VERSION "created by canmatrix"

NS_ :

BS_:

BU_: ARC ADC

BO_ 860 ARC_OD_22_23_RL: 64 ARC
 SG_ DistHeight_Obj_23_RL : 487|8@0+ (0.2,-10) [-10|41] "m"  ADC
 SG_ DistHeight_Obj_22_RL : 479|8@0+ (0.2,-10) [-10|41] "m"  ADC
 SG_ ARC_OD_DistX_Obj_22_RL : 7|12@0+ (0.1,-152) [-152|257.5] "m"  ADC
 SG_ ARC_OD_Classification_Obj_22_RL : 98|3@0+ (1,0) [0|7] ""  ADC
 SG_ ARC_OD_AabsYStd_Obj_22_RL : 111|8@0+ (0.25,0) [0|63.75] "m/s^2"  ADC
 SG_ ARC_OD_ClassConf_Obj_22_RL : 119|7@0+ (1,0) [0|127] "%"  ADC
 SG_ ARC_OD_ProbOfExist_Obj_22_RL : 112|7@0+ (1,0) [0|127] "%"  ADC
 SG_ ARC_OD_VabsX_Obj_22_RL : 11|11@0+ (0.125,-128) [-128|127.875] "m/s"  ADC
 SG_ ARC_OD_DynProp_Obj_22_RL : 130|3@0+ (1,0) [0|7] ""  ADC
 SG_ ARC_OD_Length_Obj_22_RL : 136|7@0+ (0.2,0) [0|25.4] "m"  ADC
 SG_ ARC_OD_MaintenanceState_Obj_0083 : 145|2@0+ (1,0) [0|3] ""  ADC
 SG_ ARC_OD_Width_Obj_22_RL : 159|7@0+ (0.2,0) [0|25.4] "m"  ADC
 SG_ ARC_OD_RCS_Obj_22_RL : 152|9@0+ (0.2,-51.1) [-51.1|51.1] "dBsm"  ADC
 SG_ ARC_OD_Orientation_Obj_22_RL : 175|10@0+ (0.01,-5.11) [-5.11|5.12] "rad"  ADC
 SG_ ARC_OD_LifeCycle_Obj_22_RL : 207|16@0+ (1,0) [0|65535] ""  ADC
 SG_ ARC_OD_DistX_Obj_23_RL : 223|12@0+ (0.1,-152) [-152|257.5] "m"  ADC
 SG_ ARC_OD_VabsX_Obj_23_RL : 227|11@0+ (0.125,-128) [-128|127.875] "m/s"  ADC
 SG_ ARC_OD_AabsX_Obj_23_RL : 232|9@0+ (0.125,-31.875) [-31.875|32] "m/s^2"  ADC
 SG_ ARC_OD_AabsX_Obj_22_RL : 16|9@0+ (0.125,-31.875) [-31.875|32] "m/s^2"  ADC
 SG_ ARC_OD_DistY_Obj_23_RL : 255|12@0+ (0.0875,-179.113) [-179.113|179.2] "m"  ADC
 SG_ ARC_OD_VabsY_Obj_23_RL : 259|11@0+ (0.125,-128) [-128|127.875] "m/s"  ADC
 SG_ ARC_OD_AabsY_Obj_23_RL : 264|9@0+ (0.125,-31.875) [-31.875|32] "m/s^2"  ADC
 SG_ ARC_OD_DistXStd_Obj_23_RL : 287|8@0+ (0.05,0) [0|12.75] "m"  ADC
 SG_ ARC_OD_DistYStd_Obj_23_RL : 295|8@0+ (0.1,0) [0|25.5] "m"  ADC
 SG_ ARC_OD_VabsXStd_Obj_23_RL : 303|7@0+ (0.1,0) [0|12.7] "m/s"  ADC
 SG_ ARC_OD_VabsYStd_Obj_23_RL : 296|7@0+ (0.2,0) [0|25.4] "m/s"  ADC
 SG_ ARC_OD_AabsXStd_Obj_23_RL : 305|7@0+ (0.25,0) [0|31.75] "m/s^2"  ADC
 SG_ ARC_OD_Classification_Obj_23_RL : 314|3@0+ (1,0) [0|7] ""  ADC
 SG_ ARC_OD_AabsYStd_Obj_23_RL : 327|8@0+ (0.25,0) [0|63.75] "m/s^2"  ADC
 SG_ ARC_OD_ClassConf_Obj_23_RL : 335|7@0+ (1,0) [0|127] "%"  ADC
 SG_ ARC_OD_DistY_Obj_22_RL : 39|12@0+ (0.0875,-179.113) [-179.113|179.2] "m"  ADC
 SG_ ARC_OD_ProbOfExist_Obj_23_RL : 328|7@0+ (1,0) [0|127] "%"  ADC
 SG_ ARC_OD_DynProp_Obj_23_RL : 346|3@0+ (1,0) [0|7] ""  ADC
 SG_ ARC_OD_Length_Obj_23_RL : 352|7@0+ (0.2,0) [0|25.4] "m"  ADC
 SG_ ARC_OD_MaintenanceState_Obj_0084 : 361|2@0+ (1,0) [0|3] ""  ADC
 SG_ ARC_OD_Width_Obj_23_RL : 375|7@0+ (0.2,0) [0|25.4] "m"  ADC
 SG_ ARC_OD_RCS_Obj_23_RL : 368|9@0+ (0.2,-51.1) [-51.1|51.1] "dBsm"  ADC
 SG_ ARC_OD_Orientation_Obj_23_RL : 391|10@0+ (0.01,-5.11) [-5.11|5.12] "rad"  ADC
 SG_ ARC_OD_LifeCycle_Obj_23_RL : 423|16@0+ (1,0) [0|65535] ""  ADC
 SG_ ARC_OD_ObstacleProb_Obj_22_RL : 447|7@0+ (1,0) [0|127] "%"  ADC
 SG_ ARC_OD_ObstacleProb_Obj_23_RL : 455|7@0+ (1,0) [0|127] "%"  ADC
 SG_ ARC_OD_VabsY_Obj_22_RL : 43|11@0+ (0.125,-128) [-128|127.875] "m/s"  ADC
 SG_ ARC_OD_ID_22_RL : 463|8@0+ (1,0) [0|255] ""  ADC
 SG_ ARC_OD_ID_23_RL : 471|8@0+ (1,0) [0|255] ""  ADC
 SG_ ARC_OD_MsgCounter_Obj_22_23_RL : 491|4@0+ (1,0) [0|15] ""  ADC
 SG_ ARC_OD_CRC8_Obj_22_23_RL : 511|8@0+ (1,0) [0|256] ""  ADC
 SG_ ARC_OD_AabsY_Obj_22_RL : 48|9@0+ (0.125,-31.875) [-31.875|32] "m/s^2"  ADC
 SG_ ARC_OD_DistXStd_Obj_22_RL : 71|8@0+ (0.05,0) [0|12.75] "m"  ADC
 SG_ ARC_OD_DistYStd_Obj_22_RL : 79|8@0+ (0.1,0) [0|25.5] "m"  ADC
 SG_ ARC_OD_VabsXStd_Obj_22_RL : 87|7@0+ (0.1,0) [0|12.7] "m/s"  ADC
 SG_ ARC_OD_VabsYStd_Obj_22_RL : 80|7@0+ (0.2,0) [0|25.4] "m/s"  ADC
 SG_ ARC_OD_AabsXStd_Obj_22_RL : 89|7@0+ (0.25,0) [0|31.75] "m/s^2"  ADC

BO_ 861 ARC_OD_24_25_RL: 64 ARC
 SG_ DistHeight_Obj_25_RL : 487|8@0+ (0.2,-10) [-10|41] "m"  ADC
 SG_ DistHeight_Obj_24_RL : 479|8@0+ (0.2,-10) [-10|41] "m"  ADC
 SG_ ARC_OD_DistX_Obj_24_RL : 7|12@0+ (0.1,-152) [-152|257.5] "m"  ADC
 SG_ ARC_OD_Classification_Obj_24_RL : 98|3@0+ (1,0) [0|7] ""  ADC
 SG_ ARC_OD_AabsYStd_Obj_24_RL : 111|8@0+ (0.25,0) [0|63.75] "m/s^2"  ADC
 SG_ ARC_OD_ClassConf_Obj_24_RL : 119|7@0+ (1,0) [0|127] "%"  ADC
 SG_ ARC_OD_ProbOfExist_Obj_24_RL : 112|7@0+ (1,0) [0|127] "%"  ADC
 SG_ ARC_OD_VabsX_Obj_24_RL : 11|11@0+ (0.125,-128) [-128|127.875] "m/s"  ADC
 SG_ ARC_OD_DynProp_Obj_24_RL : 130|3@0+ (1,0) [0|7] ""  ADC
 SG_ ARC_OD_Length_Obj_24_RL : 136|7@0+ (0.2,0) [0|25.4] "m"  ADC
 SG_ ARC_OD_MaintenanceState_Obj_0085 : 145|2@0+ (1,0) [0|3] ""  ADC
 SG_ ARC_OD_Width_Obj_24_RL : 159|7@0+ (0.2,0) [0|25.4] "m"  ADC
 SG_ ARC_OD_RCS_Obj_24_RL : 152|9@0+ (0.2,-51.1) [-51.1|51.1] "dBsm"  ADC
 SG_ ARC_OD_Orientation_Obj_24_RL : 175|10@0+ (0.01,-5.11) [-5.11|5.12] "rad"  ADC
 SG_ ARC_OD_LifeCycle_Obj_24_RL : 207|16@0+ (1,0) [0|65535] ""  ADC
 SG_ ARC_OD_DistX_Obj_25_RL : 223|12@0+ (0.1,-152) [-152|257.5] "m"  ADC
 SG_ ARC_OD_VabsX_Obj_25_RL : 227|11@0+ (0.125,-128) [-128|127.875] "m/s"  ADC
 SG_ ARC_OD_AabsX_Obj_25_RL : 232|9@0+ (0.125,-31.875) [-31.875|32] "m/s^2"  ADC
 SG_ ARC_OD_AabsX_Obj_24_RL : 16|9@0+ (0.125,-31.875) [-31.875|32] "m/s^2"  ADC
 SG_ ARC_OD_DistY_Obj_25_RL : 255|12@0+ (0.0875,-179.113) [-179.113|179.2] "m"  ADC
 SG_ ARC_OD_VabsY_Obj_25_RL : 259|11@0+ (0.125,-128) [-128|127.875] "m/s"  ADC
 SG_ ARC_OD_AabsY_Obj_25_RL : 264|9@0+ (0.125,-31.875) [-31.875|32] "m/s^2"  ADC
 SG_ ARC_OD_DistXStd_Obj_25_RL : 287|8@0+ (0.05,0) [0|12.75] "m"  ADC
 SG_ ARC_OD_DistYStd_Obj_25_RL : 295|8@0+ (0.1,0) [0|25.5] "m"  ADC
 SG_ ARC_OD_VabsXStd_Obj_25_RL : 303|7@0+ (0.1,0) [0|12.7] "m/s"  ADC
 SG_ ARC_OD_VabsYStd_Obj_25_RL : 296|7@0+ (0.2,0) [0|25.4] "m/s"  ADC
 SG_ ARC_OD_AabsXStd_Obj_25_RL : 305|7@0+ (0.25,0) [0|31.75] "m/s^2"  ADC
 SG_ ARC_OD_Classification_Obj_25_RL : 314|3@0+ (1,0) [0|7] ""  ADC
 SG_ ARC_OD_AabsYStd_Obj_25_RL : 327|8@0+ (0.25,0) [0|63.75] "m/s^2"  ADC
 SG_ ARC_OD_ClassConf_Obj_25_RL : 335|7@0+ (1,0) [0|127] "%"  ADC
 SG_ ARC_OD_DistY_Obj_24_RL : 39|12@0+ (0.0875,-179.113) [-179.113|179.2] "m"  ADC
 SG_ ARC_OD_ProbOfExist_Obj_25_RL : 328|7@0+ (1,0) [0|127] "%"  ADC
 SG_ ARC_OD_DynProp_Obj_25_RL : 346|3@0+ (1,0) [0|7] ""  ADC
 SG_ ARC_OD_Length_Obj_25_RL : 352|7@0+ (0.2,0) [0|25.4] "m"  ADC
 SG_ ARC_OD_MaintenanceState_Obj_0086 : 361|2@0+ (1,0) [0|3] ""  ADC
 SG_ ARC_OD_Width_Obj_25_RL : 375|7@0+ (0.2,0) [0|25.4] "m"  ADC
 SG_ ARC_OD_RCS_Obj_25_RL : 368|9@0+ (0.2,-51.1) [-51.1|51.1] "dBsm"  ADC
 SG_ ARC_OD_Orientation_Obj_25_RL : 391|10@0+ (0.01,-5.11) [-5.11|5.12] "rad"  ADC
 SG_ ARC_OD_LifeCycle_Obj_25_RL : 423|16@0+ (1,0) [0|65535] ""  ADC
 SG_ ARC_OD_ObstacleProb_Obj_24_RL : 447|7@0+ (1,0) [0|127] "%"  ADC
 SG_ ARC_OD_ObstacleProb_Obj_25_RL : 455|7@0+ (1,0) [0|127] "%"  ADC
 SG_ ARC_OD_VabsY_Obj_24_RL : 43|11@0+ (0.125,-128) [-128|127.875] "m/s"  ADC
 SG_ ARC_OD_ID_24_RL : 463|8@0+ (1,0) [0|255] ""  ADC
 SG_ ARC_OD_ID_25_RL : 471|8@0+ (1,0) [0|255] ""  ADC
 SG_ ARC_OD_MsgCounter_Obj_24_25_RL : 491|4@0+ (1,0) [0|15] ""  ADC
 SG_ ARC_OD_CRC8_Obj_24_25_RL : 511|8@0+ (1,0) [0|256] ""  ADC
 SG_ ARC_OD_AabsY_Obj_24_RL : 48|9@0+ (0.125,-31.875) [-31.875|32] "m/s^2"  ADC
 SG_ ARC_OD_DistXStd_Obj_24_RL : 71|8@0+ (0.05,0) [0|12.75] "m"  ADC
 SG_ ARC_OD_DistYStd_Obj_24_RL : 79|8@0+ (0.1,0) [0|25.5] "m"  ADC
 SG_ ARC_OD_VabsXStd_Obj_24_RL : 87|7@0+ (0.1,0) [0|12.7] "m/s"  ADC
 SG_ ARC_OD_VabsYStd_Obj_24_RL : 80|7@0+ (0.2,0) [0|25.4] "m/s"  ADC
 SG_ ARC_OD_AabsXStd_Obj_24_RL : 89|7@0+ (0.25,0) [0|31.75] "m/s^2"  ADC

BO_ 862 ARC_OD_26_27_RL: 64 ARC
 SG_ DistHeight_Obj_27_RL : 487|8@0+ (0.2,-10) [-10|41] "m"  ADC
 SG_ DistHeight_Obj_26_RL : 479|8@0+ (0.2,-10) [-10|41] "m"  ADC
 SG_ ARC_OD_DistX_Obj_26_RL : 7|12@0+ (0.1,-152) [-152|257.5] "m"  ADC
 SG_ ARC_OD_Classification_Obj_26_RL : 98|3@0+ (1,0) [0|7] ""  ADC
 SG_ ARC_OD_AabsYStd_Obj_26_RL : 111|8@0+ (0.25,0) [0|63.75] "m/s^2"  ADC
 SG_ ARC_OD_ClassConf_Obj_26_RL : 119|7@0+ (1,0) [0|127] "%"  ADC
 SG_ ARC_OD_ProbOfExist_Obj_26_RL : 112|7@0+ (1,0) [0|127] "%"  ADC
 SG_ ARC_OD_VabsX_Obj_26_RL : 11|11@0+ (0.125,-128) [-128|127.875] "m/s"  ADC
 SG_ ARC_OD_DynProp_Obj_26_RL : 130|3@0+ (1,0) [0|7] ""  ADC
 SG_ ARC_OD_Length_Obj_26_RL : 136|7@0+ (0.2,0) [0|25.4] "m"  ADC
 SG_ ARC_OD_MaintenanceState_Obj_0087 : 145|2@0+ (1,0) [0|3] ""  ADC
 SG_ ARC_OD_Width_Obj_26_RL : 159|7@0+ (0.2,0) [0|25.4] "m"  ADC
 SG_ ARC_OD_RCS_Obj_26_RL : 152|9@0+ (0.2,-51.1) [-51.1|51.1] "dBsm"  ADC
 SG_ ARC_OD_Orientation_Obj_26_RL : 175|10@0+ (0.01,-5.11) [-5.11|5.12] "rad"  ADC
 SG_ ARC_OD_LifeCycle_Obj_26_RL : 207|16@0+ (1,0) [0|65535] ""  ADC
 SG_ ARC_OD_DistX_Obj_27_RL : 223|12@0+ (0.1,-152) [-152|257.5] "m"  ADC
 SG_ ARC_OD_VabsX_Obj_27_RL : 227|11@0+ (0.125,-128) [-128|127.875] "m/s"  ADC
 SG_ ARC_OD_AabsX_Obj_27_RL : 232|9@0+ (0.125,-31.875) [-31.875|32] "m/s^2"  ADC
 SG_ ARC_OD_AabsX_Obj_26_RL : 16|9@0+ (0.125,-31.875) [-31.875|32] "m/s^2"  ADC
 SG_ ARC_OD_DistY_Obj_27_RL : 255|12@0+ (0.0875,-179.113) [-179.113|179.2] "m"  ADC
 SG_ ARC_OD_VabsY_Obj_27_RL : 259|11@0+ (0.125,-128) [-128|127.875] "m/s"  ADC
 SG_ ARC_OD_AabsY_Obj_27_RL : 264|9@0+ (0.125,-31.875) [-31.875|32] "m/s^2"  ADC
 SG_ ARC_OD_DistXStd_Obj_27_RL : 287|8@0+ (0.05,0) [0|12.75] "m"  ADC
 SG_ ARC_OD_DistYStd_Obj_27_RL : 295|8@0+ (0.1,0) [0|25.5] "m"  ADC
 SG_ ARC_OD_VabsXStd_Obj_27_RL : 303|7@0+ (0.1,0) [0|12.7] "m/s"  ADC
 SG_ ARC_OD_VabsYStd_Obj_27_RL : 296|7@0+ (0.2,0) [0|25.4] "m/s"  ADC
 SG_ ARC_OD_AabsXStd_Obj_27_RL : 305|7@0+ (0.25,0) [0|31.75] "m/s^2"  ADC
 SG_ ARC_OD_Classification_Obj_27_RL : 314|3@0+ (1,0) [0|7] ""  ADC
 SG_ ARC_OD_AabsYStd_Obj_27_RL : 327|8@0+ (0.25,0) [0|63.75] "m/s^2"  ADC
 SG_ ARC_OD_ClassConf_Obj_27_RL : 335|7@0+ (1,0) [0|127] "%"  ADC
 SG_ ARC_OD_DistY_Obj_26_RL : 39|12@0+ (0.0875,-179.113) [-179.113|179.2] "m"  ADC
 SG_ ARC_OD_ProbOfExist_Obj_27_RL : 328|7@0+ (1,0) [0|127] "%"  ADC
 SG_ ARC_OD_DynProp_Obj_27_RL : 346|3@0+ (1,0) [0|7] ""  ADC
 SG_ ARC_OD_Length_Obj_27_RL : 352|7@0+ (0.2,0) [0|25.4] "m"  ADC
 SG_ ARC_OD_MaintenanceState_Obj_0088 : 361|2@0+ (1,0) [0|3] ""  ADC
 SG_ ARC_OD_Width_Obj_27_RL : 375|7@0+ (0.2,0) [0|25.4] "m"  ADC
 SG_ ARC_OD_RCS_Obj_27_RL : 368|9@0+ (0.2,-51.1) [-51.1|51.1] "dBsm"  ADC
 SG_ ARC_OD_Orientation_Obj_27_RL : 391|10@0+ (0.01,-5.11) [-5.11|5.12] "rad"  ADC
 SG_ ARC_OD_LifeCycle_Obj_27_RL : 423|16@0+ (1,0) [0|65535] ""  ADC
 SG_ ARC_OD_ObstacleProb_Obj_26_RL : 447|7@0+ (1,0) [0|127] "%"  ADC
 SG_ ARC_OD_ObstacleProb_Obj_27_RL : 455|7@0+ (1,0) [0|127] "%"  ADC
 SG_ ARC_OD_VabsY_Obj_26_RL : 43|11@0+ (0.125,-128) [-128|127.875] "m/s"  ADC
 SG_ ARC_OD_ID_26_RL : 463|8@0+ (1,0) [0|255] ""  ADC
 SG_ ARC_OD_ID_27_RL : 471|8@0+ (1,0) [0|255] ""  ADC
 SG_ ARC_OD_MsgCounter_Obj_26_27_RL : 491|4@0+ (1,0) [0|15] ""  ADC
 SG_ ARC_OD_CRC8_Obj_26_27_RL : 511|8@0+ (1,0) [0|256] ""  ADC
 SG_ ARC_OD_AabsY_Obj_26_RL : 48|9@0+ (0.125,-31.875) [-31.875|32] "m/s^2"  ADC
 SG_ ARC_OD_DistXStd_Obj_26_RL : 71|8@0+ (0.05,0) [0|12.75] "m"  ADC
 SG_ ARC_OD_DistYStd_Obj_26_RL : 79|8@0+ (0.1,0) [0|25.5] "m"  ADC
 SG_ ARC_OD_VabsXStd_Obj_26_RL : 87|7@0+ (0.1,0) [0|12.7] "m/s"  ADC
 SG_ ARC_OD_VabsYStd_Obj_26_RL : 80|7@0+ (0.2,0) [0|25.4] "m/s"  ADC
 SG_ ARC_OD_AabsXStd_Obj_26_RL : 89|7@0+ (0.25,0) [0|31.75] "m/s^2"  ADC

BO_ 863 ARC_OD_28_29_RL: 64 ARC
 SG_ DistHeight_Obj_29_RL : 487|8@0+ (0.2,-10) [-10|41] "m"  ADC
 SG_ DistHeight_Obj_28_RL : 479|8@0+ (0.2,-10) [-10|41] "m"  ADC
 SG_ ARC_OD_DistX_Obj_28_RL : 7|12@0+ (0.1,-152) [-152|257.5] "m"  ADC
 SG_ ARC_OD_Classification_Obj_28_RL : 98|3@0+ (1,0) [0|7] ""  ADC
 SG_ ARC_OD_AabsYStd_Obj_28_RL : 111|8@0+ (0.25,0) [0|63.75] "m/s^2"  ADC
 SG_ ARC_OD_ClassConf_Obj_28_RL : 119|7@0+ (1,0) [0|127] "%"  ADC
 SG_ ARC_OD_ProbOfExist_Obj_28_RL : 112|7@0+ (1,0) [0|127] "%"  ADC
 SG_ ARC_OD_VabsX_Obj_28_RL : 11|11@0+ (0.125,-128) [-128|127.875] "m/s"  ADC
 SG_ ARC_OD_DynProp_Obj_28_RL : 130|3@0+ (1,0) [0|7] ""  ADC
 SG_ ARC_OD_Length_Obj_28_RL : 136|7@0+ (0.2,0) [0|25.4] "m"  ADC
 SG_ ARC_OD_MaintenanceState_Obj_0089 : 145|2@0+ (1,0) [0|3] ""  ADC
 SG_ ARC_OD_Width_Obj_28_RL : 159|7@0+ (0.2,0) [0|25.4] "m"  ADC
 SG_ ARC_OD_RCS_Obj_28_RL : 152|9@0+ (0.2,-51.1) [-51.1|51.1] "dBsm"  ADC
 SG_ ARC_OD_Orientation_Obj_28_RL : 175|10@0+ (0.01,-5.11) [-5.11|5.12] "rad"  ADC
 SG_ ARC_OD_LifeCycle_Obj_28_RL : 207|16@0+ (1,0) [0|65535] ""  ADC
 SG_ ARC_OD_DistX_Obj_29_RL : 223|12@0+ (0.1,-152) [-152|257.5] "m"  ADC
 SG_ ARC_OD_VabsX_Obj_29_RL : 227|11@0+ (0.125,-128) [-128|127.875] "m/s"  ADC
 SG_ ARC_OD_AabsX_Obj_29_RL : 232|9@0+ (0.125,-31.875) [-31.875|32] "m/s^2"  ADC
 SG_ ARC_OD_AabsX_Obj_28_RL : 16|9@0+ (0.125,-31.875) [-31.875|32] "m/s^2"  ADC
 SG_ ARC_OD_DistY_Obj_29_RL : 255|12@0+ (0.0875,-179.113) [-179.113|179.2] "m"  ADC
 SG_ ARC_OD_VabsY_Obj_29_RL : 259|11@0+ (0.125,-128) [-128|127.875] "m/s"  ADC
 SG_ ARC_OD_AabsY_Obj_29_RL : 264|9@0+ (0.125,-31.875) [-31.875|32] "m/s^2"  ADC
 SG_ ARC_OD_DistXStd_Obj_29_RL : 287|8@0+ (0.05,0) [0|12.75] "m"  ADC
 SG_ ARC_OD_DistYStd_Obj_29_RL : 295|8@0+ (0.1,0) [0|25.5] "m"  ADC
 SG_ ARC_OD_VabsXStd_Obj_29_RL : 303|7@0+ (0.1,0) [0|12.7] "m/s"  ADC
 SG_ ARC_OD_VabsYStd_Obj_29_RL : 296|7@0+ (0.2,0) [0|25.4] "m/s"  ADC
 SG_ ARC_OD_AabsXStd_Obj_29_RL : 305|7@0+ (0.25,0) [0|31.75] "m/s^2"  ADC
 SG_ ARC_OD_Classification_Obj_29_RL : 314|3@0+ (1,0) [0|7] ""  ADC
 SG_ ARC_OD_AabsYStd_Obj_29_RL : 327|8@0+ (0.25,0) [0|63.75] "m/s^2"  ADC
 SG_ ARC_OD_ClassConf_Obj_29_RL : 335|7@0+ (1,0) [0|127] "%"  ADC
 SG_ ARC_OD_DistY_Obj_28_RL : 39|12@0+ (0.0875,-179.113) [-179.113|179.2] "m"  ADC
 SG_ ARC_OD_ProbOfExist_Obj_29_RL : 328|7@0+ (1,0) [0|127] "%"  ADC
 SG_ ARC_OD_DynProp_Obj_29_RL : 346|3@0+ (1,0) [0|7] ""  ADC
 SG_ ARC_OD_Length_Obj_29_RL : 352|7@0+ (0.2,0) [0|25.4] "m"  ADC
 SG_ ARC_OD_MaintenanceState_Obj_0090 : 361|2@0+ (1,0) [0|3] ""  ADC
 SG_ ARC_OD_Width_Obj_29_RL : 375|7@0+ (0.2,0) [0|25.4] "m"  ADC
 SG_ ARC_OD_RCS_Obj_29_RL : 368|9@0+ (0.2,-51.1) [-51.1|51.1] "dBsm"  ADC
 SG_ ARC_OD_Orientation_Obj_29_RL : 391|10@0+ (0.01,-5.11) [-5.11|5.12] "rad"  ADC
 SG_ ARC_OD_LifeCycle_Obj_29_RL : 423|16@0+ (1,0) [0|65535] ""  ADC
 SG_ ARC_OD_ObstacleProb_Obj_28_RL : 447|7@0+ (1,0) [0|127] "%"  ADC
 SG_ ARC_OD_ObstacleProb_Obj_29_RL : 455|7@0+ (1,0) [0|127] "%"  ADC
 SG_ ARC_OD_VabsY_Obj_28_RL : 43|11@0+ (0.125,-128) [-128|127.875] "m/s"  ADC
 SG_ ARC_OD_ID_28_RL : 463|8@0+ (1,0) [0|255] ""  ADC
 SG_ ARC_OD_ID_29_RL : 471|8@0+ (1,0) [0|255] ""  ADC
 SG_ ARC_OD_MsgCounter_Obj_28_29_RL : 491|4@0+ (1,0) [0|15] ""  ADC
 SG_ ARC_OD_CRC8_Obj_28_29_RL : 511|8@0+ (1,0) [0|256] ""  ADC
 SG_ ARC_OD_AabsY_Obj_28_RL : 48|9@0+ (0.125,-31.875) [-31.875|32] "m/s^2"  ADC
 SG_ ARC_OD_DistXStd_Obj_28_RL : 71|8@0+ (0.05,0) [0|12.75] "m"  ADC
 SG_ ARC_OD_DistYStd_Obj_28_RL : 79|8@0+ (0.1,0) [0|25.5] "m"  ADC
 SG_ ARC_OD_VabsXStd_Obj_28_RL : 87|7@0+ (0.1,0) [0|12.7] "m/s"  ADC
 SG_ ARC_OD_VabsYStd_Obj_28_RL : 80|7@0+ (0.2,0) [0|25.4] "m/s"  ADC
 SG_ ARC_OD_AabsXStd_Obj_28_RL : 89|7@0+ (0.25,0) [0|31.75] "m/s^2"  ADC

BO_ 864 ARC_OD_30_31_RL: 64 ARC
 SG_ DistHeight_Obj_31_RL : 487|8@0+ (0.2,-10) [-10|41] "m"  ADC
 SG_ DistHeight_Obj_30_RL : 479|8@0+ (0.2,-10) [-10|41] "m"  ADC
 SG_ ARC_OD_DistX_Obj_30_RL : 7|12@0+ (0.1,-152) [-152|257.5] "m"  ADC
 SG_ ARC_OD_Classification_Obj_30_RL : 98|3@0+ (1,0) [0|7] ""  ADC
 SG_ ARC_OD_AabsYStd_Obj_30_RL : 111|8@0+ (0.25,0) [0|63.75] "m/s^2"  ADC
 SG_ ARC_OD_ClassConf_Obj_30_RL : 119|7@0+ (1,0) [0|127] "%"  ADC
 SG_ ARC_OD_ProbOfExist_Obj_30_RL : 112|7@0+ (1,0) [0|127] "%"  ADC
 SG_ ARC_OD_VabsX_Obj_30_RL : 11|11@0+ (0.125,-128) [-128|127.875] "m/s"  ADC
 SG_ ARC_OD_DynProp_Obj_30_RL : 130|3@0+ (1,0) [0|7] ""  ADC
 SG_ ARC_OD_Length_Obj_30_RL : 136|7@0+ (0.2,0) [0|25.4] "m"  ADC
 SG_ ARC_OD_MaintenanceState_Obj_0091 : 145|2@0+ (1,0) [0|3] ""  ADC
 SG_ ARC_OD_Width_Obj_30_RL : 159|7@0+ (0.2,0) [0|25.4] "m"  ADC
 SG_ ARC_OD_RCS_Obj_30_RL : 152|9@0+ (0.2,-51.1) [-51.1|51.1] "dBsm"  ADC
 SG_ ARC_OD_Orientation_Obj_30_RL : 175|10@0+ (0.01,-5.11) [-5.11|5.12] "rad"  ADC
 SG_ ARC_OD_LifeCycle_Obj_30_RL : 207|16@0+ (1,0) [0|65535] ""  ADC
 SG_ ARC_OD_DistX_Obj_31_RL : 223|12@0+ (0.1,-152) [-152|257.5] "m"  ADC
 SG_ ARC_OD_VabsX_Obj_31_RL : 227|11@0+ (0.125,-128) [-128|127.875] "m/s"  ADC
 SG_ ARC_OD_AabsX_Obj_31_RL : 232|9@0+ (0.125,-31.875) [-31.875|32] "m/s^2"  ADC
 SG_ ARC_OD_AabsX_Obj_30_RL : 16|9@0+ (0.125,-31.875) [-31.875|32] "m/s^2"  ADC
 SG_ ARC_OD_DistY_Obj_31_RL : 255|12@0+ (0.0875,-179.113) [-179.113|179.2] "m"  ADC
 SG_ ARC_OD_VabsY_Obj_31_RL : 259|11@0+ (0.125,-128) [-128|127.875] "m/s"  ADC
 SG_ ARC_OD_AabsY_Obj_31_RL : 264|9@0+ (0.125,-31.875) [-31.875|32] "m/s^2"  ADC
 SG_ ARC_OD_DistXStd_Obj_31_RL : 287|8@0+ (0.05,0) [0|12.75] "m"  ADC
 SG_ ARC_OD_DistYStd_Obj_31_RL : 295|8@0+ (0.1,0) [0|25.5] "m"  ADC
 SG_ ARC_OD_VabsXStd_Obj_31_RL : 303|7@0+ (0.1,0) [0|12.7] "m/s"  ADC
 SG_ ARC_OD_VabsYStd_Obj_31_RL : 296|7@0+ (0.2,0) [0|25.4] "m/s"  ADC
 SG_ ARC_OD_AabsXStd_Obj_31_RL : 305|7@0+ (0.25,0) [0|31.75] "m/s^2"  ADC
 SG_ ARC_OD_Classification_Obj_31_RL : 314|3@0+ (1,0) [0|7] ""  ADC
 SG_ ARC_OD_AabsYStd_Obj_31_RL : 327|8@0+ (0.25,0) [0|63.75] "m/s^2"  ADC
 SG_ ARC_OD_ClassConf_Obj_31_RL : 335|7@0+ (1,0) [0|127] "%"  ADC
 SG_ ARC_OD_DistY_Obj_30_RL : 39|12@0+ (0.0875,-179.113) [-179.113|179.2] "m"  ADC
 SG_ ARC_OD_ProbOfExist_Obj_31_RL : 328|7@0+ (1,0) [0|127] "%"  ADC
 SG_ ARC_OD_DynProp_Obj_31_RL : 346|3@0+ (1,0) [0|7] ""  ADC
 SG_ ARC_OD_Length_Obj_31_RL : 352|7@0+ (0.2,0) [0|25.4] "m"  ADC
 SG_ ARC_OD_MaintenanceState_Obj_0092 : 361|2@0+ (1,0) [0|3] ""  ADC
 SG_ ARC_OD_Width_Obj_31_RL : 375|7@0+ (0.2,0) [0|25.4] "m"  ADC
 SG_ ARC_OD_RCS_Obj_31_RL : 368|9@0+ (0.2,-51.1) [-51.1|51.1] "dBsm"  ADC
 SG_ ARC_OD_Orientation_Obj_31_RL : 391|10@0+ (0.01,-5.11) [-5.11|5.12] "rad"  ADC
 SG_ ARC_OD_LifeCycle_Obj_31_RL : 423|16@0+ (1,0) [0|65535] ""  ADC
 SG_ ARC_OD_ObstacleProb_Obj_30_RL : 447|7@0+ (1,0) [0|127] "%"  ADC
 SG_ ARC_OD_ObstacleProb_Obj_31_RL : 455|7@0+ (1,0) [0|127] "%"  ADC
 SG_ ARC_OD_VabsY_Obj_30_RL : 43|11@0+ (0.125,-128) [-128|127.875] "m/s"  ADC
 SG_ ARC_OD_ID_30_RL : 463|8@0+ (1,0) [0|255] ""  ADC
 SG_ ARC_OD_ID_31_RL : 471|8@0+ (1,0) [0|255] ""  ADC
 SG_ ARC_OD_MsgCounter_Obj_30_31_RL : 491|4@0+ (1,0) [0|15] ""  ADC
 SG_ ARC_OD_CRC8_Obj_30_31_RL : 511|8@0+ (1,0) [0|256] ""  ADC
 SG_ ARC_OD_AabsY_Obj_30_RL : 48|9@0+ (0.125,-31.875) [-31.875|32] "m/s^2"  ADC
 SG_ ARC_OD_DistXStd_Obj_30_RL : 71|8@0+ (0.05,0) [0|12.75] "m"  ADC
 SG_ ARC_OD_DistYStd_Obj_30_RL : 79|8@0+ (0.1,0) [0|25.5] "m"  ADC
 SG_ ARC_OD_VabsXStd_Obj_30_RL : 87|7@0+ (0.1,0) [0|12.7] "m/s"  ADC
 SG_ ARC_OD_VabsYStd_Obj_30_RL : 80|7@0+ (0.2,0) [0|25.4] "m/s"  ADC
 SG_ ARC_OD_AabsXStd_Obj_30_RL : 89|7@0+ (0.25,0) [0|31.75] "m/s^2"  ADC

BO_ 865 ARC_OD_32_33_RL: 64 ARC
 SG_ DistHeight_Obj_33_RL : 487|8@0+ (0.2,-10) [-10|41] "m"  ADC
 SG_ DistHeight_Obj_32_RL : 479|8@0+ (0.2,-10) [-10|41] "m"  ADC
 SG_ ARC_OD_DistX_Obj_32_RL : 7|12@0+ (0.1,-152) [-152|257.5] "m"  ADC
 SG_ ARC_OD_Classification_Obj_32_RL : 98|3@0+ (1,0) [0|7] ""  ADC
 SG_ ARC_OD_AabsYStd_Obj_32_RL : 111|8@0+ (0.25,0) [0|63.75] "m/s^2"  ADC
 SG_ ARC_OD_ClassConf_Obj_32_RL : 119|7@0+ (1,0) [0|127] "%"  ADC
 SG_ ARC_OD_ProbOfExist_Obj_32_RL : 112|7@0+ (1,0) [0|127] "%"  ADC
 SG_ ARC_OD_VabsX_Obj_32_RL : 11|11@0+ (0.125,-128) [-128|127.875] "m/s"  ADC
 SG_ ARC_OD_DynProp_Obj_32_RL : 130|3@0+ (1,0) [0|7] ""  ADC
 SG_ ARC_OD_Length_Obj_32_RL : 136|7@0+ (0.2,0) [0|25.4] "m"  ADC
 SG_ ARC_OD_MaintenanceState_Obj_0093 : 145|2@0+ (1,0) [0|3] ""  ADC
 SG_ ARC_OD_Width_Obj_32_RL : 159|7@0+ (0.2,0) [0|25.4] "m"  ADC
 SG_ ARC_OD_RCS_Obj_32_RL : 152|9@0+ (0.2,-51.1) [-51.1|51.1] "dBsm"  ADC
 SG_ ARC_OD_Orientation_Obj_32_RL : 175|10@0+ (0.01,-5.11) [-5.11|5.12] "rad"  ADC
 SG_ ARC_OD_LifeCycle_Obj_32_RL : 207|16@0+ (1,0) [0|65535] ""  ADC
 SG_ ARC_OD_DistX_Obj_33_RL : 223|12@0+ (0.1,-152) [-152|257.5] "m"  ADC
 SG_ ARC_OD_VabsX_Obj_33_RL : 227|11@0+ (0.125,-128) [-128|127.875] "m/s"  ADC
 SG_ ARC_OD_AabsX_Obj_33_RL : 232|9@0+ (0.125,-31.875) [-31.875|32] "m/s^2"  ADC
 SG_ ARC_OD_AabsX_Obj_32_RL : 16|9@0+ (0.125,-31.875) [-31.875|32] "m/s^2"  ADC
 SG_ ARC_OD_DistY_Obj_33_RL : 255|12@0+ (0.0875,-179.113) [-179.113|179.2] "m"  ADC
 SG_ ARC_OD_VabsY_Obj_33_RL : 259|11@0+ (0.125,-128) [-128|127.875] "m/s"  ADC
 SG_ ARC_OD_AabsY_Obj_33_RL : 264|9@0+ (0.125,-31.875) [-31.875|32] "m/s^2"  ADC
 SG_ ARC_OD_DistXStd_Obj_33_RL : 287|8@0+ (0.05,0) [0|12.75] "m"  ADC
 SG_ ARC_OD_DistYStd_Obj_33_RL : 295|8@0+ (0.1,0) [0|25.5] "m"  ADC
 SG_ ARC_OD_VabsXStd_Obj_33_RL : 303|7@0+ (0.1,0) [0|12.7] "m/s"  ADC
 SG_ ARC_OD_VabsYStd_Obj_33_RL : 296|7@0+ (0.2,0) [0|25.4] "m/s"  ADC
 SG_ ARC_OD_AabsXStd_Obj_33_RL : 305|7@0+ (0.25,0) [0|31.75] "m/s^2"  ADC
 SG_ ARC_OD_Classification_Obj_33_RL : 314|3@0+ (1,0) [0|7] ""  ADC
 SG_ ARC_OD_AabsYStd_Obj_33_RL : 327|8@0+ (0.25,0) [0|63.75] "m/s^2"  ADC
 SG_ ARC_OD_ClassConf_Obj_33_RL : 335|7@0+ (1,0) [0|127] "%"  ADC
 SG_ ARC_OD_DistY_Obj_32_RL : 39|12@0+ (0.0875,-179.113) [-179.113|179.2] "m"  ADC
 SG_ ARC_OD_ProbOfExist_Obj_33_RL : 328|7@0+ (1,0) [0|127] "%"  ADC
 SG_ ARC_OD_DynProp_Obj_33_RL : 346|3@0+ (1,0) [0|7] ""  ADC
 SG_ ARC_OD_Length_Obj_33_RL : 352|7@0+ (0.2,0) [0|25.4] "m"  ADC
 SG_ ARC_OD_MaintenanceState_Obj_0094 : 361|2@0+ (1,0) [0|3] ""  ADC
 SG_ ARC_OD_Width_Obj_33_RL : 375|7@0+ (0.2,0) [0|25.4] "m"  ADC
 SG_ ARC_OD_RCS_Obj_33_RL : 368|9@0+ (0.2,-51.1) [-51.1|51.1] "dBsm"  ADC
 SG_ ARC_OD_Orientation_Obj_33_RL : 391|10@0+ (0.01,-5.11) [-5.11|5.12] "rad"  ADC
 SG_ ARC_OD_LifeCycle_Obj_33_RL : 423|16@0+ (1,0) [0|65535] ""  ADC
 SG_ ARC_OD_ObstacleProb_Obj_32_RL : 447|7@0+ (1,0) [0|127] "%"  ADC
 SG_ ARC_OD_ObstacleProb_Obj_33_RL : 455|7@0+ (1,0) [0|127] "%"  ADC
 SG_ ARC_OD_VabsY_Obj_32_RL : 43|11@0+ (0.125,-128) [-128|127.875] "m/s"  ADC
 SG_ ARC_OD_ID_32_RL : 463|8@0+ (1,0) [0|255] ""  ADC
 SG_ ARC_OD_ID_33_RL : 471|8@0+ (1,0) [0|255] ""  ADC
 SG_ ARC_OD_MsgCounter_Obj_32_33_RL : 491|4@0+ (1,0) [0|15] ""  ADC
 SG_ ARC_OD_CRC8_Obj_32_33_RL : 511|8@0+ (1,0) [0|256] ""  ADC
 SG_ ARC_OD_AabsY_Obj_32_RL : 48|9@0+ (0.125,-31.875) [-31.875|32] "m/s^2"  ADC
 SG_ ARC_OD_DistXStd_Obj_32_RL : 71|8@0+ (0.05,0) [0|12.75] "m"  ADC
 SG_ ARC_OD_DistYStd_Obj_32_RL : 79|8@0+ (0.1,0) [0|25.5] "m"  ADC
 SG_ ARC_OD_VabsXStd_Obj_32_RL : 87|7@0+ (0.1,0) [0|12.7] "m/s"  ADC
 SG_ ARC_OD_VabsYStd_Obj_32_RL : 80|7@0+ (0.2,0) [0|25.4] "m/s"  ADC
 SG_ ARC_OD_AabsXStd_Obj_32_RL : 89|7@0+ (0.25,0) [0|31.75] "m/s^2"  ADC

BO_ 866 ARC_OD_34_35_RL: 64 ARC
 SG_ DistHeight_Obj_35_RL : 487|8@0+ (0.2,-10) [-10|41] "m"  ADC
 SG_ DistHeight_Obj_34_RL : 479|8@0+ (0.2,-10) [-10|41] "m"  ADC
 SG_ ARC_OD_DistX_Obj_34_RL : 7|12@0+ (0.1,-152) [-152|257.5] "m"  ADC
 SG_ ARC_OD_Classification_Obj_34_RL : 98|3@0+ (1,0) [0|7] ""  ADC
 SG_ ARC_OD_AabsYStd_Obj_34_RL : 111|8@0+ (0.25,0) [0|63.75] "m/s^2"  ADC
 SG_ ARC_OD_ClassConf_Obj_34_RL : 119|7@0+ (1,0) [0|127] "%"  ADC
 SG_ ARC_OD_ProbOfExist_Obj_34_RL : 112|7@0+ (1,0) [0|127] "%"  ADC
 SG_ ARC_OD_VabsX_Obj_34_RL : 11|11@0+ (0.125,-128) [-128|127.875] "m/s"  ADC
 SG_ ARC_OD_DynProp_Obj_34_RL : 130|3@0+ (1,0) [0|7] ""  ADC
 SG_ ARC_OD_Length_Obj_34_RL : 136|7@0+ (0.2,0) [0|25.4] "m"  ADC
 SG_ ARC_OD_MaintenanceState_Obj_0095 : 145|2@0+ (1,0) [0|3] ""  ADC
 SG_ ARC_OD_Width_Obj_34_RL : 159|7@0+ (0.2,0) [0|25.4] "m"  ADC
 SG_ ARC_OD_RCS_Obj_34_RL : 152|9@0+ (0.2,-51.1) [-51.1|51.1] "dBsm"  ADC
 SG_ ARC_OD_Orientation_Obj_34_RL : 175|10@0+ (0.01,-5.11) [-5.11|5.12] "rad"  ADC
 SG_ ARC_OD_LifeCycle_Obj_34_RL : 207|16@0+ (1,0) [0|65535] ""  ADC
 SG_ ARC_OD_DistX_Obj_35_RL : 223|12@0+ (0.1,-152) [-152|257.5] "m"  ADC
 SG_ ARC_OD_VabsX_Obj_35_RL : 227|11@0+ (0.125,-128) [-128|127.875] "m/s"  ADC
 SG_ ARC_OD_AabsX_Obj_35_RL : 232|9@0+ (0.125,-31.875) [-31.875|32] "m/s^2"  ADC
 SG_ ARC_OD_AabsX_Obj_34_RL : 16|9@0+ (0.125,-31.875) [-31.875|32] "m/s^2"  ADC
 SG_ ARC_OD_DistY_Obj_35_RL : 255|12@0+ (0.0875,-179.113) [-179.113|179.2] "m"  ADC
 SG_ ARC_OD_VabsY_Obj_35_RL : 259|11@0+ (0.125,-128) [-128|127.875] "m/s"  ADC
 SG_ ARC_OD_AabsY_Obj_35_RL : 264|9@0+ (0.125,-31.875) [-31.875|32] "m/s^2"  ADC
 SG_ ARC_OD_DistXStd_Obj_35_RL : 287|8@0+ (0.05,0) [0|12.75] "m"  ADC
 SG_ ARC_OD_DistYStd_Obj_35_RL : 295|8@0+ (0.1,0) [0|25.5] "m"  ADC
 SG_ ARC_OD_VabsXStd_Obj_35_RL : 303|7@0+ (0.1,0) [0|12.7] "m/s"  ADC
 SG_ ARC_OD_VabsYStd_Obj_35_RL : 296|7@0+ (0.2,0) [0|25.4] "m/s"  ADC
 SG_ ARC_OD_AabsXStd_Obj_35_RL : 305|7@0+ (0.25,0) [0|31.75] "m/s^2"  ADC
 SG_ ARC_OD_Classification_Obj_35_RL : 314|3@0+ (1,0) [0|7] ""  ADC
 SG_ ARC_OD_AabsYStd_Obj_35_RL : 327|8@0+ (0.25,0) [0|63.75] "m/s^2"  ADC
 SG_ ARC_OD_ClassConf_Obj_35_RL : 335|7@0+ (1,0) [0|127] "%"  ADC
 SG_ ARC_OD_DistY_Obj_34_RL : 39|12@0+ (0.0875,-179.113) [-179.113|179.2] "m"  ADC
 SG_ ARC_OD_ProbOfExist_Obj_35_RL : 328|7@0+ (1,0) [0|127] "%"  ADC
 SG_ ARC_OD_DynProp_Obj_35_RL : 346|3@0+ (1,0) [0|7] ""  ADC
 SG_ ARC_OD_Length_Obj_35_RL : 352|7@0+ (0.2,0) [0|25.4] "m"  ADC
 SG_ ARC_OD_MaintenanceState_Obj_0096 : 361|2@0+ (1,0) [0|3] ""  ADC
 SG_ ARC_OD_Width_Obj_35_RL : 375|7@0+ (0.2,0) [0|25.4] "m"  ADC
 SG_ ARC_OD_RCS_Obj_35_RL : 368|9@0+ (0.2,-51.1) [-51.1|51.1] "dBsm"  ADC
 SG_ ARC_OD_Orientation_Obj_35_RL : 391|10@0+ (0.01,-5.11) [-5.11|5.12] "rad"  ADC
 SG_ ARC_OD_LifeCycle_Obj_35_RL : 423|16@0+ (1,0) [0|65535] ""  ADC
 SG_ ARC_OD_ObstacleProb_Obj_34_RL : 447|7@0+ (1,0) [0|127] "%"  ADC
 SG_ ARC_OD_ObstacleProb_Obj_35_RL : 455|7@0+ (1,0) [0|127] "%"  ADC
 SG_ ARC_OD_VabsY_Obj_34_RL : 43|11@0+ (0.125,-128) [-128|127.875] "m/s"  ADC
 SG_ ARC_OD_ID_34_RL : 463|8@0+ (1,0) [0|255] ""  ADC
 SG_ ARC_OD_ID_35_RL : 471|8@0+ (1,0) [0|255] ""  ADC
 SG_ ARC_OD_MsgCounter_Obj_34_35_RL : 491|4@0+ (1,0) [0|15] ""  ADC
 SG_ ARC_OD_CRC8_Obj_34_35_RL : 511|8@0+ (1,0) [0|256] ""  ADC
 SG_ ARC_OD_AabsY_Obj_34_RL : 48|9@0+ (0.125,-31.875) [-31.875|32] "m/s^2"  ADC
 SG_ ARC_OD_DistXStd_Obj_34_RL : 71|8@0+ (0.05,0) [0|12.75] "m"  ADC
 SG_ ARC_OD_DistYStd_Obj_34_RL : 79|8@0+ (0.1,0) [0|25.5] "m"  ADC
 SG_ ARC_OD_VabsXStd_Obj_34_RL : 87|7@0+ (0.1,0) [0|12.7] "m/s"  ADC
 SG_ ARC_OD_VabsYStd_Obj_34_RL : 80|7@0+ (0.2,0) [0|25.4] "m/s"  ADC
 SG_ ARC_OD_AabsXStd_Obj_34_RL : 89|7@0+ (0.25,0) [0|31.75] "m/s^2"  ADC

BO_ 867 ARC_OD_36_37_RL: 64 ARC
 SG_ DistHeight_Obj_37_RL : 487|8@0+ (0.2,-10) [-10|41] "m"  ADC
 SG_ DistHeight_Obj_36_RL : 479|8@0+ (0.2,-10) [-10|41] "m"  ADC
 SG_ ARC_OD_DistX_Obj_36_RL : 7|12@0+ (0.1,-152) [-152|257.5] "m"  ADC
 SG_ ARC_OD_Classification_Obj_36_RL : 98|3@0+ (1,0) [0|7] ""  ADC
 SG_ ARC_OD_AabsYStd_Obj_36_RL : 111|8@0+ (0.25,0) [0|63.75] "m/s^2"  ADC
 SG_ ARC_OD_ClassConf_Obj_36_RL : 119|7@0+ (1,0) [0|127] "%"  ADC
 SG_ ARC_OD_ProbOfExist_Obj_36_RL : 112|7@0+ (1,0) [0|127] "%"  ADC
 SG_ ARC_OD_VabsX_Obj_36_RL : 11|11@0+ (0.125,-128) [-128|127.875] "m/s"  ADC
 SG_ ARC_OD_DynProp_Obj_36_RL : 130|3@0+ (1,0) [0|7] ""  ADC
 SG_ ARC_OD_Length_Obj_36_RL : 136|7@0+ (0.2,0) [0|25.4] "m"  ADC
 SG_ ARC_OD_MaintenanceState_Obj_0097 : 145|2@0+ (1,0) [0|3] ""  ADC
 SG_ ARC_OD_Width_Obj_36_RL : 159|7@0+ (0.2,0) [0|25.4] "m"  ADC
 SG_ ARC_OD_RCS_Obj_36_RL : 152|9@0+ (0.2,-51.1) [-51.1|51.1] "dBsm"  ADC
 SG_ ARC_OD_Orientation_Obj_36_RL : 175|10@0+ (0.01,-5.11) [-5.11|5.12] "rad"  ADC
 SG_ ARC_OD_LifeCycle_Obj_36_RL : 207|16@0+ (1,0) [0|65535] ""  ADC
 SG_ ARC_OD_DistX_Obj_37_RL : 223|12@0+ (0.1,-152) [-152|257.5] "m"  ADC
 SG_ ARC_OD_VabsX_Obj_37_RL : 227|11@0+ (0.125,-128) [-128|127.875] "m/s"  ADC
 SG_ ARC_OD_AabsX_Obj_37_RL : 232|9@0+ (0.125,-31.875) [-31.875|32] "m/s^2"  ADC
 SG_ ARC_OD_AabsX_Obj_36_RL : 16|9@0+ (0.125,-31.875) [-31.875|32] "m/s^2"  ADC
 SG_ ARC_OD_DistY_Obj_37_RL : 255|12@0+ (0.0875,-179.113) [-179.113|179.2] "m"  ADC
 SG_ ARC_OD_VabsY_Obj_37_RL : 259|11@0+ (0.125,-128) [-128|127.875] "m/s"  ADC
 SG_ ARC_OD_AabsY_Obj_37_RL : 264|9@0+ (0.125,-31.875) [-31.875|32] "m/s^2"  ADC
 SG_ ARC_OD_DistXStd_Obj_37_RL : 287|8@0+ (0.05,0) [0|12.75] "m"  ADC
 SG_ ARC_OD_DistYStd_Obj_37_RL : 295|8@0+ (0.1,0) [0|25.5] "m"  ADC
 SG_ ARC_OD_VabsXStd_Obj_37_RL : 303|7@0+ (0.1,0) [0|12.7] "m/s"  ADC
 SG_ ARC_OD_VabsYStd_Obj_37_RL : 296|7@0+ (0.2,0) [0|25.4] "m/s"  ADC
 SG_ ARC_OD_AabsXStd_Obj_37_RL : 305|7@0+ (0.25,0) [0|31.75] "m/s^2"  ADC
 SG_ ARC_OD_Classification_Obj_37_RL : 314|3@0+ (1,0) [0|7] ""  ADC
 SG_ ARC_OD_AabsYStd_Obj_37_RL : 327|8@0+ (0.25,0) [0|63.75] "m/s^2"  ADC
 SG_ ARC_OD_ClassConf_Obj_37_RL : 335|7@0+ (1,0) [0|127] "%"  ADC
 SG_ ARC_OD_DistY_Obj_36_RL : 39|12@0+ (0.0875,-179.113) [-179.113|179.2] "m"  ADC
 SG_ ARC_OD_ProbOfExist_Obj_37_RL : 328|7@0+ (1,0) [0|127] "%"  ADC
 SG_ ARC_OD_DynProp_Obj_37_RL : 346|3@0+ (1,0) [0|7] ""  ADC
 SG_ ARC_OD_Length_Obj_37_RL : 352|7@0+ (0.2,0) [0|25.4] "m"  ADC
 SG_ ARC_OD_MaintenanceState_Obj_0098 : 361|2@0+ (1,0) [0|3] ""  ADC
 SG_ ARC_OD_Width_Obj_37_RL : 375|7@0+ (0.2,0) [0|25.4] "m"  ADC
 SG_ ARC_OD_RCS_Obj_37_RL : 368|9@0+ (0.2,-51.1) [-51.1|51.1] "dBsm"  ADC
 SG_ ARC_OD_Orientation_Obj_37_RL : 391|10@0+ (0.01,-5.11) [-5.11|5.12] "rad"  ADC
 SG_ ARC_OD_LifeCycle_Obj_37_RL : 423|16@0+ (1,0) [0|65535] ""  ADC
 SG_ ARC_OD_ObstacleProb_Obj_36_RL : 447|7@0+ (1,0) [0|127] "%"  ADC
 SG_ ARC_OD_ObstacleProb_Obj_37_RL : 455|7@0+ (1,0) [0|127] "%"  ADC
 SG_ ARC_OD_VabsY_Obj_36_RL : 43|11@0+ (0.125,-128) [-128|127.875] "m/s"  ADC
 SG_ ARC_OD_ID_36_RL : 463|8@0+ (1,0) [0|255] ""  ADC
 SG_ ARC_OD_ID_37_RL : 471|8@0+ (1,0) [0|255] ""  ADC
 SG_ ARC_OD_MsgCounter_Obj_36_37_RL : 491|4@0+ (1,0) [0|15] ""  ADC
 SG_ ARC_OD_CRC8_Obj_36_37_RL : 511|8@0+ (1,0) [0|256] ""  ADC
 SG_ ARC_OD_AabsY_Obj_36_RL : 48|9@0+ (0.125,-31.875) [-31.875|32] "m/s^2"  ADC
 SG_ ARC_OD_DistXStd_Obj_36_RL : 71|8@0+ (0.05,0) [0|12.75] "m"  ADC
 SG_ ARC_OD_DistYStd_Obj_36_RL : 79|8@0+ (0.1,0) [0|25.5] "m"  ADC
 SG_ ARC_OD_VabsXStd_Obj_36_RL : 87|7@0+ (0.1,0) [0|12.7] "m/s"  ADC
 SG_ ARC_OD_VabsYStd_Obj_36_RL : 80|7@0+ (0.2,0) [0|25.4] "m/s"  ADC
 SG_ ARC_OD_AabsXStd_Obj_36_RL : 89|7@0+ (0.25,0) [0|31.75] "m/s^2"  ADC

BO_ 868 ARC_OD_38_39_RL: 64 ARC
 SG_ DistHeight_Obj_39_RL : 487|8@0+ (0.2,-10) [-10|41] "m"  ADC
 SG_ DistHeight_Obj_38_RL : 479|8@0+ (0.2,-10) [-10|41] "m"  ADC
 SG_ ARC_OD_DistX_Obj_38_RL : 7|12@0+ (0.1,-152) [-152|257.5] "m"  ADC
 SG_ ARC_OD_Classification_Obj_38_RL : 98|3@0+ (1,0) [0|7] ""  ADC
 SG_ ARC_OD_AabsYStd_Obj_38_RL : 111|8@0+ (0.25,0) [0|63.75] "m/s^2"  ADC
 SG_ ARC_OD_ClassConf_Obj_38_RL : 119|7@0+ (1,0) [0|127] "%"  ADC
 SG_ ARC_OD_ProbOfExist_Obj_38_RL : 112|7@0+ (1,0) [0|127] "%"  ADC
 SG_ ARC_OD_VabsX_Obj_38_RL : 11|11@0+ (0.125,-128) [-128|127.875] "m/s"  ADC
 SG_ ARC_OD_DynProp_Obj_38_RL : 130|3@0+ (1,0) [0|7] ""  ADC
 SG_ ARC_OD_Length_Obj_38_RL : 136|7@0+ (0.2,0) [0|25.4] "m"  ADC
 SG_ ARC_OD_MaintenanceState_Obj_0099 : 145|2@0+ (1,0) [0|3] ""  ADC
 SG_ ARC_OD_Width_Obj_38_RL : 159|7@0+ (0.2,0) [0|25.4] "m"  ADC
 SG_ ARC_OD_RCS_Obj_38_RL : 152|9@0+ (0.2,-51.1) [-51.1|51.1] "dBsm"  ADC
 SG_ ARC_OD_Orientation_Obj_38_RL : 175|10@0+ (0.01,-5.11) [-5.11|5.12] "rad"  ADC
 SG_ ARC_OD_LifeCycle_Obj_38_RL : 207|16@0+ (1,0) [0|65535] ""  ADC
 SG_ ARC_OD_DistX_Obj_39_RL : 223|12@0+ (0.1,-152) [-152|257.5] "m"  ADC
 SG_ ARC_OD_VabsX_Obj_39_RL : 227|11@0+ (0.125,-128) [-128|127.875] "m/s"  ADC
 SG_ ARC_OD_AabsX_Obj_39_RL : 232|9@0+ (0.125,-31.875) [-31.875|32] "m/s^2"  ADC
 SG_ ARC_OD_AabsX_Obj_38_RL : 16|9@0+ (0.125,-31.875) [-31.875|32] "m/s^2"  ADC
 SG_ ARC_OD_DistY_Obj_39_RL : 255|12@0+ (0.0875,-179.113) [-179.113|179.2] "m"  ADC
 SG_ ARC_OD_VabsY_Obj_39_RL : 259|11@0+ (0.125,-128) [-128|127.875] "m/s"  ADC
 SG_ ARC_OD_AabsY_Obj_39_RL : 264|9@0+ (0.125,-31.875) [-31.875|32] "m/s^2"  ADC
 SG_ ARC_OD_DistXStd_Obj_39_RL : 287|8@0+ (0.05,0) [0|12.75] "m"  ADC
 SG_ ARC_OD_DistYStd_Obj_39_RL : 295|8@0+ (0.1,0) [0|25.5] "m"  ADC
 SG_ ARC_OD_VabsXStd_Obj_39_RL : 303|7@0+ (0.1,0) [0|12.7] "m/s"  ADC
 SG_ ARC_OD_VabsYStd_Obj_39_RL : 296|7@0+ (0.2,0) [0|25.4] "m/s"  ADC
 SG_ ARC_OD_AabsXStd_Obj_39_RL : 305|7@0+ (0.25,0) [0|31.75] "m/s^2"  ADC
 SG_ ARC_OD_Classification_Obj_39_RL : 314|3@0+ (1,0) [0|7] ""  ADC
 SG_ ARC_OD_AabsYStd_Obj_39_RL : 327|8@0+ (0.25,0) [0|63.75] "m/s^2"  ADC
 SG_ ARC_OD_ClassConf_Obj_39_RL : 335|7@0+ (1,0) [0|127] "%"  ADC
 SG_ ARC_OD_DistY_Obj_38_RL : 39|12@0+ (0.0875,-179.113) [-179.113|179.2] "m"  ADC
 SG_ ARC_OD_ProbOfExist_Obj_39_RL : 328|7@0+ (1,0) [0|127] "%"  ADC
 SG_ ARC_OD_DynProp_Obj_39_RL : 346|3@0+ (1,0) [0|7] ""  ADC
 SG_ ARC_OD_Length_Obj_39_RL : 352|7@0+ (0.2,0) [0|25.4] "m"  ADC
 SG_ ARC_OD_MaintenanceState_Obj_0100 : 361|2@0+ (1,0) [0|3] ""  ADC
 SG_ ARC_OD_Width_Obj_39_RL : 375|7@0+ (0.2,0) [0|25.4] "m"  ADC
 SG_ ARC_OD_RCS_Obj_39_RL : 368|9@0+ (0.2,-51.1) [-51.1|51.1] "dBsm"  ADC
 SG_ ARC_OD_Orientation_Obj_39_RL : 391|10@0+ (0.01,-5.11) [-5.11|5.12] "rad"  ADC
 SG_ ARC_OD_LifeCycle_Obj_39_RL : 423|16@0+ (1,0) [0|65535] ""  ADC
 SG_ ARC_OD_ObstacleProb_Obj_38_RL : 447|7@0+ (1,0) [0|127] "%"  ADC
 SG_ ARC_OD_ObstacleProb_Obj_39_RL : 455|7@0+ (1,0) [0|127] "%"  ADC
 SG_ ARC_OD_VabsY_Obj_38_RL : 43|11@0+ (0.125,-128) [-128|127.875] "m/s"  ADC
 SG_ ARC_OD_ID_38_RL : 463|8@0+ (1,0) [0|255] ""  ADC
 SG_ ARC_OD_ID_39_RL : 471|8@0+ (1,0) [0|255] ""  ADC
 SG_ ARC_OD_MsgCounter_Obj_38_39_RL : 491|4@0+ (1,0) [0|15] ""  ADC
 SG_ ARC_OD_CRC8_Obj_38_39_RL : 511|8@0+ (1,0) [0|256] ""  ADC
 SG_ ARC_OD_AabsY_Obj_38_RL : 48|9@0+ (0.125,-31.875) [-31.875|32] "m/s^2"  ADC
 SG_ ARC_OD_DistXStd_Obj_38_RL : 71|8@0+ (0.05,0) [0|12.75] "m"  ADC
 SG_ ARC_OD_DistYStd_Obj_38_RL : 79|8@0+ (0.1,0) [0|25.5] "m"  ADC
 SG_ ARC_OD_VabsXStd_Obj_38_RL : 87|7@0+ (0.1,0) [0|12.7] "m/s"  ADC
 SG_ ARC_OD_VabsYStd_Obj_38_RL : 80|7@0+ (0.2,0) [0|25.4] "m/s"  ADC
 SG_ ARC_OD_AabsXStd_Obj_38_RL : 89|7@0+ (0.25,0) [0|31.75] "m/s^2"  ADC

BO_ 869 ARC_OD_40_41_RL: 64 ARC
 SG_ DistHeight_Obj_41_RL : 487|8@0+ (0.2,-10) [-10|41] "m"  ADC
 SG_ DistHeight_Obj_40_RL : 479|8@0+ (0.2,-10) [-10|41] "m"  ADC
 SG_ ARC_OD_DistX_Obj_40_RL : 7|12@0+ (0.1,-152) [-152|257.5] "m"  ADC
 SG_ ARC_OD_Classification_Obj_40_RL : 98|3@0+ (1,0) [0|7] ""  ADC
 SG_ ARC_OD_AabsYStd_Obj_40_RL : 111|8@0+ (0.25,0) [0|63.75] "m/s^2"  ADC
 SG_ ARC_OD_ClassConf_Obj_40_RL : 119|7@0+ (1,0) [0|127] "%"  ADC
 SG_ ARC_OD_ProbOfExist_Obj_40_RL : 112|7@0+ (1,0) [0|127] "%"  ADC
 SG_ ARC_OD_VabsX_Obj_40_RL : 11|11@0+ (0.125,-128) [-128|127.875] "m/s"  ADC
 SG_ ARC_OD_DynProp_Obj_40_RL : 130|3@0+ (1,0) [0|7] ""  ADC
 SG_ ARC_OD_Length_Obj_40_RL : 136|7@0+ (0.2,0) [0|25.4] "m"  ADC
 SG_ ARC_OD_MaintenanceState_Obj_0101 : 145|2@0+ (1,0) [0|3] ""  ADC
 SG_ ARC_OD_Width_Obj_40_RL : 159|7@0+ (0.2,0) [0|25.4] "m"  ADC
 SG_ ARC_OD_RCS_Obj_40_RL : 152|9@0+ (0.2,-51.1) [-51.1|51.1] "dBsm"  ADC
 SG_ ARC_OD_Orientation_Obj_40_RL : 175|10@0+ (0.01,-5.11) [-5.11|5.12] "rad"  ADC
 SG_ ARC_OD_LifeCycle_Obj_40_RL : 207|16@0+ (1,0) [0|65535] ""  ADC
 SG_ ARC_OD_DistX_Obj_41_RL : 223|12@0+ (0.1,-152) [-152|257.5] "m"  ADC
 SG_ ARC_OD_VabsX_Obj_41_RL : 227|11@0+ (0.125,-128) [-128|127.875] "m/s"  ADC
 SG_ ARC_OD_AabsX_Obj_41_RL : 232|9@0+ (0.125,-31.875) [-31.875|32] "m/s^2"  ADC
 SG_ ARC_OD_AabsX_Obj_40_RL : 16|9@0+ (0.125,-31.875) [-31.875|32] "m/s^2"  ADC
 SG_ ARC_OD_DistY_Obj_41_RL : 255|12@0+ (0.0875,-179.113) [-179.113|179.2] "m"  ADC
 SG_ ARC_OD_VabsY_Obj_41_RL : 259|11@0+ (0.125,-128) [-128|127.875] "m/s"  ADC
 SG_ ARC_OD_AabsY_Obj_41_RL : 264|9@0+ (0.125,-31.875) [-31.875|32] "m/s^2"  ADC
 SG_ ARC_OD_DistXStd_Obj_41_RL : 287|8@0+ (0.05,0) [0|12.75] "m"  ADC
 SG_ ARC_OD_DistYStd_Obj_41_RL : 295|8@0+ (0.1,0) [0|25.5] "m"  ADC
 SG_ ARC_OD_VabsXStd_Obj_41_RL : 303|7@0+ (0.1,0) [0|12.7] "m/s"  ADC
 SG_ ARC_OD_VabsYStd_Obj_41_RL : 296|7@0+ (0.2,0) [0|25.4] "m/s"  ADC
 SG_ ARC_OD_AabsXStd_Obj_41_RL : 305|7@0+ (0.25,0) [0|31.75] "m/s^2"  ADC
 SG_ ARC_OD_Classification_Obj_41_RL : 314|3@0+ (1,0) [0|7] ""  ADC
 SG_ ARC_OD_AabsYStd_Obj_41_RL : 327|8@0+ (0.25,0) [0|63.75] "m/s^2"  ADC
 SG_ ARC_OD_ClassConf_Obj_41_RL : 335|7@0+ (1,0) [0|127] "%"  ADC
 SG_ ARC_OD_DistY_Obj_40_RL : 39|12@0+ (0.0875,-179.113) [-179.113|179.2] "m"  ADC
 SG_ ARC_OD_ProbOfExist_Obj_41_RL : 328|7@0+ (1,0) [0|127] "%"  ADC
 SG_ ARC_OD_DynProp_Obj_41_RL : 346|3@0+ (1,0) [0|7] ""  ADC
 SG_ ARC_OD_Length_Obj_41_RL : 352|7@0+ (0.2,0) [0|25.4] "m"  ADC
 SG_ ARC_OD_MaintenanceState_Obj_0102 : 361|2@0+ (1,0) [0|3] ""  ADC
 SG_ ARC_OD_Width_Obj_41_RL : 375|7@0+ (0.2,0) [0|25.4] "m"  ADC
 SG_ ARC_OD_RCS_Obj_41_RL : 368|9@0+ (0.2,-51.1) [-51.1|51.1] "dBsm"  ADC
 SG_ ARC_OD_Orientation_Obj_41_RL : 391|10@0+ (0.01,-5.11) [-5.11|5.12] "rad"  ADC
 SG_ ARC_OD_LifeCycle_Obj_41_RL : 423|16@0+ (1,0) [0|65535] ""  ADC
 SG_ ARC_OD_ObstacleProb_Obj_40_RL : 447|7@0+ (1,0) [0|127] "%"  ADC
 SG_ ARC_OD_ObstacleProb_Obj_41_RL : 455|7@0+ (1,0) [0|127] "%"  ADC
 SG_ ARC_OD_VabsY_Obj_40_RL : 43|11@0+ (0.125,-128) [-128|127.875] "m/s"  ADC
 SG_ ARC_OD_ID_40_RL : 463|8@0+ (1,0) [0|255] ""  ADC
 SG_ ARC_OD_ID_41_RL : 471|8@0+ (1,0) [0|255] ""  ADC
 SG_ ARC_OD_MsgCounter_Obj_40_41_RL : 491|4@0+ (1,0) [0|15] ""  ADC
 SG_ ARC_OD_CRC8_Obj_40_41_RL : 511|8@0+ (1,0) [0|256] ""  ADC
 SG_ ARC_OD_AabsY_Obj_40_RL : 48|9@0+ (0.125,-31.875) [-31.875|32] "m/s^2"  ADC
 SG_ ARC_OD_DistXStd_Obj_40_RL : 71|8@0+ (0.05,0) [0|12.75] "m"  ADC
 SG_ ARC_OD_DistYStd_Obj_40_RL : 79|8@0+ (0.1,0) [0|25.5] "m"  ADC
 SG_ ARC_OD_VabsXStd_Obj_40_RL : 87|7@0+ (0.1,0) [0|12.7] "m/s"  ADC
 SG_ ARC_OD_VabsYStd_Obj_40_RL : 80|7@0+ (0.2,0) [0|25.4] "m/s"  ADC
 SG_ ARC_OD_AabsXStd_Obj_40_RL : 89|7@0+ (0.25,0) [0|31.75] "m/s^2"  ADC

BO_ 870 ARC_OD_42_43_RL: 64 ARC
 SG_ DistHeight_Obj_43_RL : 487|8@0+ (0.2,-10) [-10|41] "m" Vector__XXX
 SG_ DistHeight_Obj_42_RL : 479|8@0+ (0.2,-10) [-10|41] "m" Vector__XXX
 SG_ ARC_OD_DistX_Obj_42_RL : 7|12@0+ (0.1,-152) [-152|257.5] "m"  ADC
 SG_ ARC_OD_Classification_Obj_42_RL : 98|3@0+ (1,0) [0|7] ""  ADC
 SG_ ARC_OD_AabsYStd_Obj_42_RL : 111|8@0+ (0.25,0) [0|63.75] "m/s^2"  ADC
 SG_ ARC_OD_ClassConf_Obj_42_RL : 119|7@0+ (1,0) [0|127] "%"  ADC
 SG_ ARC_OD_ProbOfExist_Obj_42_RL : 112|7@0+ (1,0) [0|127] "%"  ADC
 SG_ ARC_OD_VabsX_Obj_42_RL : 11|11@0+ (0.125,-128) [-128|127.875] "m/s"  ADC
 SG_ ARC_OD_DynProp_Obj_42_RL : 130|3@0+ (1,0) [0|7] ""  ADC
 SG_ ARC_OD_Length_Obj_42_RL : 136|7@0+ (0.2,0) [0|25.4] "m"  ADC
 SG_ ARC_OD_MaintenanceState_Obj_0103 : 145|2@0+ (1,0) [0|3] ""  ADC
 SG_ ARC_OD_Width_Obj_42_RL : 159|7@0+ (0.2,0) [0|25.4] "m"  ADC
 SG_ ARC_OD_RCS_Obj_42_RL : 152|9@0+ (0.2,-51.1) [-51.1|51.1] "dBsm"  ADC
 SG_ ARC_OD_Orientation_Obj_42_RL : 175|10@0+ (0.01,-5.11) [-5.11|5.12] "rad"  ADC
 SG_ ARC_OD_LifeCycle_Obj_42_RL : 207|16@0+ (1,0) [0|65535] ""  ADC
 SG_ ARC_OD_DistX_Obj_43_RL : 223|12@0+ (0.1,-152) [-152|257.5] "m"  ADC
 SG_ ARC_OD_VabsX_Obj_43_RL : 227|11@0+ (0.125,-128) [-128|127.875] "m/s"  ADC
 SG_ ARC_OD_AabsX_Obj_43_RL : 232|9@0+ (0.125,-31.875) [-31.875|32] "m/s^2"  ADC
 SG_ ARC_OD_AabsX_Obj_42_RL : 16|9@0+ (0.125,-31.875) [-31.875|32] "m/s^2"  ADC
 SG_ ARC_OD_DistY_Obj_43_RL : 255|12@0+ (0.0875,-179.113) [-179.113|179.2] "m"  ADC
 SG_ ARC_OD_VabsY_Obj_43_RL : 259|11@0+ (0.125,-128) [-128|127.875] "m/s"  ADC
 SG_ ARC_OD_AabsY_Obj_43_RL : 264|9@0+ (0.125,-31.875) [-31.875|32] "m/s^2"  ADC
 SG_ ARC_OD_DistXStd_Obj_43_RL : 287|8@0+ (0.05,0) [0|12.75] "m"  ADC
 SG_ ARC_OD_DistYStd_Obj_43_RL : 295|8@0+ (0.1,0) [0|25.5] "m"  ADC
 SG_ ARC_OD_VabsXStd_Obj_43_RL : 303|7@0+ (0.1,0) [0|12.7] "m/s"  ADC
 SG_ ARC_OD_VabsYStd_Obj_43_RL : 296|7@0+ (0.2,0) [0|25.4] "m/s"  ADC
 SG_ ARC_OD_AabsXStd_Obj_43_RL : 305|7@0+ (0.25,0) [0|31.75] "m/s^2"  ADC
 SG_ ARC_OD_Classification_Obj_43_RL : 314|3@0+ (1,0) [0|7] ""  ADC
 SG_ ARC_OD_AabsYStd_Obj_43_RL : 327|8@0+ (0.25,0) [0|63.75] "m/s^2"  ADC
 SG_ ARC_OD_ClassConf_Obj_43_RL : 335|7@0+ (1,0) [0|127] "%"  ADC
 SG_ ARC_OD_DistY_Obj_42_RL : 39|12@0+ (0.0875,-179.113) [-179.113|179.2] "m"  ADC
 SG_ ARC_OD_ProbOfExist_Obj_43_RL : 328|7@0+ (1,0) [0|127] "%"  ADC
 SG_ ARC_OD_DynProp_Obj_43_RL : 346|3@0+ (1,0) [0|7] ""  ADC
 SG_ ARC_OD_Length_Obj_43_RL : 352|7@0+ (0.2,0) [0|25.4] "m"  ADC
 SG_ ARC_OD_MaintenanceState_Obj_0104 : 361|2@0+ (1,0) [0|3] ""  ADC
 SG_ ARC_OD_Width_Obj_43_RL : 375|7@0+ (0.2,0) [0|25.4] "m"  ADC
 SG_ ARC_OD_RCS_Obj_43_RL : 368|9@0+ (0.2,-51.1) [-51.1|51.1] "dBsm"  ADC
 SG_ ARC_OD_Orientation_Obj_43_RL : 391|10@0+ (0.01,-5.11) [-5.11|5.12] "rad"  ADC
 SG_ ARC_OD_LifeCycle_Obj_43_RL : 423|16@0+ (1,0) [0|65535] ""  ADC
 SG_ ARC_OD_ObstacleProb_Obj_42_RL : 447|7@0+ (1,0) [0|127] "%"  ADC
 SG_ ARC_OD_ObstacleProb_Obj_43_RL : 455|7@0+ (1,0) [0|127] "%"  ADC
 SG_ ARC_OD_VabsY_Obj_42_RL : 43|11@0+ (0.125,-128) [-128|127.875] "m/s"  ADC
 SG_ ARC_OD_ID_42_RL : 463|8@0+ (1,0) [0|255] ""  ADC
 SG_ ARC_OD_ID_43_RL : 471|8@0+ (1,0) [0|255] ""  ADC
 SG_ ARC_OD_MsgCounter_Obj_42_43_RL : 491|4@0+ (1,0) [0|15] ""  ADC
 SG_ ARC_OD_CRC8_Obj_42_43_RL : 511|8@0+ (1,0) [0|256] ""  ADC
 SG_ ARC_OD_AabsY_Obj_42_RL : 48|9@0+ (0.125,-31.875) [-31.875|32] "m/s^2"  ADC
 SG_ ARC_OD_DistXStd_Obj_42_RL : 71|8@0+ (0.05,0) [0|12.75] "m"  ADC
 SG_ ARC_OD_DistYStd_Obj_42_RL : 79|8@0+ (0.1,0) [0|25.5] "m"  ADC
 SG_ ARC_OD_VabsXStd_Obj_42_RL : 87|7@0+ (0.1,0) [0|12.7] "m/s"  ADC
 SG_ ARC_OD_VabsYStd_Obj_42_RL : 80|7@0+ (0.2,0) [0|25.4] "m/s"  ADC
 SG_ ARC_OD_AabsXStd_Obj_42_RL : 89|7@0+ (0.25,0) [0|31.75] "m/s^2"  ADC

BO_ 871 ARC_OD_44_45_RL: 64 ARC
 SG_ DistHeight_Obj_45_RL : 487|8@0+ (0.2,-10) [-10|41] "m" Vector__XXX
 SG_ DistHeight_Obj_44_RL : 479|8@0+ (0.2,-10) [-10|41] "m" Vector__XXX
 SG_ ARC_OD_DistX_Obj_44_RL : 7|12@0+ (0.1,-152) [-152|257.5] "m"  ADC
 SG_ ARC_OD_Classification_Obj_44_RL : 98|3@0+ (1,0) [0|7] ""  ADC
 SG_ ARC_OD_AabsYStd_Obj_44_RL : 111|8@0+ (0.25,0) [0|63.75] "m/s^2"  ADC
 SG_ ARC_OD_ClassConf_Obj_44_RL : 119|7@0+ (1,0) [0|127] "%"  ADC
 SG_ ARC_OD_ProbOfExist_Obj_44_RL : 112|7@0+ (1,0) [0|127] "%"  ADC
 SG_ ARC_OD_VabsX_Obj_44_RL : 11|11@0+ (0.125,-128) [-128|127.875] "m/s"  ADC
 SG_ ARC_OD_DynProp_Obj_44_RL : 130|3@0+ (1,0) [0|7] ""  ADC
 SG_ ARC_OD_Length_Obj_44_RL : 136|7@0+ (0.2,0) [0|25.4] "m"  ADC
 SG_ ARC_OD_MaintenanceState_Obj_0105 : 145|2@0+ (1,0) [0|3] ""  ADC
 SG_ ARC_OD_Width_Obj_44_RL : 159|7@0+ (0.2,0) [0|25.4] "m"  ADC
 SG_ ARC_OD_RCS_Obj_44_RL : 152|9@0+ (0.2,-51.1) [-51.1|51.1] "dBsm"  ADC
 SG_ ARC_OD_Orientation_Obj_44_RL : 175|10@0+ (0.01,-5.11) [-5.11|5.12] "rad"  ADC
 SG_ ARC_OD_LifeCycle_Obj_44_RL : 207|16@0+ (1,0) [0|65535] ""  ADC
 SG_ ARC_OD_DistX_Obj_45_RL : 223|12@0+ (0.1,-152) [-152|257.5] "m"  ADC
 SG_ ARC_OD_VabsX_Obj_45_RL : 227|11@0+ (0.125,-128) [-128|127.875] "m/s"  ADC
 SG_ ARC_OD_AabsX_Obj_45_RL : 232|9@0+ (0.125,-31.875) [-31.875|32] "m/s^2"  ADC
 SG_ ARC_OD_AabsX_Obj_44_RL : 16|9@0+ (0.125,-31.875) [-31.875|32] "m/s^2"  ADC
 SG_ ARC_OD_DistY_Obj_45_RL : 255|12@0+ (0.0875,-179.113) [-179.113|179.2] "m"  ADC
 SG_ ARC_OD_VabsY_Obj_45_RL : 259|11@0+ (0.125,-128) [-128|127.875] "m/s"  ADC
 SG_ ARC_OD_AabsY_Obj_45_RL : 264|9@0+ (0.125,-31.875) [-31.875|32] "m/s^2"  ADC
 SG_ ARC_OD_DistXStd_Obj_45_RL : 287|8@0+ (0.05,0) [0|12.75] "m"  ADC
 SG_ ARC_OD_DistYStd_Obj_45_RL : 295|8@0+ (0.1,0) [0|25.5] "m"  ADC
 SG_ ARC_OD_VabsXStd_Obj_45_RL : 303|7@0+ (0.1,0) [0|12.7] "m/s"  ADC
 SG_ ARC_OD_VabsYStd_Obj_45_RL : 296|7@0+ (0.2,0) [0|25.4] "m/s"  ADC
 SG_ ARC_OD_AabsXStd_Obj_45_RL : 305|7@0+ (0.25,0) [0|31.75] "m/s^2"  ADC
 SG_ ARC_OD_Classification_Obj_45_RL : 314|3@0+ (1,0) [0|7] ""  ADC
 SG_ ARC_OD_AabsYStd_Obj_45_RL : 327|8@0+ (0.25,0) [0|63.75] "m/s^2"  ADC
 SG_ ARC_OD_ClassConf_Obj_45_RL : 335|7@0+ (1,0) [0|127] "%"  ADC
 SG_ ARC_OD_DistY_Obj_44_RL : 39|12@0+ (0.0875,-179.113) [-179.113|179.2] "m"  ADC
 SG_ ARC_OD_ProbOfExist_Obj_45_RL : 328|7@0+ (1,0) [0|127] "%"  ADC
 SG_ ARC_OD_DynProp_Obj_45_RL : 346|3@0+ (1,0) [0|7] ""  ADC
 SG_ ARC_OD_Length_Obj_45_RL : 352|7@0+ (0.2,0) [0|25.4] "m"  ADC
 SG_ ARC_OD_MaintenanceState_Obj_0106 : 361|2@0+ (1,0) [0|3] ""  ADC
 SG_ ARC_OD_Width_Obj_45_RL : 375|7@0+ (0.2,0) [0|25.4] "m"  ADC
 SG_ ARC_OD_RCS_Obj_45_RL : 368|9@0+ (0.2,-51.1) [-51.1|51.1] "dBsm"  ADC
 SG_ ARC_OD_Orientation_Obj_45_RL : 391|10@0+ (0.01,-5.11) [-5.11|5.12] "rad"  ADC
 SG_ ARC_OD_LifeCycle_Obj_45_RL : 423|16@0+ (1,0) [0|65535] ""  ADC
 SG_ ARC_OD_ObstacleProb_Obj_44_RL : 447|7@0+ (1,0) [0|127] "%"  ADC
 SG_ ARC_OD_ObstacleProb_Obj_45_RL : 455|7@0+ (1,0) [0|127] "%"  ADC
 SG_ ARC_OD_VabsY_Obj_44_RL : 43|11@0+ (0.125,-128) [-128|127.875] "m/s"  ADC
 SG_ ARC_OD_ID_44_RL : 463|8@0+ (1,0) [0|255] ""  ADC
 SG_ ARC_OD_ID_45_RL : 471|8@0+ (1,0) [0|255] ""  ADC
 SG_ ARC_OD_MsgCounter_Obj_44_45_RL : 491|4@0+ (1,0) [0|15] ""  ADC
 SG_ ARC_OD_CRC8_Obj_44_45_RL : 511|8@0+ (1,0) [0|256] ""  ADC
 SG_ ARC_OD_AabsY_Obj_44_RL : 48|9@0+ (0.125,-31.875) [-31.875|32] "m/s^2"  ADC
 SG_ ARC_OD_DistXStd_Obj_44_RL : 71|8@0+ (0.05,0) [0|12.75] "m"  ADC
 SG_ ARC_OD_DistYStd_Obj_44_RL : 79|8@0+ (0.1,0) [0|25.5] "m"  ADC
 SG_ ARC_OD_VabsXStd_Obj_44_RL : 87|7@0+ (0.1,0) [0|12.7] "m/s"  ADC
 SG_ ARC_OD_VabsYStd_Obj_44_RL : 80|7@0+ (0.2,0) [0|25.4] "m/s"  ADC
 SG_ ARC_OD_AabsXStd_Obj_44_RL : 89|7@0+ (0.25,0) [0|31.75] "m/s^2"  ADC

BO_ 872 ARC_OD_46_47_RL: 64 ARC
 SG_ DistHeight_Obj_47_RL : 487|8@0+ (0.2,-10) [-10|41] "m" Vector__XXX
 SG_ DistHeight_Obj_46_RL : 479|8@0+ (0.2,-10) [-10|41] "m" Vector__XXX
 SG_ ARC_OD_DistX_Obj_46_RL : 7|12@0+ (0.1,-152) [-152|257.5] "m"  ADC
 SG_ ARC_OD_Classification_Obj_46_RL : 98|3@0+ (1,0) [0|7] ""  ADC
 SG_ ARC_OD_AabsYStd_Obj_46_RL : 111|8@0+ (0.25,0) [0|63.75] "m/s^2"  ADC
 SG_ ARC_OD_ClassConf_Obj_46_RL : 119|7@0+ (1,0) [0|127] "%"  ADC
 SG_ ARC_OD_ProbOfExist_Obj_46_RL : 112|7@0+ (1,0) [0|127] "%"  ADC
 SG_ ARC_OD_VabsX_Obj_46_RL : 11|11@0+ (0.125,-128) [-128|127.875] "m/s"  ADC
 SG_ ARC_OD_DynProp_Obj_46_RL : 130|3@0+ (1,0) [0|7] ""  ADC
 SG_ ARC_OD_Length_Obj_46_RL : 136|7@0+ (0.2,0) [0|25.4] "m"  ADC
 SG_ ARC_OD_MaintenanceState_Obj_0107 : 145|2@0+ (1,0) [0|3] ""  ADC
 SG_ ARC_OD_Width_Obj_46_RL : 159|7@0+ (0.2,0) [0|25.4] "m"  ADC
 SG_ ARC_OD_RCS_Obj_46_RL : 152|9@0+ (0.2,-51.1) [-51.1|51.1] "dBsm"  ADC
 SG_ ARC_OD_Orientation_Obj_46_RL : 175|10@0+ (0.01,-5.11) [-5.11|5.12] "rad"  ADC
 SG_ ARC_OD_LifeCycle_Obj_46_RL : 207|16@0+ (1,0) [0|65535] ""  ADC
 SG_ ARC_OD_DistX_Obj_47_RL : 223|12@0+ (0.1,-152) [-152|257.5] "m"  ADC
 SG_ ARC_OD_VabsX_Obj_47_RL : 227|11@0+ (0.125,-128) [-128|127.875] "m/s"  ADC
 SG_ ARC_OD_AabsX_Obj_47_RL : 232|9@0+ (0.125,-31.875) [-31.875|32] "m/s^2"  ADC
 SG_ ARC_OD_AabsX_Obj_46_RL : 16|9@0+ (0.125,-31.875) [-31.875|32] "m/s^2"  ADC
 SG_ ARC_OD_DistY_Obj_47_RL : 255|12@0+ (0.0875,-179.113) [-179.113|179.2] "m"  ADC
 SG_ ARC_OD_VabsY_Obj_47_RL : 259|11@0+ (0.125,-128) [-128|127.875] "m/s"  ADC
 SG_ ARC_OD_AabsY_Obj_47_RL : 264|9@0+ (0.125,-31.875) [-31.875|32] "m/s^2"  ADC
 SG_ ARC_OD_DistXStd_Obj_47_RL : 287|8@0+ (0.05,0) [0|12.75] "m"  ADC
 SG_ ARC_OD_DistYStd_Obj_47_RL : 295|8@0+ (0.1,0) [0|25.5] "m"  ADC
 SG_ ARC_OD_VabsXStd_Obj_47_RL : 303|7@0+ (0.1,0) [0|12.7] "m/s"  ADC
 SG_ ARC_OD_VabsYStd_Obj_47_RL : 296|7@0+ (0.2,0) [0|25.4] "m/s"  ADC
 SG_ ARC_OD_AabsXStd_Obj_47_RL : 305|7@0+ (0.25,0) [0|31.75] "m/s^2"  ADC
 SG_ ARC_OD_Classification_Obj_47_RL : 314|3@0+ (1,0) [0|7] ""  ADC
 SG_ ARC_OD_AabsYStd_Obj_47_RL : 327|8@0+ (0.25,0) [0|63.75] "m/s^2"  ADC
 SG_ ARC_OD_ClassConf_Obj_47_RL : 335|7@0+ (1,0) [0|127] "%"  ADC
 SG_ ARC_OD_DistY_Obj_46_RL : 39|12@0+ (0.0875,-179.113) [-179.113|179.2] "m"  ADC
 SG_ ARC_OD_ProbOfExist_Obj_47_RL : 328|7@0+ (1,0) [0|127] "%"  ADC
 SG_ ARC_OD_DynProp_Obj_47_RL : 346|3@0+ (1,0) [0|7] ""  ADC
 SG_ ARC_OD_Length_Obj_47_RL : 352|7@0+ (0.2,0) [0|25.4] "m"  ADC
 SG_ ARC_OD_MaintenanceState_Obj_0108 : 361|2@0+ (1,0) [0|3] ""  ADC
 SG_ ARC_OD_Width_Obj_47_RL : 375|7@0+ (0.2,0) [0|25.4] "m"  ADC
 SG_ ARC_OD_RCS_Obj_47_RL : 368|9@0+ (0.2,-51.1) [-51.1|51.1] "dBsm"  ADC
 SG_ ARC_OD_Orientation_Obj_47_RL : 391|10@0+ (0.01,-5.11) [-5.11|5.12] "rad"  ADC
 SG_ ARC_OD_LifeCycle_Obj_47_RL : 423|16@0+ (1,0) [0|65535] ""  ADC
 SG_ ARC_OD_ObstacleProb_Obj_46_RL : 447|7@0+ (1,0) [0|127] "%"  ADC
 SG_ ARC_OD_ObstacleProb_Obj_47_RL : 455|7@0+ (1,0) [0|127] "%"  ADC
 SG_ ARC_OD_VabsY_Obj_46_RL : 43|11@0+ (0.125,-128) [-128|127.875] "m/s"  ADC
 SG_ ARC_OD_ID_46_RL : 463|8@0+ (1,0) [0|255] ""  ADC
 SG_ ARC_OD_ID_47_RL : 471|8@0+ (1,0) [0|255] ""  ADC
 SG_ ARC_OD_MsgCounter_Obj_46_47_RL : 491|4@0+ (1,0) [0|15] ""  ADC
 SG_ ARC_OD_CRC8_Obj_46_47_RL : 511|8@0+ (1,0) [0|256] ""  ADC
 SG_ ARC_OD_AabsY_Obj_46_RL : 48|9@0+ (0.125,-31.875) [-31.875|32] "m/s^2"  ADC
 SG_ ARC_OD_DistXStd_Obj_46_RL : 71|8@0+ (0.05,0) [0|12.75] "m"  ADC
 SG_ ARC_OD_DistYStd_Obj_46_RL : 79|8@0+ (0.1,0) [0|25.5] "m"  ADC
 SG_ ARC_OD_VabsXStd_Obj_46_RL : 87|7@0+ (0.1,0) [0|12.7] "m/s"  ADC
 SG_ ARC_OD_VabsYStd_Obj_46_RL : 80|7@0+ (0.2,0) [0|25.4] "m/s"  ADC
 SG_ ARC_OD_AabsXStd_Obj_46_RL : 89|7@0+ (0.25,0) [0|31.75] "m/s^2"  ADC

BO_ 873 ARC_OD_48_49_RL: 64 ARC
 SG_ DistHeight_Obj_49_RL : 487|8@0+ (0.2,-10) [-10|41] "m" Vector__XXX
 SG_ DistHeight_Obj_48_RL : 479|8@0+ (0.2,-10) [-10|41] "m" Vector__XXX
 SG_ ARC_OD_DistX_Obj_48_RL : 7|12@0+ (0.1,-152) [-152|257.5] "m"  ADC
 SG_ ARC_OD_Classification_Obj_48_RL : 98|3@0+ (1,0) [0|7] ""  ADC
 SG_ ARC_OD_AabsYStd_Obj_48_RL : 111|8@0+ (0.25,0) [0|63.75] "m/s^2"  ADC
 SG_ ARC_OD_ClassConf_Obj_48_RL : 119|7@0+ (1,0) [0|127] "%"  ADC
 SG_ ARC_OD_ProbOfExist_Obj_48_RL : 112|7@0+ (1,0) [0|127] "%"  ADC
 SG_ ARC_OD_VabsX_Obj_48_RL : 11|11@0+ (0.125,-128) [-128|127.875] "m/s"  ADC
 SG_ ARC_OD_DynProp_Obj_48_RL : 130|3@0+ (1,0) [0|7] ""  ADC
 SG_ ARC_OD_Length_Obj_48_RL : 136|7@0+ (0.2,0) [0|25.4] "m"  ADC
 SG_ ARC_OD_MaintenanceState_Obj_0109 : 145|2@0+ (1,0) [0|3] ""  ADC
 SG_ ARC_OD_Width_Obj_48_RL : 159|7@0+ (0.2,0) [0|25.4] "m"  ADC
 SG_ ARC_OD_RCS_Obj_48_RL : 152|9@0+ (0.2,-51.1) [-51.1|51.1] "dBsm"  ADC
 SG_ ARC_OD_Orientation_Obj_48_RL : 175|10@0+ (0.01,-5.11) [-5.11|5.12] "rad"  ADC
 SG_ ARC_OD_LifeCycle_Obj_48_RL : 207|16@0+ (1,0) [0|65535] ""  ADC
 SG_ ARC_OD_DistX_Obj_49_RL : 223|12@0+ (0.1,-152) [-152|257.5] "m"  ADC
 SG_ ARC_OD_VabsX_Obj_49_RL : 227|11@0+ (0.125,-128) [-128|127.875] "m/s"  ADC
 SG_ ARC_OD_AabsX_Obj_49_RL : 232|9@0+ (0.125,-31.875) [-31.875|32] "m/s^2"  ADC
 SG_ ARC_OD_AabsX_Obj_48_RL : 16|9@0+ (0.125,-31.875) [-31.875|32] "m/s^2"  ADC
 SG_ ARC_OD_DistY_Obj_49_RL : 255|12@0+ (0.0875,-179.113) [-179.113|179.2] "m"  ADC
 SG_ ARC_OD_VabsY_Obj_49_RL : 259|11@0+ (0.125,-128) [-128|127.875] "m/s"  ADC
 SG_ ARC_OD_AabsY_Obj_49_RL : 264|9@0+ (0.125,-31.875) [-31.875|32] "m/s^2"  ADC
 SG_ ARC_OD_DistXStd_Obj_49_RL : 287|8@0+ (0.05,0) [0|12.75] "m"  ADC
 SG_ ARC_OD_DistYStd_Obj_49_RL : 295|8@0+ (0.1,0) [0|25.5] "m"  ADC
 SG_ ARC_OD_VabsXStd_Obj_49_RL : 303|7@0+ (0.1,0) [0|12.7] "m/s"  ADC
 SG_ ARC_OD_VabsYStd_Obj_49_RL : 296|7@0+ (0.2,0) [0|25.4] "m/s"  ADC
 SG_ ARC_OD_AabsXStd_Obj_49_RL : 305|7@0+ (0.25,0) [0|31.75] "m/s^2"  ADC
 SG_ ARC_OD_Classification_Obj_49_RL : 314|3@0+ (1,0) [0|7] ""  ADC
 SG_ ARC_OD_AabsYStd_Obj_49_RL : 327|8@0+ (0.25,0) [0|63.75] "m/s^2"  ADC
 SG_ ARC_OD_ClassConf_Obj_49_RL : 335|7@0+ (1,0) [0|127] "%"  ADC
 SG_ ARC_OD_DistY_Obj_48_RL : 39|12@0+ (0.0875,-179.113) [-179.113|179.2] "m"  ADC
 SG_ ARC_OD_ProbOfExist_Obj_49_RL : 328|7@0+ (1,0) [0|127] "%"  ADC
 SG_ ARC_OD_DynProp_Obj_49_RL : 346|3@0+ (1,0) [0|7] ""  ADC
 SG_ ARC_OD_Length_Obj_49_RL : 352|7@0+ (0.2,0) [0|25.4] "m"  ADC
 SG_ ARC_OD_MaintenanceState_Obj_0110 : 361|2@0+ (1,0) [0|3] ""  ADC
 SG_ ARC_OD_Width_Obj_49_RL : 375|7@0+ (0.2,0) [0|25.4] "m"  ADC
 SG_ ARC_OD_RCS_Obj_49_RL : 368|9@0+ (0.2,-51.1) [-51.1|51.1] "dBsm"  ADC
 SG_ ARC_OD_Orientation_Obj_49_RL : 391|10@0+ (0.01,-5.11) [-5.11|5.12] "rad"  ADC
 SG_ ARC_OD_LifeCycle_Obj_49_RL : 423|16@0+ (1,0) [0|65535] ""  ADC
 SG_ ARC_OD_ObstacleProb_Obj_48_RL : 447|7@0+ (1,0) [0|127] "%"  ADC
 SG_ ARC_OD_ObstacleProb_Obj_49_RL : 455|7@0+ (1,0) [0|127] "%"  ADC
 SG_ ARC_OD_VabsY_Obj_48_RL : 43|11@0+ (0.125,-128) [-128|127.875] "m/s"  ADC
 SG_ ARC_OD_ID_48_RL : 463|8@0+ (1,0) [0|255] ""  ADC
 SG_ ARC_OD_ID_49_RL : 471|8@0+ (1,0) [0|255] ""  ADC
 SG_ ARC_OD_MsgCounter_Obj_48_49_RL : 491|4@0+ (1,0) [0|15] ""  ADC
 SG_ ARC_OD_CRC8_Obj_48_49_RL : 511|8@0+ (1,0) [0|256] ""  ADC
 SG_ ARC_OD_AabsY_Obj_48_RL : 48|9@0+ (0.125,-31.875) [-31.875|32] "m/s^2"  ADC
 SG_ ARC_OD_DistXStd_Obj_48_RL : 71|8@0+ (0.05,0) [0|12.75] "m"  ADC
 SG_ ARC_OD_DistYStd_Obj_48_RL : 79|8@0+ (0.1,0) [0|25.5] "m"  ADC
 SG_ ARC_OD_VabsXStd_Obj_48_RL : 87|7@0+ (0.1,0) [0|12.7] "m/s"  ADC
 SG_ ARC_OD_VabsYStd_Obj_48_RL : 80|7@0+ (0.2,0) [0|25.4] "m/s"  ADC
 SG_ ARC_OD_AabsXStd_Obj_48_RL : 89|7@0+ (0.25,0) [0|31.75] "m/s^2"  ADC

BO_ 874 ARC_OD_50_51_RL: 64 ARC
 SG_ DistHeight_Obj_51_RL : 487|8@0+ (0.2,-10) [-10|41] "m" Vector__XXX
 SG_ DistHeight_Obj_50_RL : 479|8@0+ (0.2,-10) [-10|41] "m" Vector__XXX
 SG_ ARC_OD_DistX_Obj_50_RL : 7|12@0+ (0.1,-152) [-152|257.5] "m"  ADC
 SG_ ARC_OD_Classification_Obj_50_RL : 98|3@0+ (1,0) [0|7] ""  ADC
 SG_ ARC_OD_AabsYStd_Obj_50_RL : 111|8@0+ (0.25,0) [0|63.75] "m/s^2"  ADC
 SG_ ARC_OD_ClassConf_Obj_50_RL : 119|7@0+ (1,0) [0|127] "%"  ADC
 SG_ ARC_OD_ProbOfExist_Obj_50_RL : 112|7@0+ (1,0) [0|127] "%"  ADC
 SG_ ARC_OD_VabsX_Obj_50_RL : 11|11@0+ (0.125,-128) [-128|127.875] "m/s"  ADC
 SG_ ARC_OD_DynProp_Obj_50_RL : 130|3@0+ (1,0) [0|7] ""  ADC
 SG_ ARC_OD_Length_Obj_50_RL : 136|7@0+ (0.2,0) [0|25.4] "m"  ADC
 SG_ ARC_OD_MaintenanceState_Obj_0111 : 145|2@0+ (1,0) [0|3] ""  ADC
 SG_ ARC_OD_Width_Obj_50_RL : 159|7@0+ (0.2,0) [0|25.4] "m"  ADC
 SG_ ARC_OD_RCS_Obj_50_RL : 152|9@0+ (0.2,-51.1) [-51.1|51.1] "dBsm"  ADC
 SG_ ARC_OD_Orientation_Obj_50_RL : 175|10@0+ (0.01,-5.11) [-5.11|5.12] "rad"  ADC
 SG_ ARC_OD_LifeCycle_Obj_50_RL : 207|16@0+ (1,0) [0|65535] ""  ADC
 SG_ ARC_OD_DistX_Obj_51_RL : 223|12@0+ (0.1,-152) [-152|257.5] "m"  ADC
 SG_ ARC_OD_VabsX_Obj_51_RL : 227|11@0+ (0.125,-128) [-128|127.875] "m/s"  ADC
 SG_ ARC_OD_AabsX_Obj_51_RL : 232|9@0+ (0.125,-31.875) [-31.875|32] "m/s^2"  ADC
 SG_ ARC_OD_AabsX_Obj_50_RL : 16|9@0+ (0.125,-31.875) [-31.875|32] "m/s^2"  ADC
 SG_ ARC_OD_DistY_Obj_51_RL : 255|12@0+ (0.0875,-179.113) [-179.113|179.2] "m"  ADC
 SG_ ARC_OD_VabsY_Obj_51_RL : 259|11@0+ (0.125,-128) [-128|127.875] "m/s"  ADC
 SG_ ARC_OD_AabsY_Obj_51_RL : 264|9@0+ (0.125,-31.875) [-31.875|32] "m/s^2"  ADC
 SG_ ARC_OD_DistXStd_Obj_51_RL : 287|8@0+ (0.05,0) [0|12.75] "m"  ADC
 SG_ ARC_OD_DistYStd_Obj_51_RL : 295|8@0+ (0.1,0) [0|25.5] "m"  ADC
 SG_ ARC_OD_VabsXStd_Obj_51_RL : 303|7@0+ (0.1,0) [0|12.7] "m/s"  ADC
 SG_ ARC_OD_VabsYStd_Obj_51_RL : 296|7@0+ (0.2,0) [0|25.4] "m/s"  ADC
 SG_ ARC_OD_AabsXStd_Obj_51_RL : 305|7@0+ (0.25,0) [0|31.75] "m/s^2"  ADC
 SG_ ARC_OD_Classification_Obj_51_RL : 314|3@0+ (1,0) [0|7] ""  ADC
 SG_ ARC_OD_AabsYStd_Obj_51_RL : 327|8@0+ (0.25,0) [0|63.75] "m/s^2"  ADC
 SG_ ARC_OD_ClassConf_Obj_51_RL : 335|7@0+ (1,0) [0|127] "%"  ADC
 SG_ ARC_OD_DistY_Obj_50_RL : 39|12@0+ (0.0875,-179.113) [-179.113|179.2] "m"  ADC
 SG_ ARC_OD_ProbOfExist_Obj_51_RL : 328|7@0+ (1,0) [0|127] "%"  ADC
 SG_ ARC_OD_DynProp_Obj_51_RL : 346|3@0+ (1,0) [0|7] ""  ADC
 SG_ ARC_OD_Length_Obj_51_RL : 352|7@0+ (0.2,0) [0|25.4] "m"  ADC
 SG_ ARC_OD_MaintenanceState_Obj_0112 : 361|2@0+ (1,0) [0|3] ""  ADC
 SG_ ARC_OD_Width_Obj_51_RL : 375|7@0+ (0.2,0) [0|25.4] "m"  ADC
 SG_ ARC_OD_RCS_Obj_51_RL : 368|9@0+ (0.2,-51.1) [-51.1|51.1] "dBsm"  ADC
 SG_ ARC_OD_Orientation_Obj_51_RL : 391|10@0+ (0.01,-5.11) [-5.11|5.12] "rad"  ADC
 SG_ ARC_OD_LifeCycle_Obj_51_RL : 423|16@0+ (1,0) [0|65535] ""  ADC
 SG_ ARC_OD_ObstacleProb_Obj_50_RL : 447|7@0+ (1,0) [0|127] "%"  ADC
 SG_ ARC_OD_ObstacleProb_Obj_51_RL : 455|7@0+ (1,0) [0|127] "%"  ADC
 SG_ ARC_OD_VabsY_Obj_50_RL : 43|11@0+ (0.125,-128) [-128|127.875] "m/s"  ADC
 SG_ ARC_OD_ID_50_RL : 463|8@0+ (1,0) [0|255] ""  ADC
 SG_ ARC_OD_ID_51_RL : 471|8@0+ (1,0) [0|255] ""  ADC
 SG_ ARC_OD_MsgCounter_Obj_50_51_RL : 491|4@0+ (1,0) [0|15] ""  ADC
 SG_ ARC_OD_CRC8_Obj_50_51_RL : 511|8@0+ (1,0) [0|256] ""  ADC
 SG_ ARC_OD_AabsY_Obj_50_RL : 48|9@0+ (0.125,-31.875) [-31.875|32] "m/s^2"  ADC
 SG_ ARC_OD_DistXStd_Obj_50_RL : 71|8@0+ (0.05,0) [0|12.75] "m"  ADC
 SG_ ARC_OD_DistYStd_Obj_50_RL : 79|8@0+ (0.1,0) [0|25.5] "m"  ADC
 SG_ ARC_OD_VabsXStd_Obj_50_RL : 87|7@0+ (0.1,0) [0|12.7] "m/s"  ADC
 SG_ ARC_OD_VabsYStd_Obj_50_RL : 80|7@0+ (0.2,0) [0|25.4] "m/s"  ADC
 SG_ ARC_OD_AabsXStd_Obj_50_RL : 89|7@0+ (0.25,0) [0|31.75] "m/s^2"  ADC

BO_ 875 ARC_OD_52_53_RL: 64 ARC
 SG_ DistHeight_Obj_53_RL : 487|8@0+ (0.2,-10) [-10|41] "m" Vector__XXX
 SG_ DistHeight_Obj_52_RL : 479|8@0+ (0.2,-10) [-10|41] "m" Vector__XXX
 SG_ ARC_OD_DistX_Obj_52_RL : 7|12@0+ (0.1,-152) [-152|257.5] "m"  ADC
 SG_ ARC_OD_Classification_Obj_52_RL : 98|3@0+ (1,0) [0|7] ""  ADC
 SG_ ARC_OD_AabsYStd_Obj_52_RL : 111|8@0+ (0.25,0) [0|63.75] "m/s^2"  ADC
 SG_ ARC_OD_ClassConf_Obj_52_RL : 119|7@0+ (1,0) [0|127] "%"  ADC
 SG_ ARC_OD_ProbOfExist_Obj_52_RL : 112|7@0+ (1,0) [0|127] "%"  ADC
 SG_ ARC_OD_VabsX_Obj_52_RL : 11|11@0+ (0.125,-128) [-128|127.875] "m/s"  ADC
 SG_ ARC_OD_DynProp_Obj_52_RL : 130|3@0+ (1,0) [0|7] ""  ADC
 SG_ ARC_OD_Length_Obj_52_RL : 136|7@0+ (0.2,0) [0|25.4] "m"  ADC
 SG_ ARC_OD_MaintenanceState_Obj_0113 : 145|2@0+ (1,0) [0|3] ""  ADC
 SG_ ARC_OD_Width_Obj_52_RL : 159|7@0+ (0.2,0) [0|25.4] "m"  ADC
 SG_ ARC_OD_RCS_Obj_52_RL : 152|9@0+ (0.2,-51.1) [-51.1|51.1] "dBsm"  ADC
 SG_ ARC_OD_Orientation_Obj_52_RL : 175|10@0+ (0.01,-5.11) [-5.11|5.12] "rad"  ADC
 SG_ ARC_OD_LifeCycle_Obj_52_RL : 207|16@0+ (1,0) [0|65535] ""  ADC
 SG_ ARC_OD_DistX_Obj_53_RL : 223|12@0+ (0.1,-152) [-152|257.5] "m"  ADC
 SG_ ARC_OD_VabsX_Obj_53_RL : 227|11@0+ (0.125,-128) [-128|127.875] "m/s"  ADC
 SG_ ARC_OD_AabsX_Obj_53_RL : 232|9@0+ (0.125,-31.875) [-31.875|32] "m/s^2"  ADC
 SG_ ARC_OD_AabsX_Obj_52_RL : 16|9@0+ (0.125,-31.875) [-31.875|32] "m/s^2"  ADC
 SG_ ARC_OD_DistY_Obj_53_RL : 255|12@0+ (0.0875,-179.113) [-179.113|179.2] "m"  ADC
 SG_ ARC_OD_VabsY_Obj_53_RL : 259|11@0+ (0.125,-128) [-128|127.875] "m/s"  ADC
 SG_ ARC_OD_AabsY_Obj_53_RL : 264|9@0+ (0.125,-31.875) [-31.875|32] "m/s^2"  ADC
 SG_ ARC_OD_DistXStd_Obj_53_RL : 287|8@0+ (0.05,0) [0|12.75] "m"  ADC
 SG_ ARC_OD_DistYStd_Obj_53_RL : 295|8@0+ (0.1,0) [0|25.5] "m"  ADC
 SG_ ARC_OD_VabsXStd_Obj_53_RL : 303|7@0+ (0.1,0) [0|12.7] "m/s"  ADC
 SG_ ARC_OD_VabsYStd_Obj_53_RL : 296|7@0+ (0.2,0) [0|25.4] "m/s"  ADC
 SG_ ARC_OD_AabsXStd_Obj_53_RL : 305|7@0+ (0.25,0) [0|31.75] "m/s^2"  ADC
 SG_ ARC_OD_Classification_Obj_53_RL : 314|3@0+ (1,0) [0|7] ""  ADC
 SG_ ARC_OD_AabsYStd_Obj_53_RL : 327|8@0+ (0.25,0) [0|63.75] "m/s^2"  ADC
 SG_ ARC_OD_ClassConf_Obj_53_RL : 335|7@0+ (1,0) [0|127] "%"  ADC
 SG_ ARC_OD_DistY_Obj_52_RL : 39|12@0+ (0.0875,-179.113) [-179.113|179.2] "m"  ADC
 SG_ ARC_OD_ProbOfExist_Obj_53_RL : 328|7@0+ (1,0) [0|127] "%"  ADC
 SG_ ARC_OD_DynProp_Obj_53_RL : 346|3@0+ (1,0) [0|7] ""  ADC
 SG_ ARC_OD_Length_Obj_53_RL : 352|7@0+ (0.2,0) [0|25.4] "m"  ADC
 SG_ ARC_OD_MaintenanceState_Obj_0114 : 361|2@0+ (1,0) [0|3] ""  ADC
 SG_ ARC_OD_Width_Obj_53_RL : 375|7@0+ (0.2,0) [0|25.4] "m"  ADC
 SG_ ARC_OD_RCS_Obj_53_RL : 368|9@0+ (0.2,-51.1) [-51.1|51.1] "dBsm"  ADC
 SG_ ARC_OD_Orientation_Obj_53_RL : 391|10@0+ (0.01,-5.11) [-5.11|5.12] "rad"  ADC
 SG_ ARC_OD_LifeCycle_Obj_53_RL : 423|16@0+ (1,0) [0|65535] ""  ADC
 SG_ ARC_OD_ObstacleProb_Obj_52_RL : 447|7@0+ (1,0) [0|127] "%"  ADC
 SG_ ARC_OD_ObstacleProb_Obj_53_RL : 455|7@0+ (1,0) [0|127] "%"  ADC
 SG_ ARC_OD_VabsY_Obj_52_RL : 43|11@0+ (0.125,-128) [-128|127.875] "m/s"  ADC
 SG_ ARC_OD_ID_52_RL : 463|8@0+ (1,0) [0|255] ""  ADC
 SG_ ARC_OD_ID_53_RL : 471|8@0+ (1,0) [0|255] ""  ADC
 SG_ ARC_OD_MsgCounter_Obj_52_53_RL : 491|4@0+ (1,0) [0|15] ""  ADC
 SG_ ARC_OD_CRC8_Obj_52_53_RL : 511|8@0+ (1,0) [0|256] ""  ADC
 SG_ ARC_OD_AabsY_Obj_52_RL : 48|9@0+ (0.125,-31.875) [-31.875|32] "m/s^2"  ADC
 SG_ ARC_OD_DistXStd_Obj_52_RL : 71|8@0+ (0.05,0) [0|12.75] "m"  ADC
 SG_ ARC_OD_DistYStd_Obj_52_RL : 79|8@0+ (0.1,0) [0|25.5] "m"  ADC
 SG_ ARC_OD_VabsXStd_Obj_52_RL : 87|7@0+ (0.1,0) [0|12.7] "m/s"  ADC
 SG_ ARC_OD_VabsYStd_Obj_52_RL : 80|7@0+ (0.2,0) [0|25.4] "m/s"  ADC
 SG_ ARC_OD_AabsXStd_Obj_52_RL : 89|7@0+ (0.25,0) [0|31.75] "m/s^2"  ADC

BO_ 876 ARC_OD_54_55_RL: 64 ARC
 SG_ DistHeight_Obj_55_RL : 487|8@0+ (0.2,-10) [-10|41] "m" Vector__XXX
 SG_ DistHeight_Obj_54_RL : 479|8@0+ (0.2,-10) [-10|41] "m" Vector__XXX
 SG_ ARC_OD_DistX_Obj_54_RL : 7|12@0+ (0.1,-152) [-152|257.5] "m"  ADC
 SG_ ARC_OD_Classification_Obj_54_RL : 98|3@0+ (1,0) [0|7] ""  ADC
 SG_ ARC_OD_AabsYStd_Obj_54_RL : 111|8@0+ (0.25,0) [0|63.75] "m/s^2"  ADC
 SG_ ARC_OD_ClassConf_Obj_54_RL : 119|7@0+ (1,0) [0|127] "%"  ADC
 SG_ ARC_OD_ProbOfExist_Obj_54_RL : 112|7@0+ (1,0) [0|127] "%"  ADC
 SG_ ARC_OD_VabsX_Obj_54_RL : 11|11@0+ (0.125,-128) [-128|127.875] "m/s"  ADC
 SG_ ARC_OD_DynProp_Obj_54_RL : 130|3@0+ (1,0) [0|7] ""  ADC
 SG_ ARC_OD_Length_Obj_54_RL : 136|7@0+ (0.2,0) [0|25.4] "m"  ADC
 SG_ ARC_OD_MaintenanceState_Obj_0115 : 145|2@0+ (1,0) [0|3] ""  ADC
 SG_ ARC_OD_Width_Obj_54_RL : 159|7@0+ (0.2,0) [0|25.4] "m"  ADC
 SG_ ARC_OD_RCS_Obj_54_RL : 152|9@0+ (0.2,-51.1) [-51.1|51.1] "dBsm"  ADC
 SG_ ARC_OD_Orientation_Obj_54_RL : 175|10@0+ (0.01,-5.11) [-5.11|5.12] "rad"  ADC
 SG_ ARC_OD_LifeCycle_Obj_54_RL : 207|16@0+ (1,0) [0|65535] ""  ADC
 SG_ ARC_OD_DistX_Obj_55_RL : 223|12@0+ (0.1,-152) [-152|257.5] "m"  ADC
 SG_ ARC_OD_VabsX_Obj_55_RL : 227|11@0+ (0.125,-128) [-128|127.875] "m/s"  ADC
 SG_ ARC_OD_AabsX_Obj_55_RL : 232|9@0+ (0.125,-31.875) [-31.875|32] "m/s^2"  ADC
 SG_ ARC_OD_AabsX_Obj_54_RL : 16|9@0+ (0.125,-31.875) [-31.875|32] "m/s^2"  ADC
 SG_ ARC_OD_DistY_Obj_55_RL : 255|12@0+ (0.0875,-179.113) [-179.113|179.2] "m"  ADC
 SG_ ARC_OD_VabsY_Obj_55_RL : 259|11@0+ (0.125,-128) [-128|127.875] "m/s"  ADC
 SG_ ARC_OD_AabsY_Obj_55_RL : 264|9@0+ (0.125,-31.875) [-31.875|32] "m/s^2"  ADC
 SG_ ARC_OD_DistXStd_Obj_55_RL : 287|8@0+ (0.05,0) [0|12.75] "m"  ADC
 SG_ ARC_OD_DistYStd_Obj_55_RL : 295|8@0+ (0.1,0) [0|25.5] "m"  ADC
 SG_ ARC_OD_VabsXStd_Obj_55_RL : 303|7@0+ (0.1,0) [0|12.7] "m/s"  ADC
 SG_ ARC_OD_VabsYStd_Obj_55_RL : 296|7@0+ (0.2,0) [0|25.4] "m/s"  ADC
 SG_ ARC_OD_AabsXStd_Obj_55_RL : 305|7@0+ (0.25,0) [0|31.75] "m/s^2"  ADC
 SG_ ARC_OD_Classification_Obj_55_RL : 314|3@0+ (1,0) [0|7] ""  ADC
 SG_ ARC_OD_AabsYStd_Obj_55_RL : 327|8@0+ (0.25,0) [0|63.75] "m/s^2"  ADC
 SG_ ARC_OD_ClassConf_Obj_55_RL : 335|7@0+ (1,0) [0|127] "%"  ADC
 SG_ ARC_OD_DistY_Obj_54_RL : 39|12@0+ (0.0875,-179.113) [-179.113|179.2] "m"  ADC
 SG_ ARC_OD_ProbOfExist_Obj_55_RL : 328|7@0+ (1,0) [0|127] "%"  ADC
 SG_ ARC_OD_DynProp_Obj_55_RL : 346|3@0+ (1,0) [0|7] ""  ADC
 SG_ ARC_OD_Length_Obj_55_RL : 352|7@0+ (0.2,0) [0|25.4] "m"  ADC
 SG_ ARC_OD_MaintenanceState_Obj_0116 : 361|2@0+ (1,0) [0|3] ""  ADC
 SG_ ARC_OD_Width_Obj_55_RL : 375|7@0+ (0.2,0) [0|25.4] "m"  ADC
 SG_ ARC_OD_RCS_Obj_55_RL : 368|9@0+ (0.2,-51.1) [-51.1|51.1] "dBsm"  ADC
 SG_ ARC_OD_Orientation_Obj_55_RL : 391|10@0+ (0.01,-5.11) [-5.11|5.12] "rad"  ADC
 SG_ ARC_OD_LifeCycle_Obj_55_RL : 423|16@0+ (1,0) [0|65535] ""  ADC
 SG_ ARC_OD_ObstacleProb_Obj_54_RL : 447|7@0+ (1,0) [0|127] "%"  ADC
 SG_ ARC_OD_ObstacleProb_Obj_55_RL : 455|7@0+ (1,0) [0|127] "%"  ADC
 SG_ ARC_OD_VabsY_Obj_54_RL : 43|11@0+ (0.125,-128) [-128|127.875] "m/s"  ADC
 SG_ ARC_OD_ID_54_RL : 463|8@0+ (1,0) [0|255] ""  ADC
 SG_ ARC_OD_ID_55_RL : 471|8@0+ (1,0) [0|255] ""  ADC
 SG_ ARC_OD_MsgCounter_Obj_54_55_RL : 491|4@0+ (1,0) [0|15] ""  ADC
 SG_ ARC_OD_CRC8_Obj_54_55_RL : 511|8@0+ (1,0) [0|256] ""  ADC
 SG_ ARC_OD_AabsY_Obj_54_RL : 48|9@0+ (0.125,-31.875) [-31.875|32] "m/s^2"  ADC
 SG_ ARC_OD_DistXStd_Obj_54_RL : 71|8@0+ (0.05,0) [0|12.75] "m"  ADC
 SG_ ARC_OD_DistYStd_Obj_54_RL : 79|8@0+ (0.1,0) [0|25.5] "m"  ADC
 SG_ ARC_OD_VabsXStd_Obj_54_RL : 87|7@0+ (0.1,0) [0|12.7] "m/s"  ADC
 SG_ ARC_OD_VabsYStd_Obj_54_RL : 80|7@0+ (0.2,0) [0|25.4] "m/s"  ADC
 SG_ ARC_OD_AabsXStd_Obj_54_RL : 89|7@0+ (0.25,0) [0|31.75] "m/s^2"  ADC

BO_ 877 ARC_OD_56_57_RL: 64 ARC
 SG_ DistHeight_Obj_57_RL : 487|8@0+ (0.2,-10) [-10|41] "m" Vector__XXX
 SG_ DistHeight_Obj_56_RL : 479|8@0+ (0.2,-10) [-10|41] "m" Vector__XXX
 SG_ ARC_OD_DistX_Obj_56_RL : 7|12@0+ (0.1,-152) [-152|257.5] "m"  ADC
 SG_ ARC_OD_Classification_Obj_56_RL : 98|3@0+ (1,0) [0|7] ""  ADC
 SG_ ARC_OD_AabsYStd_Obj_56_RL : 111|8@0+ (0.25,0) [0|63.75] "m/s^2"  ADC
 SG_ ARC_OD_ClassConf_Obj_56_RL : 119|7@0+ (1,0) [0|127] "%"  ADC
 SG_ ARC_OD_ProbOfExist_Obj_56_RL : 112|7@0+ (1,0) [0|127] "%"  ADC
 SG_ ARC_OD_VabsX_Obj_56_RL : 11|11@0+ (0.125,-128) [-128|127.875] "m/s"  ADC
 SG_ ARC_OD_DynProp_Obj_56_RL : 130|3@0+ (1,0) [0|7] ""  ADC
 SG_ ARC_OD_Length_Obj_56_RL : 136|7@0+ (0.2,0) [0|25.4] "m"  ADC
 SG_ ARC_OD_MaintenanceState_Obj_0117 : 145|2@0+ (1,0) [0|3] ""  ADC
 SG_ ARC_OD_Width_Obj_56_RL : 159|7@0+ (0.2,0) [0|25.4] "m"  ADC
 SG_ ARC_OD_RCS_Obj_56_RL : 152|9@0+ (0.2,-51.1) [-51.1|51.1] "dBsm"  ADC
 SG_ ARC_OD_Orientation_Obj_56_RL : 175|10@0+ (0.01,-5.11) [-5.11|5.12] "rad"  ADC
 SG_ ARC_OD_LifeCycle_Obj_56_RL : 207|16@0+ (1,0) [0|65535] ""  ADC
 SG_ ARC_OD_DistX_Obj_57_RL : 223|12@0+ (0.1,-152) [-152|257.5] "m"  ADC
 SG_ ARC_OD_VabsX_Obj_57_RL : 227|11@0+ (0.125,-128) [-128|127.875] "m/s"  ADC
 SG_ ARC_OD_AabsX_Obj_57_RL : 232|9@0+ (0.125,-31.875) [-31.875|32] "m/s^2"  ADC
 SG_ ARC_OD_AabsX_Obj_56_RL : 16|9@0+ (0.125,-31.875) [-31.875|32] "m/s^2"  ADC
 SG_ ARC_OD_DistY_Obj_57_RL : 255|12@0+ (0.0875,-179.113) [-179.113|179.2] "m"  ADC
 SG_ ARC_OD_VabsY_Obj_57_RL : 259|11@0+ (0.125,-128) [-128|127.875] "m/s"  ADC
 SG_ ARC_OD_AabsY_Obj_57_RL : 264|9@0+ (0.125,-31.875) [-31.875|32] "m/s^2"  ADC
 SG_ ARC_OD_DistXStd_Obj_57_RL : 287|8@0+ (0.05,0) [0|12.75] "m"  ADC
 SG_ ARC_OD_DistYStd_Obj_57_RL : 295|8@0+ (0.1,0) [0|25.5] "m"  ADC
 SG_ ARC_OD_VabsXStd_Obj_57_RL : 303|7@0+ (0.1,0) [0|12.7] "m/s"  ADC
 SG_ ARC_OD_VabsYStd_Obj_57_RL : 296|7@0+ (0.2,0) [0|25.4] "m/s"  ADC
 SG_ ARC_OD_AabsXStd_Obj_57_RL : 305|7@0+ (0.25,0) [0|31.75] "m/s^2"  ADC
 SG_ ARC_OD_Classification_Obj_57_RL : 314|3@0+ (1,0) [0|7] ""  ADC
 SG_ ARC_OD_AabsYStd_Obj_57_RL : 327|8@0+ (0.25,0) [0|63.75] "m/s^2"  ADC
 SG_ ARC_OD_ClassConf_Obj_57_RL : 335|7@0+ (1,0) [0|127] "%"  ADC
 SG_ ARC_OD_DistY_Obj_56_RL : 39|12@0+ (0.0875,-179.113) [-179.113|179.2] "m"  ADC
 SG_ ARC_OD_ProbOfExist_Obj_57_RL : 328|7@0+ (1,0) [0|127] "%"  ADC
 SG_ ARC_OD_DynProp_Obj_57_RL : 346|3@0+ (1,0) [0|7] ""  ADC
 SG_ ARC_OD_Length_Obj_57_RL : 352|7@0+ (0.2,0) [0|25.4] "m"  ADC
 SG_ ARC_OD_MaintenanceState_Obj_0118 : 361|2@0+ (1,0) [0|3] ""  ADC
 SG_ ARC_OD_Width_Obj_57_RL : 375|7@0+ (0.2,0) [0|25.4] "m"  ADC
 SG_ ARC_OD_RCS_Obj_57_RL : 368|9@0+ (0.2,-51.1) [-51.1|51.1] "dBsm"  ADC
 SG_ ARC_OD_Orientation_Obj_57_RL : 391|10@0+ (0.01,-5.11) [-5.11|5.12] "rad"  ADC
 SG_ ARC_OD_LifeCycle_Obj_57_RL : 423|16@0+ (1,0) [0|65535] ""  ADC
 SG_ ARC_OD_ObstacleProb_Obj_56_RL : 447|7@0+ (1,0) [0|127] "%"  ADC
 SG_ ARC_OD_ObstacleProb_Obj_57_RL : 455|7@0+ (1,0) [0|127] "%"  ADC
 SG_ ARC_OD_VabsY_Obj_56_RL : 43|11@0+ (0.125,-128) [-128|127.875] "m/s"  ADC
 SG_ ARC_OD_ID_56_RL : 463|8@0+ (1,0) [0|255] ""  ADC
 SG_ ARC_OD_ID_57_RL : 471|8@0+ (1,0) [0|255] ""  ADC
 SG_ ARC_OD_MsgCounter_Obj_56_57_RL : 491|4@0+ (1,0) [0|15] ""  ADC
 SG_ ARC_OD_CRC8_Obj_56_57_RL : 511|8@0+ (1,0) [0|256] ""  ADC
 SG_ ARC_OD_AabsY_Obj_56_RL : 48|9@0+ (0.125,-31.875) [-31.875|32] "m/s^2"  ADC
 SG_ ARC_OD_DistXStd_Obj_56_RL : 71|8@0+ (0.05,0) [0|12.75] "m"  ADC
 SG_ ARC_OD_DistYStd_Obj_56_RL : 79|8@0+ (0.1,0) [0|25.5] "m"  ADC
 SG_ ARC_OD_VabsXStd_Obj_56_RL : 87|7@0+ (0.1,0) [0|12.7] "m/s"  ADC
 SG_ ARC_OD_VabsYStd_Obj_56_RL : 80|7@0+ (0.2,0) [0|25.4] "m/s"  ADC
 SG_ ARC_OD_AabsXStd_Obj_56_RL : 89|7@0+ (0.25,0) [0|31.75] "m/s^2"  ADC

BO_ 878 ARC_OD_58_59_RL: 64 ARC
 SG_ DistHeight_Obj_59_RL : 487|8@0+ (0.2,-10) [-10|41] "m" Vector__XXX
 SG_ DistHeight_Obj_58_RL : 479|8@0+ (0.2,-10) [-10|41] "m" Vector__XXX
 SG_ ARC_OD_DistX_Obj_58_RL : 7|12@0+ (0.1,-152) [-152|257.5] "m"  ADC
 SG_ ARC_OD_Classification_Obj_58_RL : 98|3@0+ (1,0) [0|7] ""  ADC
 SG_ ARC_OD_AabsYStd_Obj_58_RL : 111|8@0+ (0.25,0) [0|63.75] "m/s^2"  ADC
 SG_ ARC_OD_ClassConf_Obj_58_RL : 119|7@0+ (1,0) [0|127] "%"  ADC
 SG_ ARC_OD_ProbOfExist_Obj_58_RL : 112|7@0+ (1,0) [0|127] "%"  ADC
 SG_ ARC_OD_VabsX_Obj_58_RL : 11|11@0+ (0.125,-128) [-128|127.875] "m/s"  ADC
 SG_ ARC_OD_DynProp_Obj_58_RL : 130|3@0+ (1,0) [0|7] ""  ADC
 SG_ ARC_OD_Length_Obj_58_RL : 136|7@0+ (0.2,0) [0|25.4] "m"  ADC
 SG_ ARC_OD_MaintenanceState_Obj_0119 : 145|2@0+ (1,0) [0|3] ""  ADC
 SG_ ARC_OD_Width_Obj_58_RL : 159|7@0+ (0.2,0) [0|25.4] "m"  ADC
 SG_ ARC_OD_RCS_Obj_58_RL : 152|9@0+ (0.2,-51.1) [-51.1|51.1] "dBsm"  ADC
 SG_ ARC_OD_Orientation_Obj_58_RL : 175|10@0+ (0.01,-5.11) [-5.11|5.12] "rad"  ADC
 SG_ ARC_OD_LifeCycle_Obj_58_RL : 207|16@0+ (1,0) [0|65535] ""  ADC
 SG_ ARC_OD_DistX_Obj_59_RL : 223|12@0+ (0.1,-152) [-152|257.5] "m"  ADC
 SG_ ARC_OD_VabsX_Obj_59_RL : 227|11@0+ (0.125,-128) [-128|127.875] "m/s"  ADC
 SG_ ARC_OD_AabsX_Obj_59_RL : 232|9@0+ (0.125,-31.875) [-31.875|32] "m/s^2"  ADC
 SG_ ARC_OD_AabsX_Obj_58_RL : 16|9@0+ (0.125,-31.875) [-31.875|32] "m/s^2"  ADC
 SG_ ARC_OD_DistY_Obj_59_RL : 255|12@0+ (0.0875,-179.113) [-179.113|179.2] "m"  ADC
 SG_ ARC_OD_VabsY_Obj_59_RL : 259|11@0+ (0.125,-128) [-128|127.875] "m/s"  ADC
 SG_ ARC_OD_AabsY_Obj_59_RL : 264|9@0+ (0.125,-31.875) [-31.875|32] "m/s^2"  ADC
 SG_ ARC_OD_DistXStd_Obj_59_RL : 287|8@0+ (0.05,0) [0|12.75] "m"  ADC
 SG_ ARC_OD_DistYStd_Obj_59_RL : 295|8@0+ (0.1,0) [0|25.5] "m"  ADC
 SG_ ARC_OD_VabsXStd_Obj_59_RL : 303|7@0+ (0.1,0) [0|12.7] "m/s"  ADC
 SG_ ARC_OD_VabsYStd_Obj_59_RL : 296|7@0+ (0.2,0) [0|25.4] "m/s"  ADC
 SG_ ARC_OD_AabsXStd_Obj_59_RL : 305|7@0+ (0.25,0) [0|31.75] "m/s^2"  ADC
 SG_ ARC_OD_Classification_Obj_59_RL : 314|3@0+ (1,0) [0|7] ""  ADC
 SG_ ARC_OD_AabsYStd_Obj_59_RL : 327|8@0+ (0.25,0) [0|63.75] "m/s^2"  ADC
 SG_ ARC_OD_ClassConf_Obj_59_RL : 335|7@0+ (1,0) [0|127] "%"  ADC
 SG_ ARC_OD_DistY_Obj_58_RL : 39|12@0+ (0.0875,-179.113) [-179.113|179.2] "m"  ADC
 SG_ ARC_OD_ProbOfExist_Obj_59_RL : 328|7@0+ (1,0) [0|127] "%"  ADC
 SG_ ARC_OD_DynProp_Obj_59_RL : 346|3@0+ (1,0) [0|7] ""  ADC
 SG_ ARC_OD_Length_Obj_59_RL : 352|7@0+ (0.2,0) [0|25.4] "m"  ADC
 SG_ ARC_OD_MaintenanceState_Obj_0120 : 361|2@0+ (1,0) [0|3] ""  ADC
 SG_ ARC_OD_Width_Obj_59_RL : 375|7@0+ (0.2,0) [0|25.4] "m"  ADC
 SG_ ARC_OD_RCS_Obj_59_RL : 368|9@0+ (0.2,-51.1) [-51.1|51.1] "dBsm"  ADC
 SG_ ARC_OD_Orientation_Obj_59_RL : 391|10@0+ (0.01,-5.11) [-5.11|5.12] "rad"  ADC
 SG_ ARC_OD_LifeCycle_Obj_59_RL : 423|16@0+ (1,0) [0|65535] ""  ADC
 SG_ ARC_OD_ObstacleProb_Obj_58_RL : 447|7@0+ (1,0) [0|127] "%"  ADC
 SG_ ARC_OD_ObstacleProb_Obj_59_RL : 455|7@0+ (1,0) [0|127] "%"  ADC
 SG_ ARC_OD_VabsY_Obj_58_RL : 43|11@0+ (0.125,-128) [-128|127.875] "m/s"  ADC
 SG_ ARC_OD_ID_58_RL : 463|8@0+ (1,0) [0|255] ""  ADC
 SG_ ARC_OD_ID_59_RL : 471|8@0+ (1,0) [0|255] ""  ADC
 SG_ ARC_OD_MsgCounter_Obj_58_59_RL : 491|4@0+ (1,0) [0|15] ""  ADC
 SG_ ARC_OD_CRC8_Obj_58_59_RL : 511|8@0+ (1,0) [0|256] ""  ADC
 SG_ ARC_OD_AabsY_Obj_58_RL : 48|9@0+ (0.125,-31.875) [-31.875|32] "m/s^2"  ADC
 SG_ ARC_OD_DistXStd_Obj_58_RL : 71|8@0+ (0.05,0) [0|12.75] "m"  ADC
 SG_ ARC_OD_DistYStd_Obj_58_RL : 79|8@0+ (0.1,0) [0|25.5] "m"  ADC
 SG_ ARC_OD_VabsXStd_Obj_58_RL : 87|7@0+ (0.1,0) [0|12.7] "m/s"  ADC
 SG_ ARC_OD_VabsYStd_Obj_58_RL : 80|7@0+ (0.2,0) [0|25.4] "m/s"  ADC
 SG_ ARC_OD_AabsXStd_Obj_58_RL : 89|7@0+ (0.25,0) [0|31.75] "m/s^2"  ADC

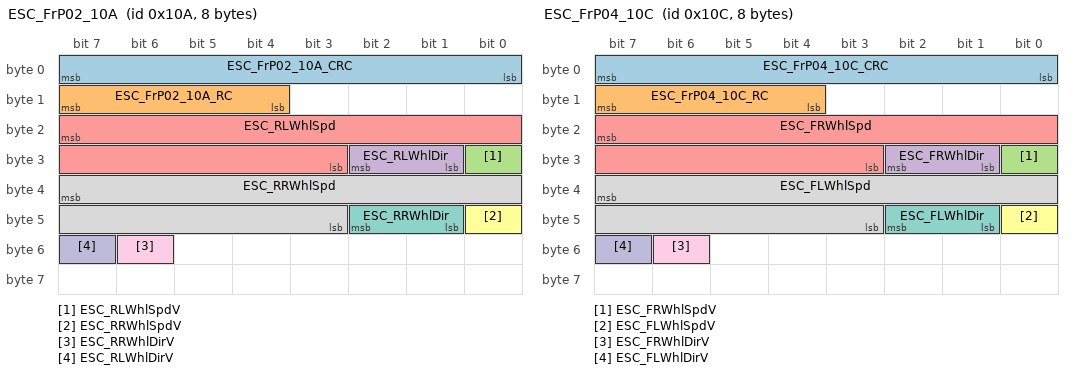
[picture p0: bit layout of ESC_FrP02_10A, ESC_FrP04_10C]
BO_ 266 ESC_FrP02_10A: 8 ADC
 SG_ ESC_FrP02_10A_CRC : 7|8@0+ (1,0) [0|255] ""  ARC
 SG_ ESC_FrP02_10A_RC : 15|4@0+ (1,0) [0|15] ""  ARC
 SG_ ESC_RLWhlSpdV : 24|1@0+ (1,0) [0|1] ""  ARC
 SG_ ESC_RLWhlDir : 26|2@0+ (1,0) [0|3] ""  ARC
 SG_ ESC_RLWhlSpd : 23|13@0+ (0.05625,0) [0|460.74375] "km/h"  ARC
 SG_ ESC_RRWhlSpdV : 40|1@0+ (1,0) [0|1] ""  ARC
 SG_ ESC_RRWhlDir : 42|2@0+ (1,0) [0|3] ""  ARC
 SG_ ESC_RRWhlSpd : 39|13@0+ (0.05625,0) [0|460.74375] "km/h"  ARC
 SG_ ESC_RRWhlDirV : 54|1@0+ (1,0) [0|1] ""  ARC
 SG_ ESC_RLWhlDirV : 55|1@0+ (1,0) [0|1] ""  ARC

BO_ 268 ESC_FrP04_10C: 8 ADC
 SG_ ESC_FrP04_10C_CRC : 7|8@0+ (1,0) [0|255] ""  ARC
 SG_ ESC_FrP04_10C_RC : 15|4@0+ (1,0) [0|15] ""  ARC
 SG_ ESC_FRWhlSpdV : 24|1@0+ (1,0) [0|1] ""  ARC
 SG_ ESC_FRWhlDir : 26|2@0+ (1,0) [0|3] ""  ARC
 SG_ ESC_FRWhlSpd : 23|13@0+ (0.05625,0) [0|460.74375] "km/h"  ARC
 SG_ ESC_FLWhlSpdV : 40|1@0+ (1,0) [0|1] ""  ARC
 SG_ ESC_FLWhlDir : 42|2@0+ (1,0) [0|3] ""  ARC
 SG_ ESC_FLWhlSpd : 39|13@0+ (0.05625,0) [0|460.74375] "km/h"  ARC
 SG_ ESC_FRWhlDirV : 54|1@0+ (1,0) [0|1] ""  ARC
 SG_ ESC_FLWhlDirV : 55|1@0+ (1,0) [0|1] ""  ARC

BO_ 271 ESC_FrP07_10F: 16 ADC
 SG_ ESC_LatSenSts : 9|1@0+ (1,0) [0|1] ""  ARC
 SG_ ESC_YRSenSts : 10|1@0+ (1,0) [0|1] ""  ARC
 SG_ ESC_LgtSenSt : 11|1@0+ (1,0) [0|1] ""  ARC
 SG_ ESC_YR : 23|16@0+ (0.01,-300) [-300|355.35] "°/s"  ARC
 SG_ ESC_LatAccelSenVal : 39|16@0+ (0.001,-6) [-6|59.535] "g"  ARC
 SG_ ESC_LgtAccel : 55|16@0+ (0.001,-6) [-6|59.535] "g"  ARC

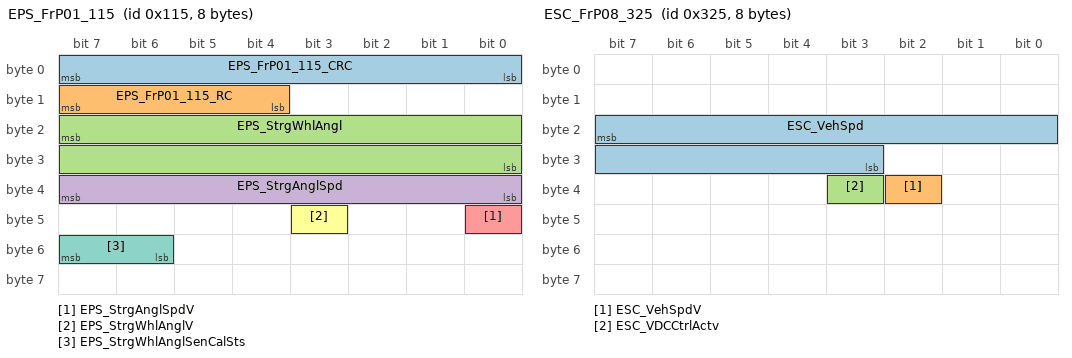
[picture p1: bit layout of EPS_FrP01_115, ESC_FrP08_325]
BO_ 277 EPS_FrP01_115: 8 ADC
 SG_ EPS_FrP01_115_CRC : 7|8@0+ (1,0) [0|255] ""  ARC
 SG_ EPS_FrP01_115_RC : 15|4@0+ (1,0) [0|15] ""  ARC
 SG_ EPS_StrgWhlAngl : 23|16@0+ (0.0625,-2048) [-2048|2047.9375] "deg"  ARC
 SG_ EPS_StrgAnglSpd : 39|8@0+ (4,0) [0|1020] "deg/s"  ARC
 SG_ EPS_StrgAnglSpdV : 40|1@0+ (1,0) [0|1] ""  ARC
 SG_ EPS_StrgWhlAnglV : 43|1@0+ (1,0) [0|1] ""  ARC
 SG_ EPS_StrgWhlAnglSenCalSts : 55|2@0+ (1,0) [0|3] ""  ARC

BO_ 805 ESC_FrP08_325: 8 ADC
 SG_ ESC_VehSpd : 23|13@0+ (0.05625,0) [0|460.74375] "km/h"  ARC
 SG_ ESC_VehSpdV : 34|1@0+ (1,0) [0|1] ""  ARC
 SG_ ESC_VDCCtrlActv : 35|1@0+ (1,0) [0|1] ""  ARC

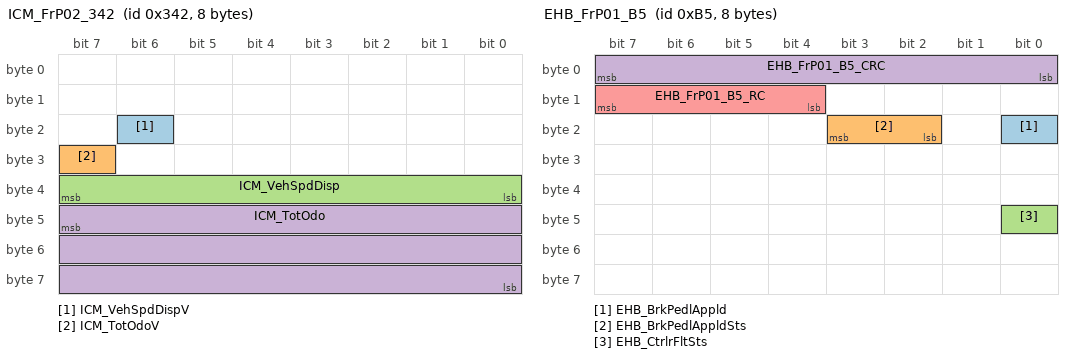
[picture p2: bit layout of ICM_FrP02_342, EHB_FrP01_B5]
BO_ 834 ICM_FrP02_342: 8 ADC
 SG_ ICM_VehSpdDispV : 22|1@0+ (1,0) [0|1] ""  ARC
 SG_ ICM_TotOdoV : 31|1@0+ (1,0) [0|1] ""  ARC
 SG_ ICM_VehSpdDisp : 39|8@0+ (1,0) [0|255] ""  ARC
 SG_ ICM_TotOdo : 47|24@0+ (0.1,0) [0|1677721.5] ""  ARC

BO_ 819 ADC_TimeSync: 16 ADC
 SG_ Sync_Counter : 19|4@0+ (1,0) [0|15] ""  ARC
 SG_ Sync_CRC : 15|8@0+ (1,0) [0|255] ""  ARC
 SG_ Sync_OVS : 25|2@0+ (1,0) [0|3] ""  ARC
 SG_ Sync_Resd : 31|5@0+ (1,0) [0|31] ""  ARC
 SG_ Sync_SGW : 26|1@0+ (1,0) [0|1] ""  ARC
 SG_ Sync_SyncTime : 39|32@0+ (1,0) [0|4294967295] "s"  ARC
 SG_ Sync_TimeDomain : 23|4@0+ (1,0) [0|15] ""  ARC
 SG_ Sync_Type : 7|8@0+ (1,0) [0|255] ""  ARC

BO_ 267 ESC_FrP03_10B: 32 ADC
 SG_ ESC_FrP03_10B_CRC_1 : 7|8@0+ (1,0) [0|255] ""  ARC
 SG_ ESC_EBDActv : 8|1@0+ (1,0) [0|1] ""  ARC
 SG_ ESC_FrP03_10B_RC_1 : 15|4@0+ (1,0) [0|15] ""  ARC
 SG_ ESC_TCSActv : 26|1@0+ (1,0) [0|1] ""  ARC
 SG_ ESC_ABSActv : 27|1@0+ (1,0) [0|1] ""  ARC
 SG_ ESC_ESCFld : 49|1@0+ (1,0) [0|1] ""  ARC
 SG_ ESC_CDPActv : 57|1@0+ (1,0) [0|1] ""  ARC
 SG_ ESC_HDCSts : 85|2@0+ (1,0) [0|3] ""  ARC
 SG_ ESC_Off : 88|1@0+ (1,0) [0|1] ""  ARC
 SG_ ESC_ABAAvlbl : 113|1@0+ (1,0) [0|1] ""  ARC
 SG_ ESC_ABAActv : 114|1@0+ (1,0) [0|1] ""  ARC
 SG_ ESC_FrP03_10B_CRC_3 : 135|8@0+ (1,0) [0|255] ""  ARC
 SG_ ESC_FrP03_10B_RC_3 : 143|4@0+ (1,0) [0|15] ""  ARC
 SG_ ESC_FrP03_10B_CRC_4 : 199|8@0+ (1,0) [0|255] ""  ARC
 SG_ ESC_FrP03_10B_RC_4 : 207|4@0+ (1,0) [0|15] ""  ARC
 SG_ ESC_FrP03_10B_CRC_2 : 71|8@0+ (1,0) [0|255] ""  ARC
 SG_ ESC_FrP03_10B_RC_2 : 79|4@0+ (1,0) [0|15] ""  ARC

BO_ 269 ESC_FrP05_10D: 8 ADC
 SG_ ESC_VehStdslSts : 44|1@0+ (1,0) [0|1] ""  ARC
 SG_ ESC_VehStdslStsV : 45|1@0+ (1,0) [0|1] ""  ARC

BO_ 181 EHB_FrP01_B5: 8 ADC
 SG_ EHB_BrkPedlAppld : 16|1@0+ (1,0) [0|1] ""  ARC
 SG_ EHB_BrkPedlAppldSts : 19|2@0+ (1,0) [0|3] ""  ARC
 SG_ EHB_CtrlrFltSts : 40|1@0+ (1,0) [0|1] ""  ARC
 SG_ EHB_FrP01_B5_CRC : 7|8@0+ (1,0) [0|255] ""  ARC
 SG_ EHB_FrP01_B5_RC : 15|4@0+ (1,0) [0|15] ""  ARC

CM_ SG_ 860 ARC_OD_DistX_Obj_22_RL "Longitudinal distance of object_22
00????????";
CM_ SG_ 860 ARC_OD_Classification_Obj_22_RL "Classification of object_22
00??????";
CM_ SG_ 860 ARC_OD_AabsYStd_Obj_22_RL "Lateral absolution acceleration standard deviation of object_22
00????????????????";
CM_ SG_ 860 ARC_OD_ClassConf_Obj_22_RL "Classification confidence of object_22
00?????????";
CM_ SG_ 860 ARC_OD_ProbOfExist_Obj_22_RL "Existence probability of object_22
00????????";
CM_ SG_ 860 ARC_OD_VabsX_Obj_22_RL "Longitudinal absolution velocity over ground of object_22
00????????????";
CM_ SG_ 860 ARC_OD_DynProp_Obj_22_RL "Dynamic property of object_22
00????????";
CM_ SG_ 860 ARC_OD_Length_Obj_22_RL "Length of object_22
00??????";
CM_ SG_ 860 ARC_OD_MaintenanceState_Obj_0083 "Maintenance state of object_22
00????????";
CM_ SG_ 860 ARC_OD_Width_Obj_22_RL "Width of object_22
00??????";
CM_ SG_ 860 ARC_OD_RCS_Obj_22_RL "RCS of object_22
00?????????";
CM_ SG_ 860 ARC_OD_Orientation_Obj_22_RL "Orientation of object_22
00???????";
CM_ SG_ 860 ARC_OD_LifeCycle_Obj_22_RL "Life cycle of object_22
00????????";
CM_ SG_ 860 ARC_OD_AabsX_Obj_22_RL "Longitudinal absolution acceleration over ground of object_22
00?????????????";
CM_ SG_ 860 ARC_OD_DistY_Obj_22_RL "Lateral distance of object_22
00????????";
CM_ SG_ 860 ARC_OD_ObstacleProb_Obj_22_RL "Obstacle probability of object_22
00?????????";
CM_ SG_ 860 ARC_OD_VabsY_Obj_22_RL "Lateral absolution velocity over ground of object_22
00????????????";
CM_ SG_ 860 ARC_OD_AabsY_Obj_22_RL "Lateral absolution acceleration over ground of object_22
00?????????????";
CM_ SG_ 860 ARC_OD_DistXStd_Obj_22_RL "Longitudinal distance standard deviation of object_22
00???????????";
CM_ SG_ 860 ARC_OD_DistYStd_Obj_22_RL "Lateral distance standard deviation of object_22
00???????????";
CM_ SG_ 860 ARC_OD_VabsXStd_Obj_22_RL "Longitudinal absolution velocity standard deviation of object_22
00???????????????";
CM_ SG_ 860 ARC_OD_VabsYStd_Obj_22_RL "Lateral absolution velocity standard deviation of object_22
00???????????????";
CM_ SG_ 860 ARC_OD_AabsXStd_Obj_22_RL "Longitudinal absolution acceleration standard deviation of object_22
00????????????????";
CM_ SG_ 861 ARC_OD_DistX_Obj_24_RL "Longitudinal distance of object_24
00????????";
CM_ SG_ 861 ARC_OD_Classification_Obj_24_RL "Classification of object_24
00??????";
CM_ SG_ 861 ARC_OD_AabsYStd_Obj_24_RL "Lateral absolution acceleration standard deviation of object_24
00????????????????";
CM_ SG_ 861 ARC_OD_ClassConf_Obj_24_RL "Classification confidence of object_24
00?????????";
CM_ SG_ 861 ARC_OD_ProbOfExist_Obj_24_RL "Existence probability of object_24
00????????";
CM_ SG_ 861 ARC_OD_VabsX_Obj_24_RL "Longitudinal absolution velocity over ground of object_24
00????????????";
CM_ SG_ 861 ARC_OD_DynProp_Obj_24_RL "Dynamic property of object_24
00????????";
CM_ SG_ 861 ARC_OD_Length_Obj_24_RL "Length of object_24
00??????";
CM_ SG_ 861 ARC_OD_MaintenanceState_Obj_0085 "Maintenance state of object_24
00????????";
CM_ SG_ 861 ARC_OD_Width_Obj_24_RL "Width of object_24
00??????";
CM_ SG_ 861 ARC_OD_RCS_Obj_24_RL "RCS of object_24
00?????????";
CM_ SG_ 861 ARC_OD_Orientation_Obj_24_RL "Orientation of object_24
00???????";
CM_ SG_ 861 ARC_OD_LifeCycle_Obj_24_RL "Life cycle of object_24
00????????";
CM_ SG_ 861 ARC_OD_AabsX_Obj_24_RL "Longitudinal absolution acceleration over ground of object_24
00?????????????";
CM_ SG_ 861 ARC_OD_DistY_Obj_24_RL "Lateral distance of object_24
00????????";
CM_ SG_ 861 ARC_OD_ObstacleProb_Obj_24_RL "Obstacle probability of object_24
00?????????";
CM_ SG_ 861 ARC_OD_VabsY_Obj_24_RL "Lateral absolution velocity over ground of object_24
00????????????";
CM_ SG_ 861 ARC_OD_AabsY_Obj_24_RL "Lateral absolution acceleration over ground of object_24
00?????????????";
CM_ SG_ 861 ARC_OD_DistXStd_Obj_24_RL "Longitudinal distance standard deviation of object_24
00???????????";
CM_ SG_ 861 ARC_OD_DistYStd_Obj_24_RL "Lateral distance standard deviation of object_24
00???????????";
CM_ SG_ 861 ARC_OD_VabsXStd_Obj_24_RL "Longitudinal absolution velocity standard deviation of object_24
00???????????????";
CM_ SG_ 861 ARC_OD_VabsYStd_Obj_24_RL "Lateral absolution velocity standard deviation of object_24
00???????????????";
CM_ SG_ 861 ARC_OD_AabsXStd_Obj_24_RL "Longitudinal absolution acceleration standard deviation of object_24
00????????????????";
CM_ SG_ 862 ARC_OD_DistX_Obj_26_RL "Longitudinal distance of object_26
00????????";
CM_ SG_ 862 ARC_OD_Classification_Obj_26_RL "Classification of object_26
00??????";
CM_ SG_ 862 ARC_OD_AabsYStd_Obj_26_RL "Lateral absolution acceleration standard deviation of object_26
00????????????????";
CM_ SG_ 862 ARC_OD_ClassConf_Obj_26_RL "Classification confidence of object_26
00?????????";
CM_ SG_ 862 ARC_OD_ProbOfExist_Obj_26_RL "Existence probability of object_26
00????????";
CM_ SG_ 862 ARC_OD_VabsX_Obj_26_RL "Longitudinal absolution velocity over ground of object_26
00????????????";
CM_ SG_ 862 ARC_OD_DynProp_Obj_26_RL "Dynamic property of object_26
00????????";
CM_ SG_ 862 ARC_OD_Length_Obj_26_RL "Length of object_26
00??????";
CM_ SG_ 862 ARC_OD_MaintenanceState_Obj_0087 "Maintenance state of object_26
00????????";
CM_ SG_ 862 ARC_OD_Width_Obj_26_RL "Width of object_26
00??????";
CM_ SG_ 862 ARC_OD_RCS_Obj_26_RL "RCS of object_26
00?????????";
CM_ SG_ 862 ARC_OD_Orientation_Obj_26_RL "Orientation of object_26
00???????";
CM_ SG_ 862 ARC_OD_LifeCycle_Obj_26_RL "Life cycle of object_26
00????????";
CM_ SG_ 862 ARC_OD_AabsX_Obj_26_RL "Longitudinal absolution acceleration over ground of object_26
00?????????????";
CM_ SG_ 862 ARC_OD_DistY_Obj_26_RL "Lateral distance of object_26
00????????";
CM_ SG_ 862 ARC_OD_ObstacleProb_Obj_26_RL "Obstacle probability of object_26
00?????????";
CM_ SG_ 862 ARC_OD_VabsY_Obj_26_RL "Lateral absolution velocity over ground of object_26
00????????????";
CM_ SG_ 862 ARC_OD_AabsY_Obj_26_RL "Lateral absolution acceleration over ground of object_26
00?????????????";
CM_ SG_ 862 ARC_OD_DistXStd_Obj_26_RL "Longitudinal distance standard deviation of object_26
00???????????";
CM_ SG_ 862 ARC_OD_DistYStd_Obj_26_RL "Lateral distance standard deviation of object_26
00???????????";
CM_ SG_ 862 ARC_OD_VabsXStd_Obj_26_RL "Longitudinal absolution velocity standard deviation of object_26
00???????????????";
CM_ SG_ 862 ARC_OD_VabsYStd_Obj_26_RL "Lateral absolution velocity standard deviation of object_26
00???????????????";
CM_ SG_ 862 ARC_OD_AabsXStd_Obj_26_RL "Longitudinal absolution acceleration standard deviation of object_26
00????????????????";
CM_ SG_ 863 ARC_OD_DistX_Obj_28_RL "Longitudinal distance of object_28
00????????";
CM_ SG_ 863 ARC_OD_Classification_Obj_28_RL "Classification of object_28
00??????";
CM_ SG_ 863 ARC_OD_AabsYStd_Obj_28_RL "Lateral absolution acceleration standard deviation of object_28
00????????????????";
CM_ SG_ 863 ARC_OD_ClassConf_Obj_28_RL "Classification confidence of object_28
00?????????";
CM_ SG_ 863 ARC_OD_ProbOfExist_Obj_28_RL "Existence probability of object_28
00????????";
CM_ SG_ 863 ARC_OD_VabsX_Obj_28_RL "Longitudinal absolution velocity over ground of object_28
00????????????";
CM_ SG_ 863 ARC_OD_DynProp_Obj_28_RL "Dynamic property of object_28
00????????";
CM_ SG_ 863 ARC_OD_Length_Obj_28_RL "Length of object_28
00??????";
CM_ SG_ 863 ARC_OD_MaintenanceState_Obj_0089 "Maintenance state of object_28
00????????";
CM_ SG_ 863 ARC_OD_Width_Obj_28_RL "Width of object_28
00??????";
CM_ SG_ 863 ARC_OD_RCS_Obj_28_RL "RCS of object_28
00?????????";
CM_ SG_ 863 ARC_OD_Orientation_Obj_28_RL "Orientation of object_28
00???????";
CM_ SG_ 863 ARC_OD_LifeCycle_Obj_28_RL "Life cycle of object_28
00????????";
CM_ SG_ 863 ARC_OD_AabsX_Obj_28_RL "Longitudinal absolution acceleration over ground of object_28
00?????????????";
CM_ SG_ 863 ARC_OD_DistY_Obj_28_RL "Lateral distance of object_28
00????????";
CM_ SG_ 863 ARC_OD_ObstacleProb_Obj_28_RL "Obstacle probability of object_28
00?????????";
CM_ SG_ 863 ARC_OD_VabsY_Obj_28_RL "Lateral absolution velocity over ground of object_28
00????????????";
CM_ SG_ 863 ARC_OD_AabsY_Obj_28_RL "Lateral absolution acceleration over ground of object_28
00?????????????";
CM_ SG_ 863 ARC_OD_DistXStd_Obj_28_RL "Longitudinal distance standard deviation of object_28
00???????????";
CM_ SG_ 863 ARC_OD_DistYStd_Obj_28_RL "Lateral distance standard deviation of object_28
00???????????";
CM_ SG_ 863 ARC_OD_VabsXStd_Obj_28_RL "Longitudinal absolution velocity standard deviation of object_28
00???????????????";
CM_ SG_ 863 ARC_OD_VabsYStd_Obj_28_RL "Lateral absolution velocity standard deviation of object_28
00???????????????";
CM_ SG_ 863 ARC_OD_AabsXStd_Obj_28_RL "Longitudinal absolution acceleration standard deviation of object_28
00????????????????";
CM_ SG_ 864 ARC_OD_DistX_Obj_30_RL "Longitudinal distance of object_30
00????????";
CM_ SG_ 864 ARC_OD_Classification_Obj_30_RL "Classification of object_30
00??????";
CM_ SG_ 864 ARC_OD_AabsYStd_Obj_30_RL "Lateral absolution acceleration standard deviation of object_30
00????????????????";
CM_ SG_ 864 ARC_OD_ClassConf_Obj_30_RL "Classification confidence of object_30
00?????????";
CM_ SG_ 864 ARC_OD_ProbOfExist_Obj_30_RL "Existence probability of object_30
00????????";
CM_ SG_ 864 ARC_OD_VabsX_Obj_30_RL "Longitudinal absolution velocity over ground of object_30
00????????????";
CM_ SG_ 864 ARC_OD_DynProp_Obj_30_RL "Dynamic property of object_30
00????????";
CM_ SG_ 864 ARC_OD_Length_Obj_30_RL "Length of object_30
00??????";
CM_ SG_ 864 ARC_OD_MaintenanceState_Obj_0091 "Maintenance state of object_30
00????????";
CM_ SG_ 864 ARC_OD_Width_Obj_30_RL "Width of object_30
00??????";
CM_ SG_ 864 ARC_OD_RCS_Obj_30_RL "RCS of object_30
00?????????";
CM_ SG_ 864 ARC_OD_Orientation_Obj_30_RL "Orientation of object_30
00???????";
CM_ SG_ 864 ARC_OD_LifeCycle_Obj_30_RL "Life cycle of object_30
00????????";
CM_ SG_ 864 ARC_OD_AabsX_Obj_30_RL "Longitudinal absolution acceleration over ground of object_30
00?????????????";
CM_ SG_ 864 ARC_OD_DistY_Obj_30_RL "Lateral distance of object_30
00????????";
CM_ SG_ 864 ARC_OD_ObstacleProb_Obj_30_RL "Obstacle probability of object_30
00?????????";
CM_ SG_ 864 ARC_OD_VabsY_Obj_30_RL "Lateral absolution velocity over ground of object_30
00????????????";
CM_ SG_ 864 ARC_OD_AabsY_Obj_30_RL "Lateral absolution acceleration over ground of object_30
00?????????????";
CM_ SG_ 864 ARC_OD_DistXStd_Obj_30_RL "Longitudinal distance standard deviation of object_30
00???????????";
CM_ SG_ 864 ARC_OD_DistYStd_Obj_30_RL "Lateral distance standard deviation of object_30
00???????????";
CM_ SG_ 864 ARC_OD_VabsXStd_Obj_30_RL "Longitudinal absolution velocity standard deviation of object_30
00???????????????";
CM_ SG_ 864 ARC_OD_VabsYStd_Obj_30_RL "Lateral absolution velocity standard deviation of object_30
00???????????????";
CM_ SG_ 864 ARC_OD_AabsXStd_Obj_30_RL "Longitudinal absolution acceleration standard deviation of object_30
00????????????????";
CM_ SG_ 865 ARC_OD_DistX_Obj_32_RL "Longitudinal distance of object_32
00????????";
CM_ SG_ 865 ARC_OD_Classification_Obj_32_RL "Classification of object_32
00??????";
CM_ SG_ 865 ARC_OD_AabsYStd_Obj_32_RL "Lateral absolution acceleration standard deviation of object_32
00????????????????";
CM_ SG_ 865 ARC_OD_ClassConf_Obj_32_RL "Classification confidence of object_32
00?????????";
CM_ SG_ 865 ARC_OD_ProbOfExist_Obj_32_RL "Existence probability of object_32
00????????";
CM_ SG_ 865 ARC_OD_VabsX_Obj_32_RL "Longitudinal absolution velocity over ground of object_32
00????????????";
CM_ SG_ 865 ARC_OD_DynProp_Obj_32_RL "Dynamic property of object_32
00????????";
CM_ SG_ 865 ARC_OD_Length_Obj_32_RL "Length of object_32
00??????";
CM_ SG_ 865 ARC_OD_MaintenanceState_Obj_0093 "Maintenance state of object_32
00????????";
CM_ SG_ 865 ARC_OD_Width_Obj_32_RL "Width of object_32
00??????";
CM_ SG_ 865 ARC_OD_RCS_Obj_32_RL "RCS of object_32
00?????????";
CM_ SG_ 865 ARC_OD_Orientation_Obj_32_RL "Orientation of object_32
00???????";
CM_ SG_ 865 ARC_OD_LifeCycle_Obj_32_RL "Life cycle of object_32
00????????";
CM_ SG_ 865 ARC_OD_AabsX_Obj_32_RL "Longitudinal absolution acceleration over ground of object_32
00?????????????";
CM_ SG_ 865 ARC_OD_DistY_Obj_32_RL "Lateral distance of object_32
00????????";
CM_ SG_ 865 ARC_OD_ObstacleProb_Obj_32_RL "Obstacle probability of object_32
00?????????";
CM_ SG_ 865 ARC_OD_VabsY_Obj_32_RL "Lateral absolution velocity over ground of object_32
00????????????";
CM_ SG_ 865 ARC_OD_AabsY_Obj_32_RL "Lateral absolution acceleration over ground of object_32
00?????????????";
CM_ SG_ 865 ARC_OD_DistXStd_Obj_32_RL "Longitudinal distance standard deviation of object_32
00???????????";
CM_ SG_ 865 ARC_OD_DistYStd_Obj_32_RL "Lateral distance standard deviation of object_32
00???????????";
CM_ SG_ 865 ARC_OD_VabsXStd_Obj_32_RL "Longitudinal absolution velocity standard deviation of object_32
00???????????????";
CM_ SG_ 865 ARC_OD_VabsYStd_Obj_32_RL "Lateral absolution velocity standard deviation of object_32
00???????????????";
CM_ SG_ 865 ARC_OD_AabsXStd_Obj_32_RL "Longitudinal absolution acceleration standard deviation of object_32
00????????????????";
CM_ SG_ 866 ARC_OD_DistX_Obj_34_RL "Longitudinal distance of object_34
00????????";
CM_ SG_ 866 ARC_OD_Classification_Obj_34_RL "Classification of object_34
00??????";
CM_ SG_ 866 ARC_OD_AabsYStd_Obj_34_RL "Lateral absolution acceleration standard deviation of object_34
00????????????????";
CM_ SG_ 866 ARC_OD_ClassConf_Obj_34_RL "Classification confidence of object_34
00?????????";
CM_ SG_ 866 ARC_OD_ProbOfExist_Obj_34_RL "Existence probability of object_34
00????????";
CM_ SG_ 866 ARC_OD_VabsX_Obj_34_RL "Longitudinal absolution velocity over ground of object_34
00????????????";
CM_ SG_ 866 ARC_OD_DynProp_Obj_34_RL "Dynamic property of object_34
00????????";
CM_ SG_ 866 ARC_OD_Length_Obj_34_RL "Length of object_34
00??????";
CM_ SG_ 866 ARC_OD_MaintenanceState_Obj_0095 "Maintenance state of object_34
00????????";
CM_ SG_ 866 ARC_OD_Width_Obj_34_RL "Width of object_34
00??????";
CM_ SG_ 866 ARC_OD_RCS_Obj_34_RL "RCS of object_34
00?????????";
CM_ SG_ 866 ARC_OD_Orientation_Obj_34_RL "Orientation of object_34
00???????";
CM_ SG_ 866 ARC_OD_LifeCycle_Obj_34_RL "Life cycle of object_34
00????????";
CM_ SG_ 866 ARC_OD_AabsX_Obj_34_RL "Longitudinal absolution acceleration over ground of object_34
00?????????????";
CM_ SG_ 866 ARC_OD_DistY_Obj_34_RL "Lateral distance of object_34
00????????";
CM_ SG_ 866 ARC_OD_ObstacleProb_Obj_34_RL "Obstacle probability of object_34
00?????????";
CM_ SG_ 866 ARC_OD_VabsY_Obj_34_RL "Lateral absolution velocity over ground of object_34
00????????????";
CM_ SG_ 866 ARC_OD_AabsY_Obj_34_RL "Lateral absolution acceleration over ground of object_34
00?????????????";
CM_ SG_ 866 ARC_OD_DistXStd_Obj_34_RL "Longitudinal distance standard deviation of object_34
00???????????";
CM_ SG_ 866 ARC_OD_DistYStd_Obj_34_RL "Lateral distance standard deviation of object_34
00???????????";
CM_ SG_ 866 ARC_OD_VabsXStd_Obj_34_RL "Longitudinal absolution velocity standard deviation of object_34
00???????????????";
CM_ SG_ 866 ARC_OD_VabsYStd_Obj_34_RL "Lateral absolution velocity standard deviation of object_34
00???????????????";
CM_ SG_ 866 ARC_OD_AabsXStd_Obj_34_RL "Longitudinal absolution acceleration standard deviation of object_34
00????????????????";
CM_ SG_ 867 ARC_OD_DistX_Obj_36_RL "Longitudinal distance of object_36
00????????";
CM_ SG_ 867 ARC_OD_Classification_Obj_36_RL "Classification of object_36
00??????";
CM_ SG_ 867 ARC_OD_AabsYStd_Obj_36_RL "Lateral absolution acceleration standard deviation of object_36
00????????????????";
CM_ SG_ 867 ARC_OD_ClassConf_Obj_36_RL "Classification confidence of object_36
00?????????";
CM_ SG_ 867 ARC_OD_ProbOfExist_Obj_36_RL "Existence probability of object_36
00????????";
CM_ SG_ 867 ARC_OD_VabsX_Obj_36_RL "Longitudinal absolution velocity over ground of object_36
00????????????";
CM_ SG_ 867 ARC_OD_DynProp_Obj_36_RL "Dynamic property of object_36
00????????";
CM_ SG_ 867 ARC_OD_Length_Obj_36_RL "Length of object_36
00??????";
CM_ SG_ 867 ARC_OD_MaintenanceState_Obj_0097 "Maintenance state of object_36
00????????";
CM_ SG_ 867 ARC_OD_Width_Obj_36_RL "Width of object_36
00??????";
CM_ SG_ 867 ARC_OD_RCS_Obj_36_RL "RCS of object_36
00?????????";
CM_ SG_ 867 ARC_OD_Orientation_Obj_36_RL "Orientation of object_36
00???????";
CM_ SG_ 867 ARC_OD_LifeCycle_Obj_36_RL "Life cycle of object_36
00????????";
CM_ SG_ 867 ARC_OD_AabsX_Obj_36_RL "Longitudinal absolution acceleration over ground of object_36
00?????????????";
CM_ SG_ 867 ARC_OD_DistY_Obj_36_RL "Lateral distance of object_36
00????????";
CM_ SG_ 867 ARC_OD_ObstacleProb_Obj_36_RL "Obstacle probability of object_36
00?????????";
CM_ SG_ 867 ARC_OD_VabsY_Obj_36_RL "Lateral absolution velocity over ground of object_36
00????????????";
CM_ SG_ 867 ARC_OD_AabsY_Obj_36_RL "Lateral absolution acceleration over ground of object_36
00?????????????";
CM_ SG_ 867 ARC_OD_DistXStd_Obj_36_RL "Longitudinal distance standard deviation of object_36
00???????????";
CM_ SG_ 867 ARC_OD_DistYStd_Obj_36_RL "Lateral distance standard deviation of object_36
00???????????";
CM_ SG_ 867 ARC_OD_VabsXStd_Obj_36_RL "Longitudinal absolution velocity standard deviation of object_36
00???????????????";
CM_ SG_ 867 ARC_OD_VabsYStd_Obj_36_RL "Lateral absolution velocity standard deviation of object_36
00???????????????";
CM_ SG_ 867 ARC_OD_AabsXStd_Obj_36_RL "Longitudinal absolution acceleration standard deviation of object_36
00????????????????";
CM_ SG_ 868 ARC_OD_DistX_Obj_38_RL "Longitudinal distance of object_38
00????????";
CM_ SG_ 868 ARC_OD_Classification_Obj_38_RL "Classification of object_38
00??????";
CM_ SG_ 868 ARC_OD_AabsYStd_Obj_38_RL "Lateral absolution acceleration standard deviation of object_38
00????????????????";
CM_ SG_ 868 ARC_OD_ClassConf_Obj_38_RL "Classification confidence of object_38
00?????????";
CM_ SG_ 868 ARC_OD_ProbOfExist_Obj_38_RL "Existence probability of object_38
00????????";
CM_ SG_ 868 ARC_OD_VabsX_Obj_38_RL "Longitudinal absolution velocity over ground of object_38
00????????????";
CM_ SG_ 868 ARC_OD_DynProp_Obj_38_RL "Dynamic property of object_38
00????????";
CM_ SG_ 868 ARC_OD_Length_Obj_38_RL "Length of object_38
00??????";
CM_ SG_ 868 ARC_OD_MaintenanceState_Obj_0099 "Maintenance state of object_38
00????????";
CM_ SG_ 868 ARC_OD_Width_Obj_38_RL "Width of object_38
00??????";
CM_ SG_ 868 ARC_OD_RCS_Obj_38_RL "RCS of object_38
00?????????";
CM_ SG_ 868 ARC_OD_Orientation_Obj_38_RL "Orientation of object_38
00???????";
CM_ SG_ 868 ARC_OD_LifeCycle_Obj_38_RL "Life cycle of object_38
00????????";
CM_ SG_ 868 ARC_OD_AabsX_Obj_38_RL "Longitudinal absolution acceleration over ground of object_38
00?????????????";
CM_ SG_ 868 ARC_OD_DistY_Obj_38_RL "Lateral distance of object_38
00????????";
CM_ SG_ 868 ARC_OD_ObstacleProb_Obj_38_RL "Obstacle probability of object_38
00?????????";
CM_ SG_ 868 ARC_OD_VabsY_Obj_38_RL "Lateral absolution velocity over ground of object_38
00????????????";
CM_ SG_ 868 ARC_OD_AabsY_Obj_38_RL "Lateral absolution acceleration over ground of object_38
00?????????????";
CM_ SG_ 868 ARC_OD_DistXStd_Obj_38_RL "Longitudinal distance standard deviation of object_38
00???????????";
CM_ SG_ 868 ARC_OD_DistYStd_Obj_38_RL "Lateral distance standard deviation of object_38
00???????????";
CM_ SG_ 868 ARC_OD_VabsXStd_Obj_38_RL "Longitudinal absolution velocity standard deviation of object_38
00???????????????";
CM_ SG_ 868 ARC_OD_VabsYStd_Obj_38_RL "Lateral absolution velocity standard deviation of object_38
00???????????????";
CM_ SG_ 868 ARC_OD_AabsXStd_Obj_38_RL "Longitudinal absolution acceleration standard deviation of object_38
00????????????????";
CM_ SG_ 869 ARC_OD_DistX_Obj_40_RL "Longitudinal distance of object_40
00????????";
CM_ SG_ 869 ARC_OD_Classification_Obj_40_RL "Classification of object_40
00??????";
CM_ SG_ 869 ARC_OD_AabsYStd_Obj_40_RL "Lateral absolution acceleration standard deviation of object_40
00????????????????";
CM_ SG_ 869 ARC_OD_ClassConf_Obj_40_RL "Classification confidence of object_40
00?????????";
CM_ SG_ 869 ARC_OD_ProbOfExist_Obj_40_RL "Existence probability of object_40
00????????";
CM_ SG_ 869 ARC_OD_VabsX_Obj_40_RL "Longitudinal absolution velocity over ground of object_40
00????????????";
CM_ SG_ 869 ARC_OD_DynProp_Obj_40_RL "Dynamic property of object_40
00????????";
CM_ SG_ 869 ARC_OD_Length_Obj_40_RL "Length of object_40
00??????";
CM_ SG_ 869 ARC_OD_MaintenanceState_Obj_0101 "Maintenance state of object_40
00????????";
CM_ SG_ 869 ARC_OD_Width_Obj_40_RL "Width of object_40
00??????";
CM_ SG_ 869 ARC_OD_RCS_Obj_40_RL "RCS of object_40
00?????????";
CM_ SG_ 869 ARC_OD_Orientation_Obj_40_RL "Orientation of object_40
00???????";
CM_ SG_ 869 ARC_OD_LifeCycle_Obj_40_RL "Life cycle of object_40
00????????";
CM_ SG_ 869 ARC_OD_AabsX_Obj_40_RL "Longitudinal absolution acceleration over ground of object_40
00?????????????";
CM_ SG_ 869 ARC_OD_DistY_Obj_40_RL "Lateral distance of object_40
00????????";
CM_ SG_ 869 ARC_OD_ObstacleProb_Obj_40_RL "Obstacle probability of object_40
00?????????";
CM_ SG_ 869 ARC_OD_VabsY_Obj_40_RL "Lateral absolution velocity over ground of object_40
00????????????";
CM_ SG_ 869 ARC_OD_AabsY_Obj_40_RL "Lateral absolution acceleration over ground of object_40
00?????????????";
CM_ SG_ 869 ARC_OD_DistXStd_Obj_40_RL "Longitudinal distance standard deviation of object_40
00???????????";
CM_ SG_ 869 ARC_OD_DistYStd_Obj_40_RL "Lateral distance standard deviation of object_40
00???????????";
CM_ SG_ 869 ARC_OD_VabsXStd_Obj_40_RL "Longitudinal absolution velocity standard deviation of object_40
00???????????????";
CM_ SG_ 869 ARC_OD_VabsYStd_Obj_40_RL "Lateral absolution velocity standard deviation of object_40
00???????????????";
CM_ SG_ 869 ARC_OD_AabsXStd_Obj_40_RL "Longitudinal absolution acceleration standard deviation of object_40
00????????????????";
CM_ SG_ 870 ARC_OD_DistX_Obj_42_RL "Longitudinal distance of object_42
00????????";
CM_ SG_ 870 ARC_OD_Classification_Obj_42_RL "Classification of object_42
00??????";
CM_ SG_ 870 ARC_OD_AabsYStd_Obj_42_RL "Lateral absolution acceleration standard deviation of object_42
00????????????????";
CM_ SG_ 870 ARC_OD_ClassConf_Obj_42_RL "Classification confidence of object_42
00?????????";
CM_ SG_ 870 ARC_OD_ProbOfExist_Obj_42_RL "Existence probability of object_42
00????????";
CM_ SG_ 870 ARC_OD_VabsX_Obj_42_RL "Longitudinal absolution velocity over ground of object_42
00????????????";
CM_ SG_ 870 ARC_OD_DynProp_Obj_42_RL "Dynamic property of object_42
00????????";
CM_ SG_ 870 ARC_OD_Length_Obj_42_RL "Length of object_42
00??????";
CM_ SG_ 870 ARC_OD_MaintenanceState_Obj_0103 "Maintenance state of object_42
00????????";
CM_ SG_ 870 ARC_OD_Width_Obj_42_RL "Width of object_42
00??????";
CM_ SG_ 870 ARC_OD_RCS_Obj_42_RL "RCS of object_42
00?????????";
CM_ SG_ 870 ARC_OD_Orientation_Obj_42_RL "Orientation of object_42
00???????";
CM_ SG_ 870 ARC_OD_LifeCycle_Obj_42_RL "Life cycle of object_42
00????????";
CM_ SG_ 870 ARC_OD_AabsX_Obj_42_RL "Longitudinal absolution acceleration over ground of object_42
00?????????????";
CM_ SG_ 870 ARC_OD_DistY_Obj_42_RL "Lateral distance of object_42
00????????";
CM_ SG_ 870 ARC_OD_ObstacleProb_Obj_42_RL "Obstacle probability of object_42
00?????????";
CM_ SG_ 870 ARC_OD_VabsY_Obj_42_RL "Lateral absolution velocity over ground of object_42
00????????????";
CM_ SG_ 870 ARC_OD_AabsY_Obj_42_RL "Lateral absolution acceleration over ground of object_42
00?????????????";
CM_ SG_ 870 ARC_OD_DistXStd_Obj_42_RL "Longitudinal distance standard deviation of object_42
00???????????";
CM_ SG_ 870 ARC_OD_DistYStd_Obj_42_RL "Lateral distance standard deviation of object_42
00???????????";
CM_ SG_ 870 ARC_OD_VabsXStd_Obj_42_RL "Longitudinal absolution velocity standard deviation of object_42
00???????????????";
CM_ SG_ 870 ARC_OD_VabsYStd_Obj_42_RL "Lateral absolution velocity standard deviation of object_42
00???????????????";
CM_ SG_ 870 ARC_OD_AabsXStd_Obj_42_RL "Longitudinal absolution acceleration standard deviation of object_42
00????????????????";
CM_ SG_ 871 ARC_OD_DistX_Obj_44_RL "Longitudinal distance of object_44
00????????";
CM_ SG_ 871 ARC_OD_Classification_Obj_44_RL "Classification of object_44
00??????";
CM_ SG_ 871 ARC_OD_AabsYStd_Obj_44_RL "Lateral absolution acceleration standard deviation of object_44
00????????????????";
CM_ SG_ 871 ARC_OD_ClassConf_Obj_44_RL "Classification confidence of object_44
00?????????";
CM_ SG_ 871 ARC_OD_ProbOfExist_Obj_44_RL "Existence probability of object_44
00????????";
CM_ SG_ 871 ARC_OD_VabsX_Obj_44_RL "Longitudinal absolution velocity over ground of object_44
00????????????";
CM_ SG_ 871 ARC_OD_DynProp_Obj_44_RL "Dynamic property of object_44
00????????";
CM_ SG_ 871 ARC_OD_Length_Obj_44_RL "Length of object_44
00??????";
CM_ SG_ 871 ARC_OD_MaintenanceState_Obj_0105 "Maintenance state of object_44
00????????";
CM_ SG_ 871 ARC_OD_Width_Obj_44_RL "Width of object_44
00??????";
CM_ SG_ 871 ARC_OD_RCS_Obj_44_RL "RCS of object_44
00?????????";
CM_ SG_ 871 ARC_OD_Orientation_Obj_44_RL "Orientation of object_44
00???????";
CM_ SG_ 871 ARC_OD_LifeCycle_Obj_44_RL "Life cycle of object_44
00????????";
CM_ SG_ 871 ARC_OD_AabsX_Obj_44_RL "Longitudinal absolution acceleration over ground of object_44
00?????????????";
CM_ SG_ 871 ARC_OD_DistY_Obj_44_RL "Lateral distance of object_44
00????????";
CM_ SG_ 871 ARC_OD_ObstacleProb_Obj_44_RL "Obstacle probability of object_44
00?????????";
CM_ SG_ 871 ARC_OD_VabsY_Obj_44_RL "Lateral absolution velocity over ground of object_44
00????????????";
CM_ SG_ 871 ARC_OD_AabsY_Obj_44_RL "Lateral absolution acceleration over ground of object_44
00?????????????";
CM_ SG_ 871 ARC_OD_DistXStd_Obj_44_RL "Longitudinal distance standard deviation of object_44
00???????????";
CM_ SG_ 871 ARC_OD_DistYStd_Obj_44_RL "Lateral distance standard deviation of object_44
00???????????";
CM_ SG_ 871 ARC_OD_VabsXStd_Obj_44_RL "Longitudinal absolution velocity standard deviation of object_44
00???????????????";
CM_ SG_ 871 ARC_OD_VabsYStd_Obj_44_RL "Lateral absolution velocity standard deviation of object_44
00???????????????";
CM_ SG_ 871 ARC_OD_AabsXStd_Obj_44_RL "Longitudinal absolution acceleration standard deviation of object_44
00????????????????";
CM_ SG_ 872 ARC_OD_DistX_Obj_46_RL "Longitudinal distance of object_46
00????????";
CM_ SG_ 872 ARC_OD_Classification_Obj_46_RL "Classification of object_46
00??????";
CM_ SG_ 872 ARC_OD_AabsYStd_Obj_46_RL "Lateral absolution acceleration standard deviation of object_46
00????????????????";
CM_ SG_ 872 ARC_OD_ClassConf_Obj_46_RL "Classification confidence of object_46
00?????????";
CM_ SG_ 872 ARC_OD_ProbOfExist_Obj_46_RL "Existence probability of object_46
00????????";
CM_ SG_ 872 ARC_OD_VabsX_Obj_46_RL "Longitudinal absolution velocity over ground of object_46
00????????????";
CM_ SG_ 872 ARC_OD_DynProp_Obj_46_RL "Dynamic property of object_46
00????????";
CM_ SG_ 872 ARC_OD_Length_Obj_46_RL "Length of object_46
00??????";
CM_ SG_ 872 ARC_OD_MaintenanceState_Obj_0107 "Maintenance state of object_46
00????????";
CM_ SG_ 872 ARC_OD_Width_Obj_46_RL "Width of object_46
00??????";
CM_ SG_ 872 ARC_OD_RCS_Obj_46_RL "RCS of object_46
00?????????";
CM_ SG_ 872 ARC_OD_Orientation_Obj_46_RL "Orientation of object_46
00???????";
CM_ SG_ 872 ARC_OD_LifeCycle_Obj_46_RL "Life cycle of object_46
00????????";
CM_ SG_ 872 ARC_OD_AabsX_Obj_46_RL "Longitudinal absolution acceleration over ground of object_46
00?????????????";
CM_ SG_ 872 ARC_OD_DistY_Obj_46_RL "Lateral distance of object_46
00????????";
CM_ SG_ 872 ARC_OD_ObstacleProb_Obj_46_RL "Obstacle probability of object_46
00?????????";
CM_ SG_ 872 ARC_OD_VabsY_Obj_46_RL "Lateral absolution velocity over ground of object_46
00????????????";
CM_ SG_ 872 ARC_OD_AabsY_Obj_46_RL "Lateral absolution acceleration over ground of object_46
00?????????????";
CM_ SG_ 872 ARC_OD_DistXStd_Obj_46_RL "Longitudinal distance standard deviation of object_46
00???????????";
CM_ SG_ 872 ARC_OD_DistYStd_Obj_46_RL "Lateral distance standard deviation of object_46
00???????????";
CM_ SG_ 872 ARC_OD_VabsXStd_Obj_46_RL "Longitudinal absolution velocity standard deviation of object_46
00???????????????";
CM_ SG_ 872 ARC_OD_VabsYStd_Obj_46_RL "Lateral absolution velocity standard deviation of object_46
00???????????????";
CM_ SG_ 872 ARC_OD_AabsXStd_Obj_46_RL "Longitudinal absolution acceleration standard deviation of object_46
00????????????????";
CM_ SG_ 873 ARC_OD_DistX_Obj_48_RL "Longitudinal distance of object_48
00????????";
CM_ SG_ 873 ARC_OD_Classification_Obj_48_RL "Classification of object_48
00??????";
CM_ SG_ 873 ARC_OD_AabsYStd_Obj_48_RL "Lateral absolution acceleration standard deviation of object_48
00????????????????";
CM_ SG_ 873 ARC_OD_ClassConf_Obj_48_RL "Classification confidence of object_48
00?????????";
CM_ SG_ 873 ARC_OD_ProbOfExist_Obj_48_RL "Existence probability of object_48
00????????";
CM_ SG_ 873 ARC_OD_VabsX_Obj_48_RL "Longitudinal absolution velocity over ground of object_48
00????????????";
CM_ SG_ 873 ARC_OD_DynProp_Obj_48_RL "Dynamic property of object_48
00????????";
CM_ SG_ 873 ARC_OD_Length_Obj_48_RL "Length of object_48
00??????";
CM_ SG_ 873 ARC_OD_MaintenanceState_Obj_0109 "Maintenance state of object_48
00????????";
CM_ SG_ 873 ARC_OD_Width_Obj_48_RL "Width of object_48
00??????";
CM_ SG_ 873 ARC_OD_RCS_Obj_48_RL "RCS of object_48
00?????????";
CM_ SG_ 873 ARC_OD_Orientation_Obj_48_RL "Orientation of object_48
00???????";
CM_ SG_ 873 ARC_OD_LifeCycle_Obj_48_RL "Life cycle of object_48
00????????";
CM_ SG_ 873 ARC_OD_AabsX_Obj_48_RL "Longitudinal absolution acceleration over ground of object_48
00?????????????";
CM_ SG_ 873 ARC_OD_DistY_Obj_48_RL "Lateral distance of object_48
00????????";
CM_ SG_ 873 ARC_OD_ObstacleProb_Obj_48_RL "Obstacle probability of object_48
00?????????";
CM_ SG_ 873 ARC_OD_VabsY_Obj_48_RL "Lateral absolution velocity over ground of object_48
00????????????";
CM_ SG_ 873 ARC_OD_AabsY_Obj_48_RL "Lateral absolution acceleration over ground of object_48
00?????????????";
CM_ SG_ 873 ARC_OD_DistXStd_Obj_48_RL "Longitudinal distance standard deviation of object_48
00???????????";
CM_ SG_ 873 ARC_OD_DistYStd_Obj_48_RL "Lateral distance standard deviation of object_48
00???????????";
CM_ SG_ 873 ARC_OD_VabsXStd_Obj_48_RL "Longitudinal absolution velocity standard deviation of object_48
00???????????????";
CM_ SG_ 873 ARC_OD_VabsYStd_Obj_48_RL "Lateral absolution velocity standard deviation of object_48
00???????????????";
CM_ SG_ 873 ARC_OD_AabsXStd_Obj_48_RL "Longitudinal absolution acceleration standard deviation of object_48
00????????????????";
CM_ SG_ 874 ARC_OD_DistX_Obj_50_RL "Longitudinal distance of object_50
00????????";
CM_ SG_ 874 ARC_OD_Classification_Obj_50_RL "Classification of object_50
00??????";
CM_ SG_ 874 ARC_OD_AabsYStd_Obj_50_RL "Lateral absolution acceleration standard deviation of object_50
00????????????????";
CM_ SG_ 874 ARC_OD_ClassConf_Obj_50_RL "Classification confidence of object_50
00?????????";
CM_ SG_ 874 ARC_OD_ProbOfExist_Obj_50_RL "Existence probability of object_50
00????????";
CM_ SG_ 874 ARC_OD_VabsX_Obj_50_RL "Longitudinal absolution velocity over ground of object_50
00????????????";
CM_ SG_ 874 ARC_OD_DynProp_Obj_50_RL "Dynamic property of object_50
00????????";
CM_ SG_ 874 ARC_OD_Length_Obj_50_RL "Length of object_50
00??????";
CM_ SG_ 874 ARC_OD_MaintenanceState_Obj_0111 "Maintenance state of object_50
00????????";
CM_ SG_ 874 ARC_OD_Width_Obj_50_RL "Width of object_50
00??????";
CM_ SG_ 874 ARC_OD_RCS_Obj_50_RL "RCS of object_50
00?????????";
CM_ SG_ 874 ARC_OD_Orientation_Obj_50_RL "Orientation of object_50
00???????";
CM_ SG_ 874 ARC_OD_LifeCycle_Obj_50_RL "Life cycle of object_50
00????????";
CM_ SG_ 874 ARC_OD_AabsX_Obj_50_RL "Longitudinal absolution acceleration over ground of object_50
00?????????????";
CM_ SG_ 874 ARC_OD_DistY_Obj_50_RL "Lateral distance of object_50
00????????";
CM_ SG_ 874 ARC_OD_ObstacleProb_Obj_50_RL "Obstacle probability of object_50
00?????????";
CM_ SG_ 874 ARC_OD_VabsY_Obj_50_RL "Lateral absolution velocity over ground of object_50
00????????????";
CM_ SG_ 874 ARC_OD_AabsY_Obj_50_RL "Lateral absolution acceleration over ground of object_50
00?????????????";
CM_ SG_ 874 ARC_OD_DistXStd_Obj_50_RL "Longitudinal distance standard deviation of object_50
00???????????";
CM_ SG_ 874 ARC_OD_DistYStd_Obj_50_RL "Lateral distance standard deviation of object_50
00???????????";
CM_ SG_ 874 ARC_OD_VabsXStd_Obj_50_RL "Longitudinal absolution velocity standard deviation of object_50
00???????????????";
CM_ SG_ 874 ARC_OD_VabsYStd_Obj_50_RL "Lateral absolution velocity standard deviation of object_50
00???????????????";
CM_ SG_ 874 ARC_OD_AabsXStd_Obj_50_RL "Longitudinal absolution acceleration standard deviation of object_50
00????????????????";
CM_ SG_ 875 ARC_OD_DistX_Obj_52_RL "Longitudinal distance of object_52
00????????";
CM_ SG_ 875 ARC_OD_Classification_Obj_52_RL "Classification of object_52
00??????";
CM_ SG_ 875 ARC_OD_AabsYStd_Obj_52_RL "Lateral absolution acceleration standard deviation of object_52
00????????????????";
CM_ SG_ 875 ARC_OD_ClassConf_Obj_52_RL "Classification confidence of object_52
00?????????";
CM_ SG_ 875 ARC_OD_ProbOfExist_Obj_52_RL "Existence probability of object_52
00????????";
CM_ SG_ 875 ARC_OD_VabsX_Obj_52_RL "Longitudinal absolution velocity over ground of object_52
00????????????";
CM_ SG_ 875 ARC_OD_DynProp_Obj_52_RL "Dynamic property of object_52
00????????";
CM_ SG_ 875 ARC_OD_Length_Obj_52_RL "Length of object_52
00??????";
CM_ SG_ 875 ARC_OD_MaintenanceState_Obj_0113 "Maintenance state of object_52
00????????";
CM_ SG_ 875 ARC_OD_Width_Obj_52_RL "Width of object_52
00??????";
CM_ SG_ 875 ARC_OD_RCS_Obj_52_RL "RCS of object_52
00?????????";
CM_ SG_ 875 ARC_OD_Orientation_Obj_52_RL "Orientation of object_52
00???????";
CM_ SG_ 875 ARC_OD_LifeCycle_Obj_52_RL "Life cycle of object_52
00????????";
CM_ SG_ 875 ARC_OD_AabsX_Obj_52_RL "Longitudinal absolution acceleration over ground of object_52
00?????????????";
CM_ SG_ 875 ARC_OD_DistY_Obj_52_RL "Lateral distance of object_52
00????????";
CM_ SG_ 875 ARC_OD_ObstacleProb_Obj_52_RL "Obstacle probability of object_52
00?????????";
CM_ SG_ 875 ARC_OD_VabsY_Obj_52_RL "Lateral absolution velocity over ground of object_52
00????????????";
CM_ SG_ 875 ARC_OD_AabsY_Obj_52_RL "Lateral absolution acceleration over ground of object_52
00?????????????";
CM_ SG_ 875 ARC_OD_DistXStd_Obj_52_RL "Longitudinal distance standard deviation of object_52
00???????????";
CM_ SG_ 875 ARC_OD_DistYStd_Obj_52_RL "Lateral distance standard deviation of object_52
00???????????";
CM_ SG_ 875 ARC_OD_VabsXStd_Obj_52_RL "Longitudinal absolution velocity standard deviation of object_52
00???????????????";
CM_ SG_ 875 ARC_OD_VabsYStd_Obj_52_RL "Lateral absolution velocity standard deviation of object_52
00???????????????";
CM_ SG_ 875 ARC_OD_AabsXStd_Obj_52_RL "Longitudinal absolution acceleration standard deviation of object_52
00????????????????";
CM_ SG_ 876 ARC_OD_DistX_Obj_54_RL "Longitudinal distance of object_54
00????????";
CM_ SG_ 876 ARC_OD_Classification_Obj_54_RL "Classification of object_54
00??????";
CM_ SG_ 876 ARC_OD_AabsYStd_Obj_54_RL "Lateral absolution acceleration standard deviation of object_54
00????????????????";
CM_ SG_ 876 ARC_OD_ClassConf_Obj_54_RL "Classification confidence of object_54
00?????????";
CM_ SG_ 876 ARC_OD_ProbOfExist_Obj_54_RL "Existence probability of object_54
00????????";
CM_ SG_ 876 ARC_OD_VabsX_Obj_54_RL "Longitudinal absolution velocity over ground of object_54
00????????????";
CM_ SG_ 876 ARC_OD_DynProp_Obj_54_RL "Dynamic property of object_54
00????????";
CM_ SG_ 876 ARC_OD_Length_Obj_54_RL "Length of object_54
00??????";
CM_ SG_ 876 ARC_OD_MaintenanceState_Obj_0115 "Maintenance state of object_54
00????????";
CM_ SG_ 876 ARC_OD_Width_Obj_54_RL "Width of object_54
00??????";
CM_ SG_ 876 ARC_OD_RCS_Obj_54_RL "RCS of object_54
00?????????";
CM_ SG_ 876 ARC_OD_Orientation_Obj_54_RL "Orientation of object_54
00???????";
CM_ SG_ 876 ARC_OD_LifeCycle_Obj_54_RL "Life cycle of object_54
00????????";
CM_ SG_ 876 ARC_OD_AabsX_Obj_54_RL "Longitudinal absolution acceleration over ground of object_54
00?????????????";
CM_ SG_ 876 ARC_OD_DistY_Obj_54_RL "Lateral distance of object_54
00????????";
CM_ SG_ 876 ARC_OD_ObstacleProb_Obj_54_RL "Obstacle probability of object_54
00?????????";
CM_ SG_ 876 ARC_OD_VabsY_Obj_54_RL "Lateral absolution velocity over ground of object_54
00????????????";
CM_ SG_ 876 ARC_OD_AabsY_Obj_54_RL "Lateral absolution acceleration over ground of object_54
00?????????????";
CM_ SG_ 876 ARC_OD_DistXStd_Obj_54_RL "Longitudinal distance standard deviation of object_54
00???????????";
CM_ SG_ 876 ARC_OD_DistYStd_Obj_54_RL "Lateral distance standard deviation of object_54
00???????????";
CM_ SG_ 876 ARC_OD_VabsXStd_Obj_54_RL "Longitudinal absolution velocity standard deviation of object_54
00???????????????";
CM_ SG_ 876 ARC_OD_VabsYStd_Obj_54_RL "Lateral absolution velocity standard deviation of object_54
00???????????????";
CM_ SG_ 876 ARC_OD_AabsXStd_Obj_54_RL "Longitudinal absolution acceleration standard deviation of object_54
00????????????????";
CM_ SG_ 877 ARC_OD_DistX_Obj_56_RL "Longitudinal distance of object_56
00????????";
CM_ SG_ 877 ARC_OD_Classification_Obj_56_RL "Classification of object_56
00??????";
CM_ SG_ 877 ARC_OD_AabsYStd_Obj_56_RL "Lateral absolution acceleration standard deviation of object_56
00????????????????";
CM_ SG_ 877 ARC_OD_ClassConf_Obj_56_RL "Classification confidence of object_56
00?????????";
CM_ SG_ 877 ARC_OD_ProbOfExist_Obj_56_RL "Existence probability of object_56
00????????";
CM_ SG_ 877 ARC_OD_VabsX_Obj_56_RL "Longitudinal absolution velocity over ground of object_56
00????????????";
CM_ SG_ 877 ARC_OD_DynProp_Obj_56_RL "Dynamic property of object_56
00????????";
CM_ SG_ 877 ARC_OD_Length_Obj_56_RL "Length of object_56
00??????";
CM_ SG_ 877 ARC_OD_MaintenanceState_Obj_0117 "Maintenance state of object_56
00????????";
CM_ SG_ 877 ARC_OD_Width_Obj_56_RL "Width of object_56
00??????";
CM_ SG_ 877 ARC_OD_RCS_Obj_56_RL "RCS of object_56
00?????????";
CM_ SG_ 877 ARC_OD_Orientation_Obj_56_RL "Orientation of object_56
00???????";
CM_ SG_ 877 ARC_OD_LifeCycle_Obj_56_RL "Life cycle of object_56
00????????";
CM_ SG_ 877 ARC_OD_AabsX_Obj_56_RL "Longitudinal absolution acceleration over ground of object_56
00?????????????";
CM_ SG_ 877 ARC_OD_DistY_Obj_56_RL "Lateral distance of object_56
00????????";
CM_ SG_ 877 ARC_OD_ObstacleProb_Obj_56_RL "Obstacle probability of object_56
00?????????";
CM_ SG_ 877 ARC_OD_VabsY_Obj_56_RL "Lateral absolution velocity over ground of object_56
00????????????";
CM_ SG_ 877 ARC_OD_AabsY_Obj_56_RL "Lateral absolution acceleration over ground of object_56
00?????????????";
CM_ SG_ 877 ARC_OD_DistXStd_Obj_56_RL "Longitudinal distance standard deviation of object_56
00???????????";
CM_ SG_ 877 ARC_OD_DistYStd_Obj_56_RL "Lateral distance standard deviation of object_56
00???????????";
CM_ SG_ 877 ARC_OD_VabsXStd_Obj_56_RL "Longitudinal absolution velocity standard deviation of object_56
00???????????????";
CM_ SG_ 877 ARC_OD_VabsYStd_Obj_56_RL "Lateral absolution velocity standard deviation of object_56
00???????????????";
CM_ SG_ 877 ARC_OD_AabsXStd_Obj_56_RL "Longitudinal absolution acceleration standard deviation of object_56
00????????????????";
CM_ SG_ 878 ARC_OD_DistX_Obj_58_RL "Longitudinal distance of object_58
00????????";
CM_ SG_ 878 ARC_OD_Classification_Obj_58_RL "Classification of object_58
00??????";
CM_ SG_ 878 ARC_OD_AabsYStd_Obj_58_RL "Lateral absolution acceleration standard deviation of object_58
00????????????????";
CM_ SG_ 878 ARC_OD_ClassConf_Obj_58_RL "Classification confidence of object_58
00?????????";
CM_ SG_ 878 ARC_OD_ProbOfExist_Obj_58_RL "Existence probability of object_58
00????????";
CM_ SG_ 878 ARC_OD_VabsX_Obj_58_RL "Longitudinal absolution velocity over ground of object_58
00????????????";
CM_ SG_ 878 ARC_OD_DynProp_Obj_58_RL "Dynamic property of object_58
00????????";
CM_ SG_ 878 ARC_OD_Length_Obj_58_RL "Length of object_58
00??????";
CM_ SG_ 878 ARC_OD_MaintenanceState_Obj_0119 "Maintenance state of object_58
00????????";
CM_ SG_ 878 ARC_OD_Width_Obj_58_RL "Width of object_58
00??????";
CM_ SG_ 878 ARC_OD_RCS_Obj_58_RL "RCS of object_58
00?????????";
CM_ SG_ 878 ARC_OD_Orientation_Obj_58_RL "Orientation of object_58
00???????";
CM_ SG_ 878 ARC_OD_LifeCycle_Obj_58_RL "Life cycle of object_58
00????????";
CM_ SG_ 878 ARC_OD_AabsX_Obj_58_RL "Longitudinal absolution acceleration over ground of object_58
00?????????????";
CM_ SG_ 878 ARC_OD_DistY_Obj_58_RL "Lateral distance of object_58
00????????";
CM_ SG_ 878 ARC_OD_ObstacleProb_Obj_58_RL "Obstacle probability of object_58
00?????????";
CM_ SG_ 878 ARC_OD_VabsY_Obj_58_RL "Lateral absolution velocity over ground of object_58
00????????????";
CM_ SG_ 878 ARC_OD_AabsY_Obj_58_RL "Lateral absolution acceleration over ground of object_58
00?????????????";
CM_ SG_ 878 ARC_OD_DistXStd_Obj_58_RL "Longitudinal distance standard deviation of object_58
00???????????";
CM_ SG_ 878 ARC_OD_DistYStd_Obj_58_RL "Lateral distance standard deviation of object_58
00???????????";
CM_ SG_ 878 ARC_OD_VabsXStd_Obj_58_RL "Longitudinal absolution velocity standard deviation of object_58
00???????????????";
CM_ SG_ 878 ARC_OD_VabsYStd_Obj_58_RL "Lateral absolution velocity standard deviation of object_58
00???????????????";
CM_ SG_ 878 ARC_OD_AabsXStd_Obj_58_RL "Longitudinal absolution acceleration standard deviation of object_58
00????????????????";
CM_ SG_ 266 ESC_FrP02_10A_CRC "E2E profile 1 ����CRC-8-SAE J1850��x8+x4 +x3 +x2 +1
Byte1-Byte7����CRCУ��";
CM_ SG_ 266 ESC_FrP02_10A_RC "/";
CM_ SG_ 266 ESC_RLWhlSpdV "���������Ч��";
CM_ SG_ 266 ESC_RLWhlDir "������ٷ���";
CM_ SG_ 266 ESC_RLWhlSpd "���������";
CM_ SG_ 266 ESC_RRWhlSpdV "�Һ�������Ч��";
CM_ SG_ 266 ESC_RRWhlDir "�Һ����ٷ���";
CM_ SG_ 266 ESC_RRWhlSpd "�Һ�������";
CM_ SG_ 266 ESC_RRWhlDirV "�Һ����ٷ�����Ч��";
CM_ SG_ 266 ESC_RLWhlDirV "������ٷ�����Ч��";
CM_ SG_ 268 ESC_FrP04_10C_CRC "E2E profile 1 ����CRC-8-SAE J1850��x8+x4 +x3 +x2 +1
Byte1-Byte7����CRCУ��";
CM_ SG_ 268 ESC_FrP04_10C_RC "/";
CM_ SG_ 268 ESC_FRWhlSpdV "��ǰ������Ч��";
CM_ SG_ 268 ESC_FRWhlDir "��ǰ�ַ���";
CM_ SG_ 268 ESC_FRWhlSpd "��ǰ������";
CM_ SG_ 268 ESC_FLWhlSpdV "��ǰ������Ч��";
CM_ SG_ 268 ESC_FLWhlDir "��ǰ�ַ���";
CM_ SG_ 268 ESC_FLWhlSpd "��ǰ������";
CM_ SG_ 268 ESC_FRWhlDirV "��ǰ�ַ�����Ч��";
CM_ SG_ 268 ESC_FLWhlDirV "��ǰ�ַ�����Ч��";
CM_ SG_ 271 ESC_LatSenSts "������ٶ���Ч��";
CM_ SG_ 271 ESC_YRSenSts "��ڽ��ٶ���Ч��";
CM_ SG_ 271 ESC_LgtSenSt "������ٶ���Ч��";
CM_ SG_ 271 ESC_YR "��ڽ��ٶ�";
CM_ SG_ 271 ESC_LatAccelSenVal "������ٶ�ֵ";
CM_ SG_ 271 ESC_LgtAccel "������ٶ�ֵ";
CM_ SG_ 277 EPS_FrP01_115_CRC "E2E profile 1 ����CRC-8-SAE J1850��x8+x4 +x3 +x2 +1
Byte1-Byte7����CRCУ��";
CM_ SG_ 277 EPS_FrP01_115_RC "/";
CM_ SG_ 277 EPS_StrgWhlAngl "������ת�ǣ������Ҹ���";
CM_ SG_ 277 EPS_StrgAnglSpd "������ת������";
CM_ SG_ 277 EPS_StrgAnglSpdV "������ת��������Ч��";
CM_ SG_ 277 EPS_StrgWhlAnglV "Steering Wheel Angle Validity";
CM_ SG_ 277 EPS_StrgWhlAnglSenCalSts "Steering Wheel Angle Sensor Calibration Status";
CM_ SG_ 805 ESC_VehSpd "����";
CM_ SG_ 805 ESC_VehSpdV "������Ч��";
CM_ SG_ 805 ESC_VDCCtrlActv "VDC�Ƿ񼤻�";
CM_ SG_ 834 ICM_VehSpdDispV "/";
CM_ SG_ 834 ICM_TotOdoV "Total Odometer sts
�ۼ������Ч��־λ";
CM_ SG_ 834 ICM_VehSpdDisp "VehicleSpeed Display
IC��ʾ����";
CM_ SG_ 834 ICM_TotOdo "Total Odometer
�ۼ����";
CM_ SG_ 819 Sync_Counter "ʱ��ͬ��-������������ֵ";
CM_ SG_ 819 Sync_CRC "ʱ��ͬ��-CRCУ��ֵ";
CM_ SG_ 819 Sync_OVS "ʱ��ͬ��-������� Overflow of seconds";
CM_ SG_ 819 Sync_Resd "ʱ��ͬ��-������Ϣ";
CM_ SG_ 819 Sync_SGW "ʱ��ͬ��-ͬ��״̬";
CM_ SG_ 819 Sync_SyncTime "ʱ��ͬ��-����ͬ��ʱ��";
CM_ SG_ 819 Sync_TimeDomain "ʱ��ͬ��-ʱ��ͬ����";
CM_ SG_ 819 Sync_Type "ʱ��ͬ��-֡����";
CM_ SG_ 267 ESC_FrP03_10B_CRC_1 "E2E profile 1 ����CRC-8-SAE J1850��x8+x4 +x3 +x2 +1
Byte1-Byte7����CRCУ��";
CM_ SG_ 267 ESC_EBDActv "EBD����״̬";
CM_ SG_ 267 ESC_TCSActv "TCS����״̬";
CM_ SG_ 267 ESC_ABSActv "ABS����״̬";
CM_ SG_ 267 ESC_ESCFld "ESC�ź���ʾESCʧ��";
CM_ SG_ 267 ESC_CDPActv "CDP����״̬";
CM_ SG_ 267 ESC_HDCSts "HDC״̬";
CM_ SG_ 267 ESC_Off "ESP�ر�";
CM_ SG_ 267 ESC_ABAAvlbl "ABA(Adaptive Brake Assistance) is available
����Ӧ�ƶ��������ܿ���";
CM_ SG_ 267 ESC_ABAActv "ABA(Adaptive Brake Assistance) is active
����Ӧ�ƶ��������ܼ���";
CM_ SG_ 267 ESC_FrP03_10B_CRC_3 "E2E profile 1 ����CRC-8-SAE J1850��x8+x4 +x3 +x2 +1
Byte17-Byte23����CRCУ��";
CM_ SG_ 267 ESC_FrP03_10B_CRC_4 "E2E profile 1 ����CRC-8-SAE J1850��x8+x4 +x3 +x2 +1
Byte25-Byte31����CRCУ��";
CM_ SG_ 267 ESC_FrP03_10B_CRC_2 "E2E profile 1 ����CRC-8-SAE J1850��x8+x4 +x3 +x2 +1
Byte9-Byte15����CRCУ��";
CM_ SG_ 181 EHB_BrkPedlAppld "�ƶ�̤���Ƿ񱻼�ʻԱ����";
CM_ SG_ 181 EHB_BrkPedlAppldSts "BrakePedalApplied�ź�״̬";
CM_ SG_ 181 EHB_CtrlrFltSts "Controller fault status
����ECU��ǰ����״̬";
CM_ SG_ 181 EHB_FrP01_B5_CRC "E2E profile 1 ����CRC-8-SAE J1850��x8+x4 +x3 +x2 +1
Byte1-Byte7����CRCУ��";
BA_DEF_ BO_  "GenMsgCycleTime" INT 0 0;
BA_DEF_ BO_  "GenMsgSendType" ENUM  "Cyclic","NotUsed","Event","NotUsed","NotUsed","NotUsed","NotUsed","IfActive","NoMsgSendType","NotUsed";
BA_DEF_ BO_  "GenMsgStartDelayTime" INT 0 0;
BA_DEF_ BO_  "VFrameFormat" ENUM  "StandardCAN","ExtendedCAN","reserved","reserved","reserved","reserved","reserved","reserved","reserved","reserved","reserved","reserved","reserved","reserved","StandardCAN_FD","ExtendedCAN_FD";
BA_DEF_ SG_  "GenSigInactiveValue" INT 0 0;
BA_DEF_ SG_  "GenSigSendType" ENUM  "Cyclic","OnWrite","OnWriteWithRepetition","OnChange","OnChangeWithRepetition","IfActive","IfActiveWithRepetition","NoSigSendType","NotUsed","NotUsed","NotUsed","NotUsed","NotUsed";
BA_DEF_ SG_  "GenSigStartValue" INT 0 0;
BA_DEF_ SG_  "SystemSignalLongSymbol" STRING ;
BA_DEF_DEF_  "GenMsgCycleTime" 0;
BA_DEF_DEF_  "GenMsgSendType" "Cyclic";
BA_DEF_DEF_  "GenMsgStartDelayTime" 0;
BA_DEF_DEF_  "VFrameFormat" "ExtendedCAN_FD";
BA_DEF_DEF_  "GenSigInactiveValue" 0;
BA_DEF_DEF_  "GenSigSendType" "Cyclic";
BA_DEF_DEF_  "GenSigStartValue" 0;
BA_DEF_DEF_  "SystemSignalLongSymbol" "";
BA_ "GenMsgCycleTime" BO_ 860 50;
BA_ "VFrameFormat" BO_ 860 14;
BA_ "GenMsgCycleTime" BO_ 861 50;
BA_ "VFrameFormat" BO_ 861 14;
BA_ "GenMsgCycleTime" BO_ 862 50;
BA_ "VFrameFormat" BO_ 862 14;
BA_ "GenMsgCycleTime" BO_ 863 50;
BA_ "VFrameFormat" BO_ 863 14;
BA_ "GenMsgCycleTime" BO_ 864 50;
BA_ "VFrameFormat" BO_ 864 14;
BA_ "GenMsgCycleTime" BO_ 865 50;
BA_ "VFrameFormat" BO_ 865 14;
BA_ "GenMsgCycleTime" BO_ 866 50;
BA_ "VFrameFormat" BO_ 866 14;
BA_ "GenMsgCycleTime" BO_ 867 50;
BA_ "VFrameFormat" BO_ 867 14;
BA_ "GenMsgCycleTime" BO_ 868 50;
BA_ "VFrameFormat" BO_ 868 14;
BA_ "GenMsgCycleTime" BO_ 869 50;
BA_ "VFrameFormat" BO_ 869 14;
BA_ "GenMsgCycleTime" BO_ 870 50;
BA_ "VFrameFormat" BO_ 870 14;
BA_ "GenMsgCycleTime" BO_ 871 50;
BA_ "VFrameFormat" BO_ 871 14;
BA_ "GenMsgCycleTime" BO_ 872 50;
BA_ "VFrameFormat" BO_ 872 14;
BA_ "GenMsgCycleTime" BO_ 873 50;
BA_ "VFrameFormat" BO_ 873 14;
BA_ "GenMsgCycleTime" BO_ 874 50;
BA_ "VFrameFormat" BO_ 874 14;
BA_ "GenMsgCycleTime" BO_ 875 50;
BA_ "VFrameFormat" BO_ 875 14;
BA_ "GenMsgCycleTime" BO_ 876 50;
BA_ "VFrameFormat" BO_ 876 14;
BA_ "GenMsgCycleTime" BO_ 877 50;
BA_ "VFrameFormat" BO_ 877 14;
BA_ "GenMsgCycleTime" BO_ 878 50;
BA_ "VFrameFormat" BO_ 878 14;
BA_ "GenMsgCycleTime" BO_ 266 20;
BA_ "VFrameFormat" BO_ 266 14;
BA_ "GenMsgCycleTime" BO_ 268 20;
BA_ "VFrameFormat" BO_ 268 14;
BA_ "GenMsgCycleTime" BO_ 271 20;
BA_ "VFrameFormat" BO_ 271 14;
BA_ "GenMsgCycleTime" BO_ 277 20;
BA_ "VFrameFormat" BO_ 277 14;
BA_ "GenMsgCycleTime" BO_ 805 100;
BA_ "VFrameFormat" BO_ 805 14;
BA_ "GenMsgCycleTime" BO_ 834 100;
BA_ "VFrameFormat" BO_ 834 14;
BA_ "GenMsgCycleTime" BO_ 819 500;
BA_ "VFrameFormat" BO_ 819 14;
BA_ "GenMsgCycleTime" BO_ 267 20;
BA_ "VFrameFormat" BO_ 267 14;
BA_ "GenMsgCycleTime" BO_ 269 20;
BA_ "VFrameFormat" BO_ 269 14;
BA_ "VFrameFormat" BO_ 181 14;
BA_ "SystemSignalLongSymbol" SG_ 860 ARC_OD_MaintenanceState_Obj_0083 "ARC_OD_MaintenanceState_Obj_22_RL";
BA_ "SystemSignalLongSymbol" SG_ 860 ARC_OD_MaintenanceState_Obj_0084 "ARC_OD_MaintenanceState_Obj_23_RL";
BA_ "SystemSignalLongSymbol" SG_ 861 ARC_OD_MaintenanceState_Obj_0085 "ARC_OD_MaintenanceState_Obj_24_RL";
BA_ "SystemSignalLongSymbol" SG_ 861 ARC_OD_MaintenanceState_Obj_0086 "ARC_OD_MaintenanceState_Obj_25_RL";
BA_ "SystemSignalLongSymbol" SG_ 862 ARC_OD_MaintenanceState_Obj_0087 "ARC_OD_MaintenanceState_Obj_26_RL";
BA_ "SystemSignalLongSymbol" SG_ 862 ARC_OD_MaintenanceState_Obj_0088 "ARC_OD_MaintenanceState_Obj_27_RL";
BA_ "SystemSignalLongSymbol" SG_ 863 ARC_OD_MaintenanceState_Obj_0089 "ARC_OD_MaintenanceState_Obj_28_RL";
BA_ "SystemSignalLongSymbol" SG_ 863 ARC_OD_MaintenanceState_Obj_0090 "ARC_OD_MaintenanceState_Obj_29_RL";
BA_ "SystemSignalLongSymbol" SG_ 864 ARC_OD_MaintenanceState_Obj_0091 "ARC_OD_MaintenanceState_Obj_30_RL";
BA_ "SystemSignalLongSymbol" SG_ 864 ARC_OD_MaintenanceState_Obj_0092 "ARC_OD_MaintenanceState_Obj_31_RL";
BA_ "SystemSignalLongSymbol" SG_ 865 ARC_OD_MaintenanceState_Obj_0093 "ARC_OD_MaintenanceState_Obj_32_RL";
BA_ "SystemSignalLongSymbol" SG_ 865 ARC_OD_MaintenanceState_Obj_0094 "ARC_OD_MaintenanceState_Obj_33_RL";
BA_ "SystemSignalLongSymbol" SG_ 866 ARC_OD_MaintenanceState_Obj_0095 "ARC_OD_MaintenanceState_Obj_34_RL";
BA_ "SystemSignalLongSymbol" SG_ 866 ARC_OD_MaintenanceState_Obj_0096 "ARC_OD_MaintenanceState_Obj_35_RL";
BA_ "SystemSignalLongSymbol" SG_ 867 ARC_OD_MaintenanceState_Obj_0097 "ARC_OD_MaintenanceState_Obj_36_RL";
BA_ "SystemSignalLongSymbol" SG_ 867 ARC_OD_MaintenanceState_Obj_0098 "ARC_OD_MaintenanceState_Obj_37_RL";
BA_ "SystemSignalLongSymbol" SG_ 868 ARC_OD_MaintenanceState_Obj_0099 "ARC_OD_MaintenanceState_Obj_38_RL";
BA_ "SystemSignalLongSymbol" SG_ 868 ARC_OD_MaintenanceState_Obj_0100 "ARC_OD_MaintenanceState_Obj_39_RL";
BA_ "SystemSignalLongSymbol" SG_ 869 ARC_OD_MaintenanceState_Obj_0101 "ARC_OD_MaintenanceState_Obj_40_RL";
BA_ "SystemSignalLongSymbol" SG_ 869 ARC_OD_MaintenanceState_Obj_0102 "ARC_OD_MaintenanceState_Obj_41_RL";
BA_ "SystemSignalLongSymbol" SG_ 870 ARC_OD_MaintenanceState_Obj_0103 "ARC_OD_MaintenanceState_Obj_42_RL";
BA_ "SystemSignalLongSymbol" SG_ 870 ARC_OD_MaintenanceState_Obj_0104 "ARC_OD_MaintenanceState_Obj_43_RL";
BA_ "SystemSignalLongSymbol" SG_ 871 ARC_OD_MaintenanceState_Obj_0105 "ARC_OD_MaintenanceState_Obj_44_RL";
BA_ "SystemSignalLongSymbol" SG_ 871 ARC_OD_MaintenanceState_Obj_0106 "ARC_OD_MaintenanceState_Obj_45_RL";
BA_ "SystemSignalLongSymbol" SG_ 872 ARC_OD_MaintenanceState_Obj_0107 "ARC_OD_MaintenanceState_Obj_46_RL";
BA_ "SystemSignalLongSymbol" SG_ 872 ARC_OD_MaintenanceState_Obj_0108 "ARC_OD_MaintenanceState_Obj_47_RL";
BA_ "SystemSignalLongSymbol" SG_ 873 ARC_OD_MaintenanceState_Obj_0109 "ARC_OD_MaintenanceState_Obj_48_RL";
BA_ "SystemSignalLongSymbol" SG_ 873 ARC_OD_MaintenanceState_Obj_0110 "ARC_OD_MaintenanceState_Obj_49_RL";
BA_ "SystemSignalLongSymbol" SG_ 874 ARC_OD_MaintenanceState_Obj_0111 "ARC_OD_MaintenanceState_Obj_50_RL";
BA_ "SystemSignalLongSymbol" SG_ 874 ARC_OD_MaintenanceState_Obj_0112 "ARC_OD_MaintenanceState_Obj_51_RL";
BA_ "SystemSignalLongSymbol" SG_ 875 ARC_OD_MaintenanceState_Obj_0113 "ARC_OD_MaintenanceState_Obj_52_RL";
BA_ "SystemSignalLongSymbol" SG_ 875 ARC_OD_MaintenanceState_Obj_0114 "ARC_OD_MaintenanceState_Obj_53_RL";
BA_ "SystemSignalLongSymbol" SG_ 876 ARC_OD_MaintenanceState_Obj_0115 "ARC_OD_MaintenanceState_Obj_54_RL";
BA_ "SystemSignalLongSymbol" SG_ 876 ARC_OD_MaintenanceState_Obj_0116 "ARC_OD_MaintenanceState_Obj_55_RL";
BA_ "SystemSignalLongSymbol" SG_ 877 ARC_OD_MaintenanceState_Obj_0117 "ARC_OD_MaintenanceState_Obj_56_RL";
BA_ "SystemSignalLongSymbol" SG_ 877 ARC_OD_MaintenanceState_Obj_0118 "ARC_OD_MaintenanceState_Obj_57_RL";
BA_ "SystemSignalLongSymbol" SG_ 878 ARC_OD_MaintenanceState_Obj_0119 "ARC_OD_MaintenanceState_Obj_58_RL";
BA_ "SystemSignalLongSymbol" SG_ 878 ARC_OD_MaintenanceState_Obj_0120 "ARC_OD_MaintenanceState_Obj_59_RL";
BA_ "GenSigStartValue" SG_ 266 ESC_RLWhlSpdV 1;
BA_ "GenSigStartValue" SG_ 266 ESC_RLWhlDir 3;
BA_ "GenSigStartValue" SG_ 266 ESC_RRWhlSpdV 1;
BA_ "GenSigStartValue" SG_ 266 ESC_RRWhlDir 3;
BA_ "GenSigStartValue" SG_ 268 ESC_FRWhlSpdV 1;
BA_ "GenSigStartValue" SG_ 268 ESC_FRWhlDir 3;
BA_ "GenSigStartValue" SG_ 268 ESC_FLWhlSpdV 1;
BA_ "GenSigStartValue" SG_ 268 ESC_FLWhlDir 3;
BA_ "GenSigStartValue" SG_ 268 ESC_FRWhlDirV 1;
BA_ "GenSigStartValue" SG_ 268 ESC_FLWhlDirV 1;
BA_ "GenSigStartValue" SG_ 271 ESC_YR 30000;
BA_ "GenSigStartValue" SG_ 271 ESC_LatAccelSenVal 30000;
BA_ "GenSigStartValue" SG_ 271 ESC_LgtAccel 6000;
BA_ "GenSigStartValue" SG_ 277 EPS_StrgWhlAngl 32768;
BA_ "GenSigStartValue" SG_ 834 ICM_VehSpdDispV 1;
BA_ "GenSigStartValue" SG_ 267 ESC_Off 1;
VAL_ 860 ARC_OD_Classification_Obj_22_RL 0 "Unknow" 1 "Person" 2 "Bimo" 3 "Car" 4 "Truck" 5 "Barrier" 6 "Reserved" 7 "Reserved" ;
VAL_ 860 ARC_OD_DynProp_Obj_22_RL 0 "MOVING" 1 "STATIONARY" 2 "ONCOMING" 3 "CROSSING_LEFT2RIGHT" 4 "CROSSING_RIGHT2LEFT" 5 "UNKNOWN" 6 "STOPPED" 7 "RESERVED" ;
VAL_ 860 ARC_OD_MaintenanceState_Obj_0083 0 "INVALID" 1 "NEW" 2 "MEASURED" 3 "PREDICTED" ;
VAL_ 860 ARC_OD_Classification_Obj_23_RL 0 "Unknow" 1 "Person" 2 "Bimo" 3 "Car" 4 "Truck" 5 "Barrier" 6 "Reserved" 7 "Reserved" ;
VAL_ 860 ARC_OD_DynProp_Obj_23_RL 0 "STATIONAR" 1 "MOVIN" 2 "ONCOMING" 3 "STOPPE" 4 "CROSSING_LEFT2RIGH" 5 "CROSSING_RIGHT2LEF" 6 "RESERVE" 7 "RESERVED" ;
VAL_ 860 ARC_OD_MaintenanceState_Obj_0084 0 "INVALID" 1 "NEW" 2 "MEASURED" 3 "PREDICTED" ;
VAL_ 861 ARC_OD_Classification_Obj_24_RL 0 "Unknow" 1 "Person" 2 "Bimo" 3 "Car" 4 "Truck" 5 "Barrier" 6 "Reserved" 7 "Reserved" ;
VAL_ 861 ARC_OD_DynProp_Obj_24_RL 0 "MOVING" 1 "STATIONARY" 2 "ONCOMING" 3 "CROSSING_LEFT2RIGHT" 4 "CROSSING_RIGHT2LEFT" 5 "UNKNOWN" 6 "STOPPED" 7 "RESERVED" ;
VAL_ 861 ARC_OD_MaintenanceState_Obj_0085 0 "INVALID" 1 "NEW" 2 "MEASURED" 3 "PREDICTED" ;
VAL_ 861 ARC_OD_Classification_Obj_25_RL 0 "Unknow" 1 "Person" 2 "Bimo" 3 "Car" 4 "Truck" 5 "Barrier" 6 "Reserved" 7 "Reserved" ;
VAL_ 861 ARC_OD_DynProp_Obj_25_RL 0 "STATIONAR" 1 "MOVIN" 2 "ONCOMING" 3 "STOPPE" 4 "CROSSING_LEFT2RIGH" 5 "CROSSING_RIGHT2LEF" 6 "RESERVE" 7 "RESERVED" ;
VAL_ 861 ARC_OD_MaintenanceState_Obj_0086 0 "INVALID" 1 "NEW" 2 "MEASURED" 3 "PREDICTED" ;
VAL_ 862 ARC_OD_Classification_Obj_26_RL 0 "Unknow" 1 "Person" 2 "Bimo" 3 "Car" 4 "Truck" 5 "Barrier" 6 "Reserved" 7 "Reserved" ;
VAL_ 862 ARC_OD_DynProp_Obj_26_RL 0 "MOVING" 1 "STATIONARY" 2 "ONCOMING" 3 "CROSSING_LEFT2RIGHT" 4 "CROSSING_RIGHT2LEFT" 5 "UNKNOWN" 6 "STOPPED" 7 "RESERVED" ;
VAL_ 862 ARC_OD_MaintenanceState_Obj_0087 0 "INVALID" 1 "NEW" 2 "MEASURED" 3 "PREDICTED" ;
VAL_ 862 ARC_OD_Classification_Obj_27_RL 0 "Unknow" 1 "Person" 2 "Bimo" 3 "Car" 4 "Truck" 5 "Barrier" 6 "Reserved" 7 "Reserved" ;
VAL_ 862 ARC_OD_DynProp_Obj_27_RL 0 "STATIONAR" 1 "MOVIN" 2 "ONCOMING" 3 "STOPPE" 4 "CROSSING_LEFT2RIGH" 5 "CROSSING_RIGHT2LEF" 6 "RESERVE" 7 "RESERVED" ;
VAL_ 862 ARC_OD_MaintenanceState_Obj_0088 0 "INVALID" 1 "NEW" 2 "MEASURED" 3 "PREDICTED" ;
VAL_ 863 ARC_OD_Classification_Obj_28_RL 0 "Unknow" 1 "Person" 2 "Bimo" 3 "Car" 4 "Truck" 5 "Barrier" 6 "Reserved" 7 "Reserved" ;
VAL_ 863 ARC_OD_DynProp_Obj_28_RL 0 "MOVING" 1 "STATIONARY" 2 "ONCOMING" 3 "CROSSING_LEFT2RIGHT" 4 "CROSSING_RIGHT2LEFT" 5 "UNKNOWN" 6 "STOPPED" 7 "RESERVED" ;
VAL_ 863 ARC_OD_MaintenanceState_Obj_0089 0 "INVALID" 1 "NEW" 2 "MEASURED" 3 "PREDICTED" ;
VAL_ 863 ARC_OD_Classification_Obj_29_RL 0 "Unknow" 1 "Person" 2 "Bimo" 3 "Car" 4 "Truck" 5 "Barrier" 6 "Reserved" 7 "Reserved" ;
VAL_ 863 ARC_OD_DynProp_Obj_29_RL 0 "STATIONAR" 1 "MOVIN" 2 "ONCOMING" 3 "STOPPE" 4 "CROSSING_LEFT2RIGH" 5 "CROSSING_RIGHT2LEF" 6 "RESERVE" 7 "RESERVED" ;
VAL_ 863 ARC_OD_MaintenanceState_Obj_0090 0 "INVALID" 1 "NEW" 2 "MEASURED" 3 "PREDICTED" ;
VAL_ 864 ARC_OD_Classification_Obj_30_RL 0 "Unknow" 1 "Person" 2 "Bimo" 3 "Car" 4 "Truck" 5 "Barrier" 6 "Reserved" 7 "Reserved" ;
VAL_ 864 ARC_OD_DynProp_Obj_30_RL 0 "MOVING" 1 "STATIONARY" 2 "ONCOMING" 3 "CROSSING_LEFT2RIGHT" 4 "CROSSING_RIGHT2LEFT" 5 "UNKNOWN" 6 "STOPPED" 7 "RESERVED" ;
VAL_ 864 ARC_OD_MaintenanceState_Obj_0091 0 "INVALID" 1 "NEW" 2 "MEASURED" 3 "PREDICTED" ;
VAL_ 864 ARC_OD_Classification_Obj_31_RL 0 "Unknow" 1 "Person" 2 "Bimo" 3 "Car" 4 "Truck" 5 "Barrier" 6 "Reserved" 7 "Reserved" ;
VAL_ 864 ARC_OD_DynProp_Obj_31_RL 0 "STATIONAR" 1 "MOVIN" 2 "ONCOMING" 3 "STOPPE" 4 "CROSSING_LEFT2RIGH" 5 "CROSSING_RIGHT2LEF" 6 "RESERVE" 7 "RESERVED" ;
VAL_ 864 ARC_OD_MaintenanceState_Obj_0092 0 "INVALID" 1 "NEW" 2 "MEASURED" 3 "PREDICTED" ;
VAL_ 865 ARC_OD_Classification_Obj_32_RL 0 "Unknow" 1 "Person" 2 "Bimo" 3 "Car" 4 "Truck" 5 "Barrier" 6 "Reserved" 7 "Reserved" ;
VAL_ 865 ARC_OD_DynProp_Obj_32_RL 0 "MOVING" 1 "STATIONARY" 2 "ONCOMING" 3 "CROSSING_LEFT2RIGHT" 4 "CROSSING_RIGHT2LEFT" 5 "UNKNOWN" 6 "STOPPED" 7 "RESERVED" ;
VAL_ 865 ARC_OD_MaintenanceState_Obj_0093 0 "INVALID" 1 "NEW" 2 "MEASURED" 3 "PREDICTED" ;
VAL_ 865 ARC_OD_Classification_Obj_33_RL 0 "Unknow" 1 "Person" 2 "Bimo" 3 "Car" 4 "Truck" 5 "Barrier" 6 "Reserved" 7 "Reserved" ;
VAL_ 865 ARC_OD_DynProp_Obj_33_RL 0 "STATIONAR" 1 "MOVIN" 2 "ONCOMING" 3 "STOPPE" 4 "CROSSING_LEFT2RIGH" 5 "CROSSING_RIGHT2LEF" 6 "RESERVE" 7 "RESERVED" ;
VAL_ 865 ARC_OD_MaintenanceState_Obj_0094 0 "INVALID" 1 "NEW" 2 "MEASURED" 3 "PREDICTED" ;
VAL_ 866 ARC_OD_Classification_Obj_34_RL 0 "Unknow" 1 "Person" 2 "Bimo" 3 "Car" 4 "Truck" 5 "Barrier" 6 "Reserved" 7 "Reserved" ;
VAL_ 866 ARC_OD_DynProp_Obj_34_RL 0 "MOVING" 1 "STATIONARY" 2 "ONCOMING" 3 "CROSSING_LEFT2RIGHT" 4 "CROSSING_RIGHT2LEFT" 5 "UNKNOWN" 6 "STOPPED" 7 "RESERVED" ;
VAL_ 866 ARC_OD_MaintenanceState_Obj_0095 0 "INVALID" 1 "NEW" 2 "MEASURED" 3 "PREDICTED" ;
VAL_ 866 ARC_OD_Classification_Obj_35_RL 0 "Unknow" 1 "Person" 2 "Bimo" 3 "Car" 4 "Truck" 5 "Barrier" 6 "Reserved" 7 "Reserved" ;
VAL_ 866 ARC_OD_DynProp_Obj_35_RL 0 "STATIONAR" 1 "MOVIN" 2 "ONCOMING" 3 "STOPPE" 4 "CROSSING_LEFT2RIGH" 5 "CROSSING_RIGHT2LEF" 6 "RESERVE" 7 "RESERVED" ;
VAL_ 866 ARC_OD_MaintenanceState_Obj_0096 0 "INVALID" 1 "NEW" 2 "MEASURED" 3 "PREDICTED" ;
VAL_ 867 ARC_OD_Classification_Obj_36_RL 0 "Unknow" 1 "Person" 2 "Bimo" 3 "Car" 4 "Truck" 5 "Barrier" 6 "Reserved" 7 "Reserved" ;
VAL_ 867 ARC_OD_DynProp_Obj_36_RL 0 "MOVING" 1 "STATIONARY" 2 "ONCOMING" 3 "CROSSING_LEFT2RIGHT" 4 "CROSSING_RIGHT2LEFT" 5 "UNKNOWN" 6 "STOPPED" 7 "RESERVED" ;
VAL_ 867 ARC_OD_MaintenanceState_Obj_0097 0 "INVALID" 1 "NEW" 2 "MEASURED" 3 "PREDICTED" ;
VAL_ 867 ARC_OD_Classification_Obj_37_RL 0 "Unknow" 1 "Person" 2 "Bimo" 3 "Car" 4 "Truck" 5 "Barrier" 6 "Reserved" 7 "Reserved" ;
VAL_ 867 ARC_OD_DynProp_Obj_37_RL 0 "STATIONAR" 1 "MOVIN" 2 "ONCOMING" 3 "STOPPE" 4 "CROSSING_LEFT2RIGH" 5 "CROSSING_RIGHT2LEF" 6 "RESERVE" 7 "RESERVED" ;
VAL_ 867 ARC_OD_MaintenanceState_Obj_0098 0 "INVALID" 1 "NEW" 2 "MEASURED" 3 "PREDICTED" ;
VAL_ 868 ARC_OD_Classification_Obj_38_RL 0 "Unknow" 1 "Person" 2 "Bimo" 3 "Car" 4 "Truck" 5 "Barrier" 6 "Reserved" 7 "Reserved" ;
VAL_ 868 ARC_OD_DynProp_Obj_38_RL 0 "MOVING" 1 "STATIONARY" 2 "ONCOMING" 3 "CROSSING_LEFT2RIGHT" 4 "CROSSING_RIGHT2LEFT" 5 "UNKNOWN" 6 "STOPPED" 7 "RESERVED" ;
VAL_ 868 ARC_OD_MaintenanceState_Obj_0099 0 "INVALID" 1 "NEW" 2 "MEASURED" 3 "PREDICTED" ;
VAL_ 868 ARC_OD_Classification_Obj_39_RL 0 "Unknow" 1 "Person" 2 "Bimo" 3 "Car" 4 "Truck" 5 "Barrier" 6 "Reserved" 7 "Reserved" ;
VAL_ 868 ARC_OD_DynProp_Obj_39_RL 0 "STATIONAR" 1 "MOVIN" 2 "ONCOMING" 3 "STOPPE" 4 "CROSSING_LEFT2RIGH" 5 "CROSSING_RIGHT2LEF" 6 "RESERVE" 7 "RESERVED" ;
VAL_ 868 ARC_OD_MaintenanceState_Obj_0100 0 "INVALID" 1 "NEW" 2 "MEASURED" 3 "PREDICTED" ;
VAL_ 869 ARC_OD_Classification_Obj_40_RL 0 "Unknow" 1 "Person" 2 "Bimo" 3 "Car" 4 "Truck" 5 "Barrier" 6 "Reserved" 7 "Reserved" ;
VAL_ 869 ARC_OD_DynProp_Obj_40_RL 0 "MOVING" 1 "STATIONARY" 2 "ONCOMING" 3 "CROSSING_LEFT2RIGHT" 4 "CROSSING_RIGHT2LEFT" 5 "UNKNOWN" 6 "STOPPED" 7 "RESERVED" ;
VAL_ 869 ARC_OD_MaintenanceState_Obj_0101 0 "INVALID" 1 "NEW" 2 "MEASURED" 3 "PREDICTED" ;
VAL_ 869 ARC_OD_Classification_Obj_41_RL 0 "Unknow" 1 "Person" 2 "Bimo" 3 "Car" 4 "Truck" 5 "Barrier" 6 "Reserved" 7 "Reserved" ;
VAL_ 869 ARC_OD_DynProp_Obj_41_RL 0 "STATIONAR" 1 "MOVIN" 2 "ONCOMING" 3 "STOPPE" 4 "CROSSING_LEFT2RIGH" 5 "CROSSING_RIGHT2LEF" 6 "RESERVE" 7 "RESERVED" ;
VAL_ 869 ARC_OD_MaintenanceState_Obj_0102 0 "INVALID" 1 "NEW" 2 "MEASURED" 3 "PREDICTED" ;
VAL_ 870 ARC_OD_Classification_Obj_42_RL 0 "POINT" 1 "CAR" 2 "TRUCK" 3 "PEDESTRIAN" 4 "MOTORCYCLE" 5 "BICYCLE" 6 "WIDE" 7 "UNCLASSIFIED" ;
VAL_ 870 ARC_OD_DynProp_Obj_42_RL 0 "MOVING" 1 "STATIONARY" 2 "ONCOMING" 3 "CROSSING_LEFT2RIGHT" 4 "CROSSING_RIGHT2LEFT" 5 "UNKNOWN" 6 "STOPPED" 7 "RESERVED" ;
VAL_ 870 ARC_OD_MaintenanceState_Obj_0103 0 "INVALID" 1 "NEW" 2 "MEASURED" 3 "PREDICTED" ;
VAL_ 870 ARC_OD_Classification_Obj_43_RL 0 "POINT" 1 "CAR" 2 "TRUCK" 3 "PEDESTRIAN" 4 "MOTORCYCLE" 5 "BICYCLE" 6 "WIDE" 7 "UNCLASSIFIED" ;
VAL_ 870 ARC_OD_DynProp_Obj_43_RL 0 "STATIONAR" 1 "MOVIN" 2 "ONCOMING" 3 "STOPPE" 4 "CROSSING_LEFT2RIGH" 5 "CROSSING_RIGHT2LEF" 6 "RESERVE" 7 "RESERVED" ;
VAL_ 870 ARC_OD_MaintenanceState_Obj_0104 0 "INVALID" 1 "NEW" 2 "MEASURED" 3 "PREDICTED" ;
VAL_ 871 ARC_OD_Classification_Obj_44_RL 0 "POINT" 1 "CAR" 2 "TRUCK" 3 "PEDESTRIAN" 4 "MOTORCYCLE" 5 "BICYCLE" 6 "WIDE" 7 "UNCLASSIFIED" ;
VAL_ 871 ARC_OD_DynProp_Obj_44_RL 0 "MOVING" 1 "STATIONARY" 2 "ONCOMING" 3 "CROSSING_LEFT2RIGHT" 4 "CROSSING_RIGHT2LEFT" 5 "UNKNOWN" 6 "STOPPED" 7 "RESERVED" ;
VAL_ 871 ARC_OD_MaintenanceState_Obj_0105 0 "INVALID" 1 "NEW" 2 "MEASURED" 3 "PREDICTED" ;
VAL_ 871 ARC_OD_Classification_Obj_45_RL 0 "POINT" 1 "CAR" 2 "TRUCK" 3 "PEDESTRIAN" 4 "MOTORCYCLE" 5 "BICYCLE" 6 "WIDE" 7 "UNCLASSIFIED" ;
VAL_ 871 ARC_OD_DynProp_Obj_45_RL 0 "STATIONAR" 1 "MOVIN" 2 "ONCOMING" 3 "STOPPE" 4 "CROSSING_LEFT2RIGH" 5 "CROSSING_RIGHT2LEF" 6 "RESERVE" 7 "RESERVED" ;
VAL_ 871 ARC_OD_MaintenanceState_Obj_0106 0 "INVALID" 1 "NEW" 2 "MEASURED" 3 "PREDICTED" ;
VAL_ 872 ARC_OD_Classification_Obj_46_RL 0 "POINT" 1 "CAR" 2 "TRUCK" 3 "PEDESTRIAN" 4 "MOTORCYCLE" 5 "BICYCLE" 6 "WIDE" 7 "UNCLASSIFIED" ;
VAL_ 872 ARC_OD_DynProp_Obj_46_RL 0 "MOVING" 1 "STATIONARY" 2 "ONCOMING" 3 "CROSSING_LEFT2RIGHT" 4 "CROSSING_RIGHT2LEFT" 5 "UNKNOWN" 6 "STOPPED" 7 "RESERVED" ;
VAL_ 872 ARC_OD_MaintenanceState_Obj_0107 0 "INVALID" 1 "NEW" 2 "MEASURED" 3 "PREDICTED" ;
VAL_ 872 ARC_OD_Classification_Obj_47_RL 0 "POINT" 1 "CAR" 2 "TRUCK" 3 "PEDESTRIAN" 4 "MOTORCYCLE" 5 "BICYCLE" 6 "WIDE" 7 "UNCLASSIFIED" ;
VAL_ 872 ARC_OD_DynProp_Obj_47_RL 0 "STATIONAR" 1 "MOVIN" 2 "ONCOMING" 3 "STOPPE" 4 "CROSSING_LEFT2RIGH" 5 "CROSSING_RIGHT2LEF" 6 "RESERVE" 7 "RESERVED" ;
VAL_ 872 ARC_OD_MaintenanceState_Obj_0108 0 "INVALID" 1 "NEW" 2 "MEASURED" 3 "PREDICTED" ;
VAL_ 873 ARC_OD_Classification_Obj_48_RL 0 "POINT" 1 "CAR" 2 "TRUCK" 3 "PEDESTRIAN" 4 "MOTORCYCLE" 5 "BICYCLE" 6 "WIDE" 7 "UNCLASSIFIED" ;
VAL_ 873 ARC_OD_DynProp_Obj_48_RL 0 "MOVING" 1 "STATIONARY" 2 "ONCOMING" 3 "CROSSING_LEFT2RIGHT" 4 "CROSSING_RIGHT2LEFT" 5 "UNKNOWN" 6 "STOPPED" 7 "RESERVED" ;
VAL_ 873 ARC_OD_MaintenanceState_Obj_0109 0 "INVALID" 1 "NEW" 2 "MEASURED" 3 "PREDICTED" ;
VAL_ 873 ARC_OD_Classification_Obj_49_RL 0 "POINT" 1 "CAR" 2 "TRUCK" 3 "PEDESTRIAN" 4 "MOTORCYCLE" 5 "BICYCLE" 6 "WIDE" 7 "UNCLASSIFIED" ;
VAL_ 873 ARC_OD_DynProp_Obj_49_RL 0 "STATIONAR" 1 "MOVIN" 2 "ONCOMING" 3 "STOPPE" 4 "CROSSING_LEFT2RIGH" 5 "CROSSING_RIGHT2LEF" 6 "RESERVE" 7 "RESERVED" ;
VAL_ 873 ARC_OD_MaintenanceState_Obj_0110 0 "INVALID" 1 "NEW" 2 "MEASURED" 3 "PREDICTED" ;
VAL_ 874 ARC_OD_Classification_Obj_50_RL 0 "POINT" 1 "CAR" 2 "TRUCK" 3 "PEDESTRIAN" 4 "MOTORCYCLE" 5 "BICYCLE" 6 "WIDE" 7 "UNCLASSIFIED" ;
VAL_ 874 ARC_OD_DynProp_Obj_50_RL 0 "MOVING" 1 "STATIONARY" 2 "ONCOMING" 3 "CROSSING_LEFT2RIGHT" 4 "CROSSING_RIGHT2LEFT" 5 "UNKNOWN" 6 "STOPPED" 7 "RESERVED" ;
VAL_ 874 ARC_OD_MaintenanceState_Obj_0111 0 "INVALID" 1 "NEW" 2 "MEASURED" 3 "PREDICTED" ;
VAL_ 874 ARC_OD_Classification_Obj_51_RL 0 "POINT" 1 "CAR" 2 "TRUCK" 3 "PEDESTRIAN" 4 "MOTORCYCLE" 5 "BICYCLE" 6 "WIDE" 7 "UNCLASSIFIED" ;
VAL_ 874 ARC_OD_DynProp_Obj_51_RL 0 "STATIONAR" 1 "MOVIN" 2 "ONCOMING" 3 "STOPPE" 4 "CROSSING_LEFT2RIGH" 5 "CROSSING_RIGHT2LEF" 6 "RESERVE" 7 "RESERVED" ;
VAL_ 874 ARC_OD_MaintenanceState_Obj_0112 0 "INVALID" 1 "NEW" 2 "MEASURED" 3 "PREDICTED" ;
VAL_ 875 ARC_OD_Classification_Obj_52_RL 0 "POINT" 1 "CAR" 2 "TRUCK" 3 "PEDESTRIAN" 4 "MOTORCYCLE" 5 "BICYCLE" 6 "WIDE" 7 "UNCLASSIFIED" ;
VAL_ 875 ARC_OD_DynProp_Obj_52_RL 0 "MOVING" 1 "STATIONARY" 2 "ONCOMING" 3 "CROSSING_LEFT2RIGHT" 4 "CROSSING_RIGHT2LEFT" 5 "UNKNOWN" 6 "STOPPED" 7 "RESERVED" ;
VAL_ 875 ARC_OD_MaintenanceState_Obj_0113 0 "INVALID" 1 "NEW" 2 "MEASURED" 3 "PREDICTED" ;
VAL_ 875 ARC_OD_Classification_Obj_53_RL 0 "POINT" 1 "CAR" 2 "TRUCK" 3 "PEDESTRIAN" 4 "MOTORCYCLE" 5 "BICYCLE" 6 "WIDE" 7 "UNCLASSIFIED" ;
VAL_ 875 ARC_OD_DynProp_Obj_53_RL 0 "STATIONAR" 1 "MOVIN" 2 "ONCOMING" 3 "STOPPE" 4 "CROSSING_LEFT2RIGH" 5 "CROSSING_RIGHT2LEF" 6 "RESERVE" 7 "RESERVED" ;
VAL_ 875 ARC_OD_MaintenanceState_Obj_0114 0 "INVALID" 1 "NEW" 2 "MEASURED" 3 "PREDICTED" ;
VAL_ 876 ARC_OD_Classification_Obj_54_RL 0 "POINT" 1 "CAR" 2 "TRUCK" 3 "PEDESTRIAN" 4 "MOTORCYCLE" 5 "BICYCLE" 6 "WIDE" 7 "UNCLASSIFIED" ;
VAL_ 876 ARC_OD_DynProp_Obj_54_RL 0 "MOVING" 1 "STATIONARY" 2 "ONCOMING" 3 "CROSSING_LEFT2RIGHT" 4 "CROSSING_RIGHT2LEFT" 5 "UNKNOWN" 6 "STOPPED" 7 "RESERVED" ;
VAL_ 876 ARC_OD_MaintenanceState_Obj_0115 0 "INVALID" 1 "NEW" 2 "MEASURED" 3 "PREDICTED" ;
VAL_ 876 ARC_OD_Classification_Obj_55_RL 0 "POINT" 1 "CAR" 2 "TRUCK" 3 "PEDESTRIAN" 4 "MOTORCYCLE" 5 "BICYCLE" 6 "WIDE" 7 "UNCLASSIFIED" ;
VAL_ 876 ARC_OD_DynProp_Obj_55_RL 0 "STATIONAR" 1 "MOVIN" 2 "ONCOMING" 3 "STOPPE" 4 "CROSSING_LEFT2RIGH" 5 "CROSSING_RIGHT2LEF" 6 "RESERVE" 7 "RESERVED" ;
VAL_ 876 ARC_OD_MaintenanceState_Obj_0116 0 "INVALID" 1 "NEW" 2 "MEASURED" 3 "PREDICTED" ;
VAL_ 877 ARC_OD_Classification_Obj_56_RL 0 "POINT" 1 "CAR" 2 "TRUCK" 3 "PEDESTRIAN" 4 "MOTORCYCLE" 5 "BICYCLE" 6 "WIDE" 7 "UNCLASSIFIED" ;
VAL_ 877 ARC_OD_DynProp_Obj_56_RL 0 "MOVING" 1 "STATIONARY" 2 "ONCOMING" 3 "CROSSING_LEFT2RIGHT" 4 "CROSSING_RIGHT2LEFT" 5 "UNKNOWN" 6 "STOPPED" 7 "RESERVED" ;
VAL_ 877 ARC_OD_MaintenanceState_Obj_0117 0 "INVALID" 1 "NEW" 2 "MEASURED" 3 "PREDICTED" ;
VAL_ 877 ARC_OD_Classification_Obj_57_RL 0 "POINT" 1 "CAR" 2 "TRUCK" 3 "PEDESTRIAN" 4 "MOTORCYCLE" 5 "BICYCLE" 6 "WIDE" 7 "UNCLASSIFIED" ;
VAL_ 877 ARC_OD_DynProp_Obj_57_RL 0 "STATIONAR" 1 "MOVIN" 2 "ONCOMING" 3 "STOPPE" 4 "CROSSING_LEFT2RIGH" 5 "CROSSING_RIGHT2LEF" 6 "RESERVE" 7 "RESERVED" ;
VAL_ 877 ARC_OD_MaintenanceState_Obj_0118 0 "INVALID" 1 "NEW" 2 "MEASURED" 3 "PREDICTED" ;
VAL_ 878 ARC_OD_Classification_Obj_58_RL 0 "POINT" 1 "CAR" 2 "TRUCK" 3 "PEDESTRIAN" 4 "MOTORCYCLE" 5 "BICYCLE" 6 "WIDE" 7 "UNCLASSIFIED" ;
VAL_ 878 ARC_OD_DynProp_Obj_58_RL 0 "MOVING" 1 "STATIONARY" 2 "ONCOMING" 3 "CROSSING_LEFT2RIGHT" 4 "CROSSING_RIGHT2LEFT" 5 "UNKNOWN" 6 "STOPPED" 7 "RESERVED" ;
VAL_ 878 ARC_OD_MaintenanceState_Obj_0119 0 "INVALID" 1 "NEW" 2 "MEASURED" 3 "PREDICTED" ;
VAL_ 878 ARC_OD_Classification_Obj_59_RL 0 "POINT" 1 "CAR" 2 "TRUCK" 3 "PEDESTRIAN" 4 "MOTORCYCLE" 5 "BICYCLE" 6 "WIDE" 7 "UNCLASSIFIED" ;
VAL_ 878 ARC_OD_DynProp_Obj_59_RL 0 "STATIONAR" 1 "MOVIN" 2 "ONCOMING" 3 "STOPPE" 4 "CROSSING_LEFT2RIGH" 5 "CROSSING_RIGHT2LEF" 6 "RESERVE" 7 "RESERVED" ;
VAL_ 878 ARC_OD_MaintenanceState_Obj_0120 0 "INVALID" 1 "NEW" 2 "MEASURED" 3 "PREDICTED" ;
VAL_ 266 ESC_RLWhlSpdV 0 "Valid " 1 "Invalid" ;
VAL_ 277 EPS_StrgWhlAnglSenCalSts 0 "unknow" 1 "Estimated" 2 "Calibrated" 3 "unknow" ;
VAL_ 805 ESC_VehSpdV 0 "Valid" 1 "Invalid " ;
VAL_ 805 ESC_VDCCtrlActv 0 "VDCInactive " 1 "VDCActive " ;
VAL_ 834 ICM_VehSpdDispV 0 "Invalid" 1 "Valid" ;
VAL_ 834 ICM_TotOdoV 0 "Invalid" 1 "Valid" ;
VAL_ 267 ESC_EBDActv 0 "Notactive" 1 "Active" ;
VAL_ 267 ESC_TCSActv 0 "Inactive" 1 "Active" ;
VAL_ 267 ESC_ABSActv 0 "Not active" 1 "Active" ;
VAL_ 267 ESC_ESCFld 0 "ESC Normal" 1 "ESC Failed" ;
VAL_ 267 ESC_CDPActv 0 "Not Active" 1 "Active" ;
VAL_ 267 ESC_HDCSts 0 "OFF" 1 "On not active braking" 2 "On active braking" 3 "Reserved" ;
VAL_ 267 ESC_Off 0 "Off" 1 "On" ;
VAL_ 267 ESC_ABAAvlbl 0 "Not available" 1 "Available" ;
VAL_ 267 ESC_ABAActv 0 "Not active" 1 "Active" ;
VAL_ 269 ESC_VehStdslSts 0 "Not Standstill" 1 "Standstill" ;
VAL_ 269 ESC_VehStdslStsV 0 "Invalid" 1 "Valid" ;
VAL_ 181 EHB_BrkPedlAppld 1 "brake pedal applied" 0 "brake pedal not applied" ;
VAL_ 181 EHB_BrkPedlAppldSts 3 "Reserved" 2 "Fault" 1 "Normal" 0 "Init" ;
VAL_ 181 EHB_CtrlrFltSts 1 "Fault" 0 "Normal" ;
SIG_GROUP_ 860 Signal_Group_ARC_OD_22_23 1 : DistHeight_Obj_23_RL DistHeight_Obj_22_RL ARC_OD_DistX_Obj_22_RL ARC_OD_Classification_Obj_22_RL ARC_OD_AabsYStd_Obj_22_RL ARC_OD_ClassConf_Obj_22_RL ARC_OD_ProbOfExist_Obj_22_RL ARC_OD_VabsX_Obj_22_RL ARC_OD_DynProp_Obj_22_RL ARC_OD_Length_Obj_22_RL ARC_OD_MaintenanceState_Obj_0083 ARC_OD_Width_Obj_22_RL ARC_OD_RCS_Obj_22_RL ARC_OD_Orientation_Obj_22_RL ARC_OD_LifeCycle_Obj_22_RL ARC_OD_DistX_Obj_23_RL ARC_OD_VabsX_Obj_23_RL ARC_OD_AabsX_Obj_23_RL ARC_OD_AabsX_Obj_22_RL ARC_OD_DistY_Obj_23_RL ARC_OD_VabsY_Obj_23_RL ARC_OD_AabsY_Obj_23_RL ARC_OD_DistXStd_Obj_23_RL ARC_OD_DistYStd_Obj_23_RL ARC_OD_VabsXStd_Obj_23_RL ARC_OD_VabsYStd_Obj_23_RL ARC_OD_AabsXStd_Obj_23_RL ARC_OD_Classification_Obj_23_RL ARC_OD_AabsYStd_Obj_23_RL ARC_OD_ClassConf_Obj_23_RL ARC_OD_DistY_Obj_22_RL ARC_OD_ProbOfExist_Obj_23_RL ARC_OD_DynProp_Obj_23_RL ARC_OD_Length_Obj_23_RL ARC_OD_MaintenanceState_Obj_0084 ARC_OD_Width_Obj_23_RL ARC_OD_RCS_Obj_23_RL ARC_OD_Orientation_Obj_23_RL ARC_OD_LifeCycle_Obj_23_RL ARC_OD_ObstacleProb_Obj_22_RL ARC_OD_ObstacleProb_Obj_23_RL ARC_OD_VabsY_Obj_22_RL ARC_OD_ID_22_RL ARC_OD_ID_23_RL ARC_OD_MsgCounter_Obj_22_23_RL ARC_OD_CRC8_Obj_22_23_RL ARC_OD_AabsY_Obj_22_RL ARC_OD_DistXStd_Obj_22_RL ARC_OD_DistYStd_Obj_22_RL ARC_OD_VabsXStd_Obj_22_RL ARC_OD_VabsYStd_Obj_22_RL ARC_OD_AabsXStd_Obj_22_RL;
SIG_GROUP_ 861 Signal_Group_ARC_OD_24_25 1 : DistHeight_Obj_25_RL DistHeight_Obj_24_RL ARC_OD_DistX_Obj_24_RL ARC_OD_Classification_Obj_24_RL ARC_OD_AabsYStd_Obj_24_RL ARC_OD_ClassConf_Obj_24_RL ARC_OD_ProbOfExist_Obj_24_RL ARC_OD_VabsX_Obj_24_RL ARC_OD_DynProp_Obj_24_RL ARC_OD_Length_Obj_24_RL ARC_OD_MaintenanceState_Obj_0085 ARC_OD_Width_Obj_24_RL ARC_OD_RCS_Obj_24_RL ARC_OD_Orientation_Obj_24_RL ARC_OD_LifeCycle_Obj_24_RL ARC_OD_DistX_Obj_25_RL ARC_OD_VabsX_Obj_25_RL ARC_OD_AabsX_Obj_25_RL ARC_OD_AabsX_Obj_24_RL ARC_OD_DistY_Obj_25_RL ARC_OD_VabsY_Obj_25_RL ARC_OD_AabsY_Obj_25_RL ARC_OD_DistXStd_Obj_25_RL ARC_OD_DistYStd_Obj_25_RL ARC_OD_VabsXStd_Obj_25_RL ARC_OD_VabsYStd_Obj_25_RL ARC_OD_AabsXStd_Obj_25_RL ARC_OD_Classification_Obj_25_RL ARC_OD_AabsYStd_Obj_25_RL ARC_OD_ClassConf_Obj_25_RL ARC_OD_DistY_Obj_24_RL ARC_OD_ProbOfExist_Obj_25_RL ARC_OD_DynProp_Obj_25_RL ARC_OD_Length_Obj_25_RL ARC_OD_MaintenanceState_Obj_0086 ARC_OD_Width_Obj_25_RL ARC_OD_RCS_Obj_25_RL ARC_OD_Orientation_Obj_25_RL ARC_OD_LifeCycle_Obj_25_RL ARC_OD_ObstacleProb_Obj_24_RL ARC_OD_ObstacleProb_Obj_25_RL ARC_OD_VabsY_Obj_24_RL ARC_OD_ID_24_RL ARC_OD_ID_25_RL ARC_OD_MsgCounter_Obj_24_25_RL ARC_OD_CRC8_Obj_24_25_RL ARC_OD_AabsY_Obj_24_RL ARC_OD_DistXStd_Obj_24_RL ARC_OD_DistYStd_Obj_24_RL ARC_OD_VabsXStd_Obj_24_RL ARC_OD_VabsYStd_Obj_24_RL ARC_OD_AabsXStd_Obj_24_RL;
SIG_GROUP_ 862 Signal_Group_ARC_OD_26_27 1 : DistHeight_Obj_27_RL DistHeight_Obj_26_RL ARC_OD_DistX_Obj_26_RL ARC_OD_Classification_Obj_26_RL ARC_OD_AabsYStd_Obj_26_RL ARC_OD_ClassConf_Obj_26_RL ARC_OD_ProbOfExist_Obj_26_RL ARC_OD_VabsX_Obj_26_RL ARC_OD_DynProp_Obj_26_RL ARC_OD_Length_Obj_26_RL ARC_OD_MaintenanceState_Obj_0087 ARC_OD_Width_Obj_26_RL ARC_OD_RCS_Obj_26_RL ARC_OD_Orientation_Obj_26_RL ARC_OD_LifeCycle_Obj_26_RL ARC_OD_DistX_Obj_27_RL ARC_OD_VabsX_Obj_27_RL ARC_OD_AabsX_Obj_27_RL ARC_OD_AabsX_Obj_26_RL ARC_OD_DistY_Obj_27_RL ARC_OD_VabsY_Obj_27_RL ARC_OD_AabsY_Obj_27_RL ARC_OD_DistXStd_Obj_27_RL ARC_OD_DistYStd_Obj_27_RL ARC_OD_VabsXStd_Obj_27_RL ARC_OD_VabsYStd_Obj_27_RL ARC_OD_AabsXStd_Obj_27_RL ARC_OD_Classification_Obj_27_RL ARC_OD_AabsYStd_Obj_27_RL ARC_OD_ClassConf_Obj_27_RL ARC_OD_DistY_Obj_26_RL ARC_OD_ProbOfExist_Obj_27_RL ARC_OD_DynProp_Obj_27_RL ARC_OD_Length_Obj_27_RL ARC_OD_MaintenanceState_Obj_0088 ARC_OD_Width_Obj_27_RL ARC_OD_RCS_Obj_27_RL ARC_OD_Orientation_Obj_27_RL ARC_OD_LifeCycle_Obj_27_RL ARC_OD_ObstacleProb_Obj_26_RL ARC_OD_ObstacleProb_Obj_27_RL ARC_OD_VabsY_Obj_26_RL ARC_OD_ID_26_RL ARC_OD_ID_27_RL ARC_OD_MsgCounter_Obj_26_27_RL ARC_OD_CRC8_Obj_26_27_RL ARC_OD_AabsY_Obj_26_RL ARC_OD_DistXStd_Obj_26_RL ARC_OD_DistYStd_Obj_26_RL ARC_OD_VabsXStd_Obj_26_RL ARC_OD_VabsYStd_Obj_26_RL ARC_OD_AabsXStd_Obj_26_RL;
SIG_GROUP_ 863 Signal_Group_ARC_OD_28_29 1 : DistHeight_Obj_29_RL DistHeight_Obj_28_RL ARC_OD_DistX_Obj_28_RL ARC_OD_Classification_Obj_28_RL ARC_OD_AabsYStd_Obj_28_RL ARC_OD_ClassConf_Obj_28_RL ARC_OD_ProbOfExist_Obj_28_RL ARC_OD_VabsX_Obj_28_RL ARC_OD_DynProp_Obj_28_RL ARC_OD_Length_Obj_28_RL ARC_OD_MaintenanceState_Obj_0089 ARC_OD_Width_Obj_28_RL ARC_OD_RCS_Obj_28_RL ARC_OD_Orientation_Obj_28_RL ARC_OD_LifeCycle_Obj_28_RL ARC_OD_DistX_Obj_29_RL ARC_OD_VabsX_Obj_29_RL ARC_OD_AabsX_Obj_29_RL ARC_OD_AabsX_Obj_28_RL ARC_OD_DistY_Obj_29_RL ARC_OD_VabsY_Obj_29_RL ARC_OD_AabsY_Obj_29_RL ARC_OD_DistXStd_Obj_29_RL ARC_OD_DistYStd_Obj_29_RL ARC_OD_VabsXStd_Obj_29_RL ARC_OD_VabsYStd_Obj_29_RL ARC_OD_AabsXStd_Obj_29_RL ARC_OD_Classification_Obj_29_RL ARC_OD_AabsYStd_Obj_29_RL ARC_OD_ClassConf_Obj_29_RL ARC_OD_DistY_Obj_28_RL ARC_OD_ProbOfExist_Obj_29_RL ARC_OD_DynProp_Obj_29_RL ARC_OD_Length_Obj_29_RL ARC_OD_MaintenanceState_Obj_0090 ARC_OD_Width_Obj_29_RL ARC_OD_RCS_Obj_29_RL ARC_OD_Orientation_Obj_29_RL ARC_OD_LifeCycle_Obj_29_RL ARC_OD_ObstacleProb_Obj_28_RL ARC_OD_ObstacleProb_Obj_29_RL ARC_OD_VabsY_Obj_28_RL ARC_OD_ID_28_RL ARC_OD_ID_29_RL ARC_OD_MsgCounter_Obj_28_29_RL ARC_OD_CRC8_Obj_28_29_RL ARC_OD_AabsY_Obj_28_RL ARC_OD_DistXStd_Obj_28_RL ARC_OD_DistYStd_Obj_28_RL ARC_OD_VabsXStd_Obj_28_RL ARC_OD_VabsYStd_Obj_28_RL ARC_OD_AabsXStd_Obj_28_RL;
SIG_GROUP_ 864 Signal_Group_ARC_OD_30_31 1 : DistHeight_Obj_31_RL DistHeight_Obj_30_RL ARC_OD_DistX_Obj_30_RL ARC_OD_Classification_Obj_30_RL ARC_OD_AabsYStd_Obj_30_RL ARC_OD_ClassConf_Obj_30_RL ARC_OD_ProbOfExist_Obj_30_RL ARC_OD_VabsX_Obj_30_RL ARC_OD_DynProp_Obj_30_RL ARC_OD_Length_Obj_30_RL ARC_OD_MaintenanceState_Obj_0091 ARC_OD_Width_Obj_30_RL ARC_OD_RCS_Obj_30_RL ARC_OD_Orientation_Obj_30_RL ARC_OD_LifeCycle_Obj_30_RL ARC_OD_DistX_Obj_31_RL ARC_OD_VabsX_Obj_31_RL ARC_OD_AabsX_Obj_31_RL ARC_OD_AabsX_Obj_30_RL ARC_OD_DistY_Obj_31_RL ARC_OD_VabsY_Obj_31_RL ARC_OD_AabsY_Obj_31_RL ARC_OD_DistXStd_Obj_31_RL ARC_OD_DistYStd_Obj_31_RL ARC_OD_VabsXStd_Obj_31_RL ARC_OD_VabsYStd_Obj_31_RL ARC_OD_AabsXStd_Obj_31_RL ARC_OD_Classification_Obj_31_RL ARC_OD_AabsYStd_Obj_31_RL ARC_OD_ClassConf_Obj_31_RL ARC_OD_DistY_Obj_30_RL ARC_OD_ProbOfExist_Obj_31_RL ARC_OD_DynProp_Obj_31_RL ARC_OD_Length_Obj_31_RL ARC_OD_MaintenanceState_Obj_0092 ARC_OD_Width_Obj_31_RL ARC_OD_RCS_Obj_31_RL ARC_OD_Orientation_Obj_31_RL ARC_OD_LifeCycle_Obj_31_RL ARC_OD_ObstacleProb_Obj_30_RL ARC_OD_ObstacleProb_Obj_31_RL ARC_OD_VabsY_Obj_30_RL ARC_OD_ID_30_RL ARC_OD_ID_31_RL ARC_OD_MsgCounter_Obj_30_31_RL ARC_OD_CRC8_Obj_30_31_RL ARC_OD_AabsY_Obj_30_RL ARC_OD_DistXStd_Obj_30_RL ARC_OD_DistYStd_Obj_30_RL ARC_OD_VabsXStd_Obj_30_RL ARC_OD_VabsYStd_Obj_30_RL ARC_OD_AabsXStd_Obj_30_RL;
SIG_GROUP_ 865 Signal_Group_ARC_OD_32_33 1 : DistHeight_Obj_33_RL DistHeight_Obj_32_RL ARC_OD_DistX_Obj_32_RL ARC_OD_Classification_Obj_32_RL ARC_OD_AabsYStd_Obj_32_RL ARC_OD_ClassConf_Obj_32_RL ARC_OD_ProbOfExist_Obj_32_RL ARC_OD_VabsX_Obj_32_RL ARC_OD_DynProp_Obj_32_RL ARC_OD_Length_Obj_32_RL ARC_OD_MaintenanceState_Obj_0093 ARC_OD_Width_Obj_32_RL ARC_OD_RCS_Obj_32_RL ARC_OD_Orientation_Obj_32_RL ARC_OD_LifeCycle_Obj_32_RL ARC_OD_DistX_Obj_33_RL ARC_OD_VabsX_Obj_33_RL ARC_OD_AabsX_Obj_33_RL ARC_OD_AabsX_Obj_32_RL ARC_OD_DistY_Obj_33_RL ARC_OD_VabsY_Obj_33_RL ARC_OD_AabsY_Obj_33_RL ARC_OD_DistXStd_Obj_33_RL ARC_OD_DistYStd_Obj_33_RL ARC_OD_VabsXStd_Obj_33_RL ARC_OD_VabsYStd_Obj_33_RL ARC_OD_AabsXStd_Obj_33_RL ARC_OD_Classification_Obj_33_RL ARC_OD_AabsYStd_Obj_33_RL ARC_OD_ClassConf_Obj_33_RL ARC_OD_DistY_Obj_32_RL ARC_OD_ProbOfExist_Obj_33_RL ARC_OD_DynProp_Obj_33_RL ARC_OD_Length_Obj_33_RL ARC_OD_MaintenanceState_Obj_0094 ARC_OD_Width_Obj_33_RL ARC_OD_RCS_Obj_33_RL ARC_OD_Orientation_Obj_33_RL ARC_OD_LifeCycle_Obj_33_RL ARC_OD_ObstacleProb_Obj_32_RL ARC_OD_ObstacleProb_Obj_33_RL ARC_OD_VabsY_Obj_32_RL ARC_OD_ID_32_RL ARC_OD_ID_33_RL ARC_OD_MsgCounter_Obj_32_33_RL ARC_OD_CRC8_Obj_32_33_RL ARC_OD_AabsY_Obj_32_RL ARC_OD_DistXStd_Obj_32_RL ARC_OD_DistYStd_Obj_32_RL ARC_OD_VabsXStd_Obj_32_RL ARC_OD_VabsYStd_Obj_32_RL ARC_OD_AabsXStd_Obj_32_RL;
SIG_GROUP_ 866 Signal_Group_ARC_OD_34_35 1 : DistHeight_Obj_35_RL DistHeight_Obj_34_RL ARC_OD_DistX_Obj_34_RL ARC_OD_Classification_Obj_34_RL ARC_OD_AabsYStd_Obj_34_RL ARC_OD_ClassConf_Obj_34_RL ARC_OD_ProbOfExist_Obj_34_RL ARC_OD_VabsX_Obj_34_RL ARC_OD_DynProp_Obj_34_RL ARC_OD_Length_Obj_34_RL ARC_OD_MaintenanceState_Obj_0095 ARC_OD_Width_Obj_34_RL ARC_OD_RCS_Obj_34_RL ARC_OD_Orientation_Obj_34_RL ARC_OD_LifeCycle_Obj_34_RL ARC_OD_DistX_Obj_35_RL ARC_OD_VabsX_Obj_35_RL ARC_OD_AabsX_Obj_35_RL ARC_OD_AabsX_Obj_34_RL ARC_OD_DistY_Obj_35_RL ARC_OD_VabsY_Obj_35_RL ARC_OD_AabsY_Obj_35_RL ARC_OD_DistXStd_Obj_35_RL ARC_OD_DistYStd_Obj_35_RL ARC_OD_VabsXStd_Obj_35_RL ARC_OD_VabsYStd_Obj_35_RL ARC_OD_AabsXStd_Obj_35_RL ARC_OD_Classification_Obj_35_RL ARC_OD_AabsYStd_Obj_35_RL ARC_OD_ClassConf_Obj_35_RL ARC_OD_DistY_Obj_34_RL ARC_OD_ProbOfExist_Obj_35_RL ARC_OD_DynProp_Obj_35_RL ARC_OD_Length_Obj_35_RL ARC_OD_MaintenanceState_Obj_0096 ARC_OD_Width_Obj_35_RL ARC_OD_RCS_Obj_35_RL ARC_OD_Orientation_Obj_35_RL ARC_OD_LifeCycle_Obj_35_RL ARC_OD_ObstacleProb_Obj_34_RL ARC_OD_ObstacleProb_Obj_35_RL ARC_OD_VabsY_Obj_34_RL ARC_OD_ID_34_RL ARC_OD_ID_35_RL ARC_OD_MsgCounter_Obj_34_35_RL ARC_OD_CRC8_Obj_34_35_RL ARC_OD_AabsY_Obj_34_RL ARC_OD_DistXStd_Obj_34_RL ARC_OD_DistYStd_Obj_34_RL ARC_OD_VabsXStd_Obj_34_RL ARC_OD_VabsYStd_Obj_34_RL ARC_OD_AabsXStd_Obj_34_RL;
SIG_GROUP_ 867 Signal_Group_ARC_OD_36_37 1 : DistHeight_Obj_37_RL DistHeight_Obj_36_RL ARC_OD_DistX_Obj_36_RL ARC_OD_Classification_Obj_36_RL ARC_OD_AabsYStd_Obj_36_RL ARC_OD_ClassConf_Obj_36_RL ARC_OD_ProbOfExist_Obj_36_RL ARC_OD_VabsX_Obj_36_RL ARC_OD_DynProp_Obj_36_RL ARC_OD_Length_Obj_36_RL ARC_OD_MaintenanceState_Obj_0097 ARC_OD_Width_Obj_36_RL ARC_OD_RCS_Obj_36_RL ARC_OD_Orientation_Obj_36_RL ARC_OD_LifeCycle_Obj_36_RL ARC_OD_DistX_Obj_37_RL ARC_OD_VabsX_Obj_37_RL ARC_OD_AabsX_Obj_37_RL ARC_OD_AabsX_Obj_36_RL ARC_OD_DistY_Obj_37_RL ARC_OD_VabsY_Obj_37_RL ARC_OD_AabsY_Obj_37_RL ARC_OD_DistXStd_Obj_37_RL ARC_OD_DistYStd_Obj_37_RL ARC_OD_VabsXStd_Obj_37_RL ARC_OD_VabsYStd_Obj_37_RL ARC_OD_AabsXStd_Obj_37_RL ARC_OD_Classification_Obj_37_RL ARC_OD_AabsYStd_Obj_37_RL ARC_OD_ClassConf_Obj_37_RL ARC_OD_DistY_Obj_36_RL ARC_OD_ProbOfExist_Obj_37_RL ARC_OD_DynProp_Obj_37_RL ARC_OD_Length_Obj_37_RL ARC_OD_MaintenanceState_Obj_0098 ARC_OD_Width_Obj_37_RL ARC_OD_RCS_Obj_37_RL ARC_OD_Orientation_Obj_37_RL ARC_OD_LifeCycle_Obj_37_RL ARC_OD_ObstacleProb_Obj_36_RL ARC_OD_ObstacleProb_Obj_37_RL ARC_OD_VabsY_Obj_36_RL ARC_OD_ID_36_RL ARC_OD_ID_37_RL ARC_OD_MsgCounter_Obj_36_37_RL ARC_OD_CRC8_Obj_36_37_RL ARC_OD_AabsY_Obj_36_RL ARC_OD_DistXStd_Obj_36_RL ARC_OD_DistYStd_Obj_36_RL ARC_OD_VabsXStd_Obj_36_RL ARC_OD_VabsYStd_Obj_36_RL ARC_OD_AabsXStd_Obj_36_RL;
SIG_GROUP_ 868 Signal_Group_ARC_OD_38_39 1 : DistHeight_Obj_39_RL DistHeight_Obj_38_RL ARC_OD_DistX_Obj_38_RL ARC_OD_Classification_Obj_38_RL ARC_OD_AabsYStd_Obj_38_RL ARC_OD_ClassConf_Obj_38_RL ARC_OD_ProbOfExist_Obj_38_RL ARC_OD_VabsX_Obj_38_RL ARC_OD_DynProp_Obj_38_RL ARC_OD_Length_Obj_38_RL ARC_OD_MaintenanceState_Obj_0099 ARC_OD_Width_Obj_38_RL ARC_OD_RCS_Obj_38_RL ARC_OD_Orientation_Obj_38_RL ARC_OD_LifeCycle_Obj_38_RL ARC_OD_DistX_Obj_39_RL ARC_OD_VabsX_Obj_39_RL ARC_OD_AabsX_Obj_39_RL ARC_OD_AabsX_Obj_38_RL ARC_OD_DistY_Obj_39_RL ARC_OD_VabsY_Obj_39_RL ARC_OD_AabsY_Obj_39_RL ARC_OD_DistXStd_Obj_39_RL ARC_OD_DistYStd_Obj_39_RL ARC_OD_VabsXStd_Obj_39_RL ARC_OD_VabsYStd_Obj_39_RL ARC_OD_AabsXStd_Obj_39_RL ARC_OD_Classification_Obj_39_RL ARC_OD_AabsYStd_Obj_39_RL ARC_OD_ClassConf_Obj_39_RL ARC_OD_DistY_Obj_38_RL ARC_OD_ProbOfExist_Obj_39_RL ARC_OD_DynProp_Obj_39_RL ARC_OD_Length_Obj_39_RL ARC_OD_MaintenanceState_Obj_0100 ARC_OD_Width_Obj_39_RL ARC_OD_RCS_Obj_39_RL ARC_OD_Orientation_Obj_39_RL ARC_OD_LifeCycle_Obj_39_RL ARC_OD_ObstacleProb_Obj_38_RL ARC_OD_ObstacleProb_Obj_39_RL ARC_OD_VabsY_Obj_38_RL ARC_OD_ID_38_RL ARC_OD_ID_39_RL ARC_OD_MsgCounter_Obj_38_39_RL ARC_OD_CRC8_Obj_38_39_RL ARC_OD_AabsY_Obj_38_RL ARC_OD_DistXStd_Obj_38_RL ARC_OD_DistYStd_Obj_38_RL ARC_OD_VabsXStd_Obj_38_RL ARC_OD_VabsYStd_Obj_38_RL ARC_OD_AabsXStd_Obj_38_RL;
SIG_GROUP_ 869 Signal_Group_ARC_OD_40_41 1 : DistHeight_Obj_41_RL DistHeight_Obj_40_RL ARC_OD_DistX_Obj_40_RL ARC_OD_Classification_Obj_40_RL ARC_OD_AabsYStd_Obj_40_RL ARC_OD_ClassConf_Obj_40_RL ARC_OD_ProbOfExist_Obj_40_RL ARC_OD_VabsX_Obj_40_RL ARC_OD_DynProp_Obj_40_RL ARC_OD_Length_Obj_40_RL ARC_OD_MaintenanceState_Obj_0101 ARC_OD_Width_Obj_40_RL ARC_OD_RCS_Obj_40_RL ARC_OD_Orientation_Obj_40_RL ARC_OD_LifeCycle_Obj_40_RL ARC_OD_DistX_Obj_41_RL ARC_OD_VabsX_Obj_41_RL ARC_OD_AabsX_Obj_41_RL ARC_OD_AabsX_Obj_40_RL ARC_OD_DistY_Obj_41_RL ARC_OD_VabsY_Obj_41_RL ARC_OD_AabsY_Obj_41_RL ARC_OD_DistXStd_Obj_41_RL ARC_OD_DistYStd_Obj_41_RL ARC_OD_VabsXStd_Obj_41_RL ARC_OD_VabsYStd_Obj_41_RL ARC_OD_AabsXStd_Obj_41_RL ARC_OD_Classification_Obj_41_RL ARC_OD_AabsYStd_Obj_41_RL ARC_OD_ClassConf_Obj_41_RL ARC_OD_DistY_Obj_40_RL ARC_OD_ProbOfExist_Obj_41_RL ARC_OD_DynProp_Obj_41_RL ARC_OD_Length_Obj_41_RL ARC_OD_MaintenanceState_Obj_0102 ARC_OD_Width_Obj_41_RL ARC_OD_RCS_Obj_41_RL ARC_OD_Orientation_Obj_41_RL ARC_OD_LifeCycle_Obj_41_RL ARC_OD_ObstacleProb_Obj_40_RL ARC_OD_ObstacleProb_Obj_41_RL ARC_OD_VabsY_Obj_40_RL ARC_OD_ID_40_RL ARC_OD_ID_41_RL ARC_OD_MsgCounter_Obj_40_41_RL ARC_OD_CRC8_Obj_40_41_RL ARC_OD_AabsY_Obj_40_RL ARC_OD_DistXStd_Obj_40_RL ARC_OD_DistYStd_Obj_40_RL ARC_OD_VabsXStd_Obj_40_RL ARC_OD_VabsYStd_Obj_40_RL ARC_OD_AabsXStd_Obj_40_RL;
SIG_GROUP_ 870 Signal_Group_ARC_OD_42_43 1 : ARC_OD_DistX_Obj_42_RL ARC_OD_Classification_Obj_42_RL ARC_OD_AabsYStd_Obj_42_RL ARC_OD_ClassConf_Obj_42_RL ARC_OD_ProbOfExist_Obj_42_RL ARC_OD_VabsX_Obj_42_RL ARC_OD_DynProp_Obj_42_RL ARC_OD_Length_Obj_42_RL ARC_OD_MaintenanceState_Obj_0103 ARC_OD_Width_Obj_42_RL ARC_OD_RCS_Obj_42_RL ARC_OD_Orientation_Obj_42_RL ARC_OD_LifeCycle_Obj_42_RL ARC_OD_DistX_Obj_43_RL ARC_OD_VabsX_Obj_43_RL ARC_OD_AabsX_Obj_43_RL ARC_OD_AabsX_Obj_42_RL ARC_OD_DistY_Obj_43_RL ARC_OD_VabsY_Obj_43_RL ARC_OD_AabsY_Obj_43_RL ARC_OD_DistXStd_Obj_43_RL ARC_OD_DistYStd_Obj_43_RL ARC_OD_VabsXStd_Obj_43_RL ARC_OD_VabsYStd_Obj_43_RL ARC_OD_AabsXStd_Obj_43_RL ARC_OD_Classification_Obj_43_RL ARC_OD_AabsYStd_Obj_43_RL ARC_OD_ClassConf_Obj_43_RL ARC_OD_DistY_Obj_42_RL ARC_OD_ProbOfExist_Obj_43_RL ARC_OD_DynProp_Obj_43_RL ARC_OD_Length_Obj_43_RL ARC_OD_MaintenanceState_Obj_0104 ARC_OD_Width_Obj_43_RL ARC_OD_RCS_Obj_43_RL ARC_OD_Orientation_Obj_43_RL ARC_OD_LifeCycle_Obj_43_RL ARC_OD_ObstacleProb_Obj_42_RL ARC_OD_ObstacleProb_Obj_43_RL ARC_OD_VabsY_Obj_42_RL ARC_OD_ID_42_RL ARC_OD_ID_43_RL ARC_OD_MsgCounter_Obj_42_43_RL ARC_OD_CRC8_Obj_42_43_RL ARC_OD_AabsY_Obj_42_RL ARC_OD_DistXStd_Obj_42_RL ARC_OD_DistYStd_Obj_42_RL ARC_OD_VabsXStd_Obj_42_RL ARC_OD_VabsYStd_Obj_42_RL ARC_OD_AabsXStd_Obj_42_RL;
SIG_GROUP_ 871 Signal_Group_ARC_OD_44_45 1 : ARC_OD_AabsXStd_Obj_44_RL ARC_OD_VabsYStd_Obj_44_RL ARC_OD_VabsXStd_Obj_44_RL ARC_OD_DistYStd_Obj_44_RL ARC_OD_DistXStd_Obj_44_RL ARC_OD_AabsY_Obj_44_RL ARC_OD_CRC8_Obj_44_45_RL ARC_OD_MsgCounter_Obj_44_45_RL ARC_OD_ID_45_RL ARC_OD_ID_44_RL ARC_OD_VabsY_Obj_44_RL ARC_OD_ObstacleProb_Obj_45_RL ARC_OD_ObstacleProb_Obj_44_RL ARC_OD_LifeCycle_Obj_45_RL ARC_OD_Orientation_Obj_45_RL ARC_OD_RCS_Obj_45_RL ARC_OD_Width_Obj_45_RL ARC_OD_MaintenanceState_Obj_0106 ARC_OD_Length_Obj_45_RL ARC_OD_DynProp_Obj_45_RL ARC_OD_ProbOfExist_Obj_45_RL ARC_OD_DistY_Obj_44_RL ARC_OD_ClassConf_Obj_45_RL ARC_OD_AabsYStd_Obj_45_RL ARC_OD_Classification_Obj_45_RL ARC_OD_AabsXStd_Obj_45_RL ARC_OD_VabsYStd_Obj_45_RL ARC_OD_VabsXStd_Obj_45_RL ARC_OD_DistYStd_Obj_45_RL ARC_OD_DistXStd_Obj_45_RL ARC_OD_AabsY_Obj_45_RL ARC_OD_VabsY_Obj_45_RL ARC_OD_DistY_Obj_45_RL ARC_OD_AabsX_Obj_44_RL ARC_OD_AabsX_Obj_45_RL ARC_OD_VabsX_Obj_45_RL ARC_OD_DistX_Obj_45_RL ARC_OD_LifeCycle_Obj_44_RL ARC_OD_Orientation_Obj_44_RL ARC_OD_RCS_Obj_44_RL ARC_OD_Width_Obj_44_RL ARC_OD_MaintenanceState_Obj_0105 ARC_OD_Length_Obj_44_RL ARC_OD_DynProp_Obj_44_RL ARC_OD_VabsX_Obj_44_RL ARC_OD_ProbOfExist_Obj_44_RL ARC_OD_ClassConf_Obj_44_RL ARC_OD_AabsYStd_Obj_44_RL ARC_OD_Classification_Obj_44_RL ARC_OD_DistX_Obj_44_RL;
SIG_GROUP_ 872 Signal_Group_ARC_OD_46_47 1 : ARC_OD_DistX_Obj_46_RL ARC_OD_Classification_Obj_46_RL ARC_OD_AabsYStd_Obj_46_RL ARC_OD_ClassConf_Obj_46_RL ARC_OD_ProbOfExist_Obj_46_RL ARC_OD_VabsX_Obj_46_RL ARC_OD_DynProp_Obj_46_RL ARC_OD_Length_Obj_46_RL ARC_OD_MaintenanceState_Obj_0107 ARC_OD_Width_Obj_46_RL ARC_OD_RCS_Obj_46_RL ARC_OD_Orientation_Obj_46_RL ARC_OD_LifeCycle_Obj_46_RL ARC_OD_DistX_Obj_47_RL ARC_OD_VabsX_Obj_47_RL ARC_OD_AabsX_Obj_47_RL ARC_OD_AabsX_Obj_46_RL ARC_OD_DistY_Obj_47_RL ARC_OD_VabsY_Obj_47_RL ARC_OD_AabsY_Obj_47_RL ARC_OD_DistXStd_Obj_47_RL ARC_OD_DistYStd_Obj_47_RL ARC_OD_VabsXStd_Obj_47_RL ARC_OD_VabsYStd_Obj_47_RL ARC_OD_AabsXStd_Obj_47_RL ARC_OD_Classification_Obj_47_RL ARC_OD_AabsYStd_Obj_47_RL ARC_OD_ClassConf_Obj_47_RL ARC_OD_DistY_Obj_46_RL ARC_OD_ProbOfExist_Obj_47_RL ARC_OD_DynProp_Obj_47_RL ARC_OD_Length_Obj_47_RL ARC_OD_MaintenanceState_Obj_0108 ARC_OD_Width_Obj_47_RL ARC_OD_RCS_Obj_47_RL ARC_OD_Orientation_Obj_47_RL ARC_OD_LifeCycle_Obj_47_RL ARC_OD_ObstacleProb_Obj_46_RL ARC_OD_ObstacleProb_Obj_47_RL ARC_OD_VabsY_Obj_46_RL ARC_OD_ID_46_RL ARC_OD_ID_47_RL ARC_OD_MsgCounter_Obj_46_47_RL ARC_OD_CRC8_Obj_46_47_RL ARC_OD_AabsY_Obj_46_RL ARC_OD_DistXStd_Obj_46_RL ARC_OD_DistYStd_Obj_46_RL ARC_OD_VabsXStd_Obj_46_RL ARC_OD_VabsYStd_Obj_46_RL ARC_OD_AabsXStd_Obj_46_RL;
SIG_GROUP_ 873 Signal_Group_ARC_OD_48_49 1 : ARC_OD_DistX_Obj_48_RL ARC_OD_Classification_Obj_48_RL ARC_OD_AabsYStd_Obj_48_RL ARC_OD_ClassConf_Obj_48_RL ARC_OD_ProbOfExist_Obj_48_RL ARC_OD_VabsX_Obj_48_RL ARC_OD_DynProp_Obj_48_RL ARC_OD_Length_Obj_48_RL ARC_OD_MaintenanceState_Obj_0109 ARC_OD_Width_Obj_48_RL ARC_OD_RCS_Obj_48_RL ARC_OD_Orientation_Obj_48_RL ARC_OD_LifeCycle_Obj_48_RL ARC_OD_DistX_Obj_49_RL ARC_OD_VabsX_Obj_49_RL ARC_OD_AabsX_Obj_49_RL ARC_OD_AabsX_Obj_48_RL ARC_OD_DistY_Obj_49_RL ARC_OD_VabsY_Obj_49_RL ARC_OD_AabsY_Obj_49_RL ARC_OD_DistXStd_Obj_49_RL ARC_OD_DistYStd_Obj_49_RL ARC_OD_VabsXStd_Obj_49_RL ARC_OD_VabsYStd_Obj_49_RL ARC_OD_AabsXStd_Obj_49_RL ARC_OD_Classification_Obj_49_RL ARC_OD_AabsYStd_Obj_49_RL ARC_OD_ClassConf_Obj_49_RL ARC_OD_DistY_Obj_48_RL ARC_OD_ProbOfExist_Obj_49_RL ARC_OD_DynProp_Obj_49_RL ARC_OD_Length_Obj_49_RL ARC_OD_MaintenanceState_Obj_0110 ARC_OD_Width_Obj_49_RL ARC_OD_RCS_Obj_49_RL ARC_OD_Orientation_Obj_49_RL ARC_OD_LifeCycle_Obj_49_RL ARC_OD_ObstacleProb_Obj_48_RL ARC_OD_ObstacleProb_Obj_49_RL ARC_OD_VabsY_Obj_48_RL ARC_OD_ID_48_RL ARC_OD_ID_49_RL ARC_OD_MsgCounter_Obj_48_49_RL ARC_OD_CRC8_Obj_48_49_RL ARC_OD_AabsY_Obj_48_RL ARC_OD_DistXStd_Obj_48_RL ARC_OD_DistYStd_Obj_48_RL ARC_OD_VabsXStd_Obj_48_RL ARC_OD_VabsYStd_Obj_48_RL ARC_OD_AabsXStd_Obj_48_RL;
SIG_GROUP_ 874 Signal_Group_ARC_OD_50_51 1 : ARC_OD_DistX_Obj_50_RL ARC_OD_Classification_Obj_50_RL ARC_OD_AabsYStd_Obj_50_RL ARC_OD_ClassConf_Obj_50_RL ARC_OD_ProbOfExist_Obj_50_RL ARC_OD_VabsX_Obj_50_RL ARC_OD_DynProp_Obj_50_RL ARC_OD_Length_Obj_50_RL ARC_OD_MaintenanceState_Obj_0111 ARC_OD_Width_Obj_50_RL ARC_OD_RCS_Obj_50_RL ARC_OD_Orientation_Obj_50_RL ARC_OD_LifeCycle_Obj_50_RL ARC_OD_DistX_Obj_51_RL ARC_OD_VabsX_Obj_51_RL ARC_OD_AabsX_Obj_51_RL ARC_OD_AabsX_Obj_50_RL ARC_OD_DistY_Obj_51_RL ARC_OD_VabsY_Obj_51_RL ARC_OD_AabsY_Obj_51_RL ARC_OD_DistXStd_Obj_51_RL ARC_OD_DistYStd_Obj_51_RL ARC_OD_VabsXStd_Obj_51_RL ARC_OD_VabsYStd_Obj_51_RL ARC_OD_AabsXStd_Obj_51_RL ARC_OD_Classification_Obj_51_RL ARC_OD_AabsYStd_Obj_51_RL ARC_OD_ClassConf_Obj_51_RL ARC_OD_DistY_Obj_50_RL ARC_OD_ProbOfExist_Obj_51_RL ARC_OD_DynProp_Obj_51_RL ARC_OD_Length_Obj_51_RL ARC_OD_MaintenanceState_Obj_0112 ARC_OD_Width_Obj_51_RL ARC_OD_RCS_Obj_51_RL ARC_OD_Orientation_Obj_51_RL ARC_OD_LifeCycle_Obj_51_RL ARC_OD_ObstacleProb_Obj_50_RL ARC_OD_ObstacleProb_Obj_51_RL ARC_OD_VabsY_Obj_50_RL ARC_OD_ID_50_RL ARC_OD_ID_51_RL ARC_OD_MsgCounter_Obj_50_51_RL ARC_OD_CRC8_Obj_50_51_RL ARC_OD_AabsY_Obj_50_RL ARC_OD_DistXStd_Obj_50_RL ARC_OD_DistYStd_Obj_50_RL ARC_OD_VabsXStd_Obj_50_RL ARC_OD_VabsYStd_Obj_50_RL ARC_OD_AabsXStd_Obj_50_RL;
SIG_GROUP_ 875 Signal_Group_ARC_OD_52_53 1 : ARC_OD_DistX_Obj_52_RL ARC_OD_Classification_Obj_52_RL ARC_OD_AabsYStd_Obj_52_RL ARC_OD_ClassConf_Obj_52_RL ARC_OD_ProbOfExist_Obj_52_RL ARC_OD_VabsX_Obj_52_RL ARC_OD_DynProp_Obj_52_RL ARC_OD_Length_Obj_52_RL ARC_OD_MaintenanceState_Obj_0113 ARC_OD_Width_Obj_52_RL ARC_OD_RCS_Obj_52_RL ARC_OD_Orientation_Obj_52_RL ARC_OD_LifeCycle_Obj_52_RL ARC_OD_DistX_Obj_53_RL ARC_OD_VabsX_Obj_53_RL ARC_OD_AabsX_Obj_53_RL ARC_OD_AabsX_Obj_52_RL ARC_OD_DistY_Obj_53_RL ARC_OD_VabsY_Obj_53_RL ARC_OD_AabsY_Obj_53_RL ARC_OD_DistXStd_Obj_53_RL ARC_OD_DistYStd_Obj_53_RL ARC_OD_VabsXStd_Obj_53_RL ARC_OD_VabsYStd_Obj_53_RL ARC_OD_AabsXStd_Obj_53_RL ARC_OD_Classification_Obj_53_RL ARC_OD_AabsYStd_Obj_53_RL ARC_OD_ClassConf_Obj_53_RL ARC_OD_DistY_Obj_52_RL ARC_OD_ProbOfExist_Obj_53_RL ARC_OD_DynProp_Obj_53_RL ARC_OD_Length_Obj_53_RL ARC_OD_MaintenanceState_Obj_0114 ARC_OD_Width_Obj_53_RL ARC_OD_RCS_Obj_53_RL ARC_OD_Orientation_Obj_53_RL ARC_OD_LifeCycle_Obj_53_RL ARC_OD_ObstacleProb_Obj_52_RL ARC_OD_ObstacleProb_Obj_53_RL ARC_OD_VabsY_Obj_52_RL ARC_OD_ID_52_RL ARC_OD_ID_53_RL ARC_OD_MsgCounter_Obj_52_53_RL ARC_OD_CRC8_Obj_52_53_RL ARC_OD_AabsY_Obj_52_RL ARC_OD_DistXStd_Obj_52_RL ARC_OD_DistYStd_Obj_52_RL ARC_OD_VabsXStd_Obj_52_RL ARC_OD_VabsYStd_Obj_52_RL ARC_OD_AabsXStd_Obj_52_RL;
SIG_GROUP_ 876 Signal_Group_ARC_OD_54_55 1 : ARC_OD_DistX_Obj_54_RL ARC_OD_Classification_Obj_54_RL ARC_OD_AabsYStd_Obj_54_RL ARC_OD_ClassConf_Obj_54_RL ARC_OD_ProbOfExist_Obj_54_RL ARC_OD_VabsX_Obj_54_RL ARC_OD_DynProp_Obj_54_RL ARC_OD_Length_Obj_54_RL ARC_OD_MaintenanceState_Obj_0115 ARC_OD_Width_Obj_54_RL ARC_OD_RCS_Obj_54_RL ARC_OD_Orientation_Obj_54_RL ARC_OD_LifeCycle_Obj_54_RL ARC_OD_DistX_Obj_55_RL ARC_OD_VabsX_Obj_55_RL ARC_OD_AabsX_Obj_55_RL ARC_OD_AabsX_Obj_54_RL ARC_OD_DistY_Obj_55_RL ARC_OD_VabsY_Obj_55_RL ARC_OD_AabsY_Obj_55_RL ARC_OD_DistXStd_Obj_55_RL ARC_OD_DistYStd_Obj_55_RL ARC_OD_VabsXStd_Obj_55_RL ARC_OD_VabsYStd_Obj_55_RL ARC_OD_AabsXStd_Obj_55_RL ARC_OD_Classification_Obj_55_RL ARC_OD_AabsYStd_Obj_55_RL ARC_OD_ClassConf_Obj_55_RL ARC_OD_DistY_Obj_54_RL ARC_OD_ProbOfExist_Obj_55_RL ARC_OD_DynProp_Obj_55_RL ARC_OD_Length_Obj_55_RL ARC_OD_MaintenanceState_Obj_0116 ARC_OD_Width_Obj_55_RL ARC_OD_RCS_Obj_55_RL ARC_OD_Orientation_Obj_55_RL ARC_OD_LifeCycle_Obj_55_RL ARC_OD_ObstacleProb_Obj_54_RL ARC_OD_ObstacleProb_Obj_55_RL ARC_OD_VabsY_Obj_54_RL ARC_OD_ID_54_RL ARC_OD_ID_55_RL ARC_OD_MsgCounter_Obj_54_55_RL ARC_OD_CRC8_Obj_54_55_RL ARC_OD_AabsY_Obj_54_RL ARC_OD_DistXStd_Obj_54_RL ARC_OD_DistYStd_Obj_54_RL ARC_OD_VabsXStd_Obj_54_RL ARC_OD_VabsYStd_Obj_54_RL ARC_OD_AabsXStd_Obj_54_RL;
SIG_GROUP_ 877 Signal_Group_ARC_OD_56_57 1 : ARC_OD_DistX_Obj_56_RL ARC_OD_Classification_Obj_56_RL ARC_OD_AabsYStd_Obj_56_RL ARC_OD_ClassConf_Obj_56_RL ARC_OD_ProbOfExist_Obj_56_RL ARC_OD_VabsX_Obj_56_RL ARC_OD_DynProp_Obj_56_RL ARC_OD_Length_Obj_56_RL ARC_OD_MaintenanceState_Obj_0117 ARC_OD_Width_Obj_56_RL ARC_OD_RCS_Obj_56_RL ARC_OD_Orientation_Obj_56_RL ARC_OD_LifeCycle_Obj_56_RL ARC_OD_DistX_Obj_57_RL ARC_OD_VabsX_Obj_57_RL ARC_OD_AabsX_Obj_57_RL ARC_OD_AabsX_Obj_56_RL ARC_OD_DistY_Obj_57_RL ARC_OD_VabsY_Obj_57_RL ARC_OD_AabsY_Obj_57_RL ARC_OD_DistXStd_Obj_57_RL ARC_OD_DistYStd_Obj_57_RL ARC_OD_VabsXStd_Obj_57_RL ARC_OD_VabsYStd_Obj_57_RL ARC_OD_AabsXStd_Obj_57_RL ARC_OD_Classification_Obj_57_RL ARC_OD_AabsYStd_Obj_57_RL ARC_OD_ClassConf_Obj_57_RL ARC_OD_DistY_Obj_56_RL ARC_OD_ProbOfExist_Obj_57_RL ARC_OD_DynProp_Obj_57_RL ARC_OD_Length_Obj_57_RL ARC_OD_MaintenanceState_Obj_0118 ARC_OD_Width_Obj_57_RL ARC_OD_RCS_Obj_57_RL ARC_OD_Orientation_Obj_57_RL ARC_OD_LifeCycle_Obj_57_RL ARC_OD_ObstacleProb_Obj_56_RL ARC_OD_ObstacleProb_Obj_57_RL ARC_OD_VabsY_Obj_56_RL ARC_OD_ID_56_RL ARC_OD_ID_57_RL ARC_OD_MsgCounter_Obj_56_57_RL ARC_OD_CRC8_Obj_56_57_RL ARC_OD_AabsY_Obj_56_RL ARC_OD_DistXStd_Obj_56_RL ARC_OD_DistYStd_Obj_56_RL ARC_OD_VabsXStd_Obj_56_RL ARC_OD_VabsYStd_Obj_56_RL ARC_OD_AabsXStd_Obj_56_RL;
SIG_GROUP_ 878 Signal_Group_ARC_OD_58_59 1 : ARC_OD_DistX_Obj_58_RL ARC_OD_Classification_Obj_58_RL ARC_OD_AabsYStd_Obj_58_RL ARC_OD_ClassConf_Obj_58_RL ARC_OD_ProbOfExist_Obj_58_RL ARC_OD_VabsX_Obj_58_RL ARC_OD_DynProp_Obj_58_RL ARC_OD_Length_Obj_58_RL ARC_OD_MaintenanceState_Obj_0119 ARC_OD_Width_Obj_58_RL ARC_OD_RCS_Obj_58_RL ARC_OD_Orientation_Obj_58_RL ARC_OD_LifeCycle_Obj_58_RL ARC_OD_DistX_Obj_59_RL ARC_OD_VabsX_Obj_59_RL ARC_OD_AabsX_Obj_59_RL ARC_OD_AabsX_Obj_58_RL ARC_OD_DistY_Obj_59_RL ARC_OD_VabsY_Obj_59_RL ARC_OD_AabsY_Obj_59_RL ARC_OD_DistXStd_Obj_59_RL ARC_OD_DistYStd_Obj_59_RL ARC_OD_VabsXStd_Obj_59_RL ARC_OD_VabsYStd_Obj_59_RL ARC_OD_AabsXStd_Obj_59_RL ARC_OD_Classification_Obj_59_RL ARC_OD_AabsYStd_Obj_59_RL ARC_OD_ClassConf_Obj_59_RL ARC_OD_DistY_Obj_58_RL ARC_OD_ProbOfExist_Obj_59_RL ARC_OD_DynProp_Obj_59_RL ARC_OD_Length_Obj_59_RL ARC_OD_MaintenanceState_Obj_0120 ARC_OD_Width_Obj_59_RL ARC_OD_RCS_Obj_59_RL ARC_OD_Orientation_Obj_59_RL ARC_OD_LifeCycle_Obj_59_RL ARC_OD_ObstacleProb_Obj_58_RL ARC_OD_ObstacleProb_Obj_59_RL ARC_OD_VabsY_Obj_58_RL ARC_OD_ID_58_RL ARC_OD_ID_59_RL ARC_OD_MsgCounter_Obj_58_59_RL ARC_OD_CRC8_Obj_58_59_RL ARC_OD_AabsY_Obj_58_RL ARC_OD_DistXStd_Obj_58_RL ARC_OD_DistYStd_Obj_58_RL ARC_OD_VabsXStd_Obj_58_RL ARC_OD_VabsYStd_Obj_58_RL ARC_OD_AabsXStd_Obj_58_RL;
SIG_GROUP_ 266 Signal_Group_ESC_FrP02_10A 1 : ESC_RLWhlDirV ESC_RRWhlDirV ESC_RRWhlSpd ESC_RRWhlDir ESC_RRWhlSpdV ESC_RLWhlSpd ESC_RLWhlDir ESC_RLWhlSpdV ESC_FrP02_10A_RC ESC_FrP02_10A_CRC;
SIG_GROUP_ 268 Signal_Group_ESC_FrP04_10C 1 : ESC_FLWhlDirV ESC_FRWhlDirV ESC_FLWhlSpd ESC_FLWhlDir ESC_FLWhlSpdV ESC_FRWhlSpd ESC_FRWhlDir ESC_FRWhlSpdV ESC_FrP04_10C_RC ESC_FrP04_10C_CRC;
SIG_GROUP_ 271 Signal_Group_ESC_FrP07_10F 1 : ESC_LgtAccel ESC_LatAccelSenVal ESC_YR ESC_LgtSenSt ESC_YRSenSts ESC_LatSenSts;
SIG_GROUP_ 277 Signal_Group_EPS_FrP01_115 1 : EPS_StrgWhlAnglV EPS_FrP01_115_CRC EPS_StrgAnglSpd EPS_FrP01_115_RC EPS_StrgWhlAngl EPS_StrgAnglSpdV EPS_StrgWhlAnglSenCalSts;
SIG_GROUP_ 805 Signal_Group_ESC_FrP08_325 1 : ESC_VDCCtrlActv ESC_VehSpdV ESC_VehSpd;
SIG_GROUP_ 834 Signal_Group_ICM_FrP02_342 1 : ICM_TotOdo ICM_VehSpdDisp ICM_TotOdoV ICM_VehSpdDispV;
SIG_GROUP_ 267 Signal_Group_ESC_FrP03_10B 1 : ESC_FrP03_10B_RC_4 ESC_FrP03_10B_CRC_4 ESC_FrP03_10B_RC_3 ESC_FrP03_10B_CRC_3 ESC_ABAActv ESC_ABAAvlbl ESC_Off ESC_HDCSts ESC_FrP03_10B_RC_2 ESC_FrP03_10B_CRC_2 ESC_CDPActv ESC_ESCFld ESC_ABSActv ESC_TCSActv ESC_FrP03_10B_RC_1 ESC_EBDActv ESC_FrP03_10B_CRC_1;
SIG_GROUP_ 269 Signal_Group_ESC_FrP05_10D 1 : ESC_VehStdslStsV ESC_VehStdslSts;
SIG_GROUP_ 181 Signal_Group_EHB_FrP01_B5 1 : EHB_CtrlrFltSts EHB_BrkPedlAppldSts EHB_BrkPedlAppld EHB_FrP01_B5_RC EHB_FrP01_B5_CRC;
